VERSION ""

NS_ :

BS_:

BU_: Receiver ChassisBus VehicleBus PartyBus ETH GTW
VAL_TABLE_ OilPumpState 7 "OIL_PUMP_SNA" 6 "OIL_PUMP_FAULTED" 2 "OIL_PUMP_COLD_STARTUP" 1 "OIL_PUMP_ENABLE" 0 "OIL_PUMP_STANDBY" ;

BO_ 3221225472 VECTOR__INDEPENDENT_SIG_MSG: 0 Vector__XXX
 SG_ FrontAxleRPM___ : 0|16@1- (0.1,0) [-3276.8|3276.7] "RPM" Vector__XXX
 SG_ Rear12vInverter266 : 0|8@1+ (0.1,0) [0|25.5] "Volts" Vector__XXX
 SG_ Front12vInverter2E5 : 0|8@1+ (0.1,0) [0|25.5] "Volts" Vector__XXX

BO_ 955 ID3BBUI_power: 2 VehicleBus
 SG_ UI_powerExpected : 0|8@1+ (1,0) [0|100] "kW"  Receiver
 SG_ UI_powerIdeal : 8|8@1+ (1,0) [0|100] "kW"  Receiver

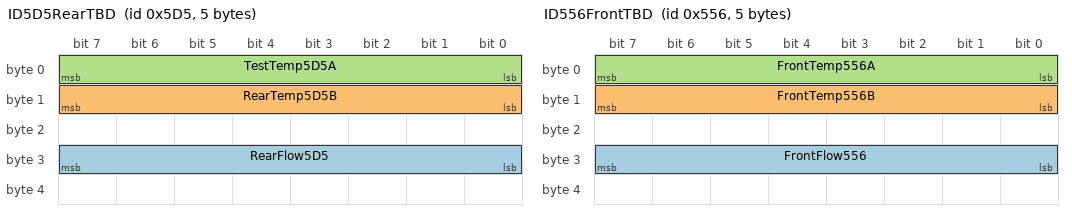
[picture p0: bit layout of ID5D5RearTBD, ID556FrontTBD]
BO_ 1493 ID5D5RearTBD: 5 VehicleBus
 SG_ RearFlow5D5 : 24|8@1+ (0.2,0) [0|0] "LPM"  Receiver
 SG_ RearTemp5D5B : 8|8@1+ (1,-40) [-40|215] "C"  Receiver
 SG_ TestTemp5D5A : 0|8@1+ (1,-40) [-40|215] "C"  Receiver

BO_ 1366 ID556FrontTBD: 5 VehicleBus
 SG_ FrontFlow556 : 24|8@1+ (0.2,0) [0|0] "LPM"  Receiver
 SG_ FrontTemp556B : 8|8@1+ (1,-40) [-40|215] "C"  Receiver
 SG_ FrontTemp556A : 0|8@1+ (1,-40) [-40|215] "C"  Receiver

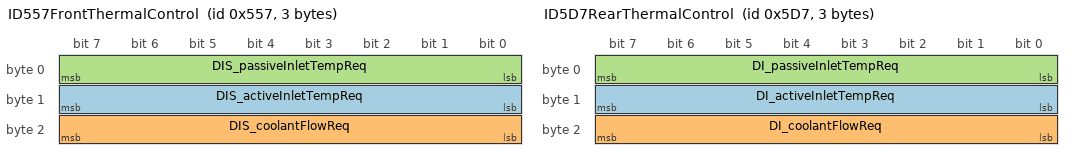
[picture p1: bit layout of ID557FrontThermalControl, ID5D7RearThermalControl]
BO_ 1367 ID557FrontThermalControl: 3 VehicleBus
 SG_ DIS_activeInletTempReq : 8|8@1+ (1,-40) [-40|120] "C"  Receiver
 SG_ DIS_coolantFlowReq : 16|8@1+ (0.2,0) [0|50] "LPM"  Receiver
 SG_ DIS_passiveInletTempReq : 0|8@1+ (1,-40) [-40|120] "C"  Receiver

BO_ 1495 ID5D7RearThermalControl: 3 VehicleBus
 SG_ DI_activeInletTempReq : 8|8@1+ (1,-40) [-40|120] "C"  Receiver
 SG_ DI_coolantFlowReq : 16|8@1+ (0.2,0) [0|50] "LPM"  Receiver
 SG_ DI_passiveInletTempReq : 0|8@1+ (1,-40) [-40|120] "C"  Receiver

BO_ 2005 ID7D5DI_debug: 8 VehicleBus
 SG_ DI_debugSelector M : 0|8@1+ (1,0) [0|255] ""  Receiver
 SG_ DI_aebCancelReason m45 : 32|8@1+ (1,0) [0|255] ""  Receiver
 SG_ DI_aebFaultReason m45 : 16|4@1+ (1,0) [0|15] ""  Receiver
 SG_ DI_aebUnavailableReason m45 : 24|4@1+ (1,0) [0|9] ""  Receiver
 SG_ DI_brakeCpScale m2 : 16|9@1- (0.01,0.5) [-1|2] "N/N"  Receiver
 SG_ DI_brakeSwitchNC m42 : 63|1@1+ (1,0) [0|1] ""  Receiver
 SG_ DI_brakeSwitchNO m42 : 62|1@1+ (1,0) [0|1] ""  Receiver
 SG_ DI_brkStState m50 : 24|3@1+ (1,0) [0|6] ""  Receiver
 SG_ DI_busbarTemp m64 : 16|8@1+ (1,-40) [-40|215] "C"  Receiver
 SG_ DI_controlStack m67 : 56|8@1+ (0.4,0) [0|100] "%"  Receiver
 SG_ DI_cpu100HzAvg m66 : 48|8@1+ (0.4,0) [0|102] "%"  Receiver
 SG_ DI_cpu100HzMax m66 : 40|8@1+ (0.4,0) [0|102] "%"  Receiver
 SG_ DI_cpu100HzMin m66 : 32|8@1+ (0.4,0) [0|102] "%"  Receiver
 SG_ DI_cpu10HzAvg m66 : 24|8@1+ (0.4,0) [0|102] "%"  Receiver
 SG_ DI_cpu10HzMax m66 : 16|8@1+ (0.4,0) [0|102] "%"  Receiver
 SG_ DI_cpu10HzMin m66 : 8|8@1+ (0.4,0) [0|102] "%"  Receiver
 SG_ DI_cpu1HzAvg m128 : 32|8@1+ (0.4,0) [0|102] "%"  Receiver
 SG_ DI_cpu1HzMax m128 : 24|8@1+ (0.4,0) [0|102] "%"  Receiver
 SG_ DI_cpu1HzMin m128 : 16|8@1+ (0.4,0) [0|102] "%"  Receiver
 SG_ DI_cpu1kHzAvg m67 : 24|8@1+ (0.4,0) [0|102] "%"  Receiver
 SG_ DI_cpu1kHzMax m67 : 16|8@1+ (0.4,0) [0|102] "%"  Receiver
 SG_ DI_cpu1kHzMin m67 : 8|8@1+ (0.4,0) [0|102] "%"  Receiver
 SG_ DI_cpu20kHzAvg m67 : 48|8@1+ (0.4,0) [0|102] "%"  Receiver
 SG_ DI_cpu20kHzMax m67 : 40|8@1+ (0.4,0) [0|102] "%"  Receiver
 SG_ DI_cpu20kHzMin m67 : 32|8@1+ (0.4,0) [0|102] "%"  Receiver
 SG_ DI_cpuIDWord0 m131 : 16|16@1+ (1,0) [0|65535] ""  Receiver
 SG_ DI_cpuIDWord1 m132 : 16|16@1+ (1,0) [0|65535] ""  Receiver
 SG_ DI_cpuIDWord2 m132 : 32|16@1+ (1,0) [0|65535] ""  Receiver
 SG_ DI_cpuIDWord3 m132 : 48|16@1+ (1,0) [0|65535] ""  Receiver
 SG_ DI_crc m131 : 32|32@1+ (1,0) [0|4294967295] ""  Receiver
 SG_ DI_currentLimit m41 : 32|16@1+ (0.1,0) [0|6553.5] "A"  Receiver
 SG_ DI_dcCableCurrentEst m37 : 16|16@1- (0.1,0) [-3276.8|3276.7] "A"  Receiver
 SG_ DI_dcCableHeat m47 : 24|16@1+ (0.001,0) [0|65.535] "kA2s"  Receiver
 SG_ DI_dcCapTemp m64 : 8|8@1+ (1,-40) [-40|215] "C"  Receiver
 SG_ DI_dcLinkCapTemp m70 : 32|8@1+ (1,-40) [-40|215] "C"  Receiver
 SG_ DI_decodeHardwareStack m68 : 24|8@1+ (0.4,0) [0|100] "%"  Receiver
 SG_ DI_driveUnitOdometer m69 : 32|32@1+ (10,0) [0|42949672950] "rev"  Receiver
 SG_ DI_eepromStack m68 : 32|8@1+ (0.4,0) [0|100] "%"  Receiver
 SG_ DI_fluxState m42 : 16|4@1+ (1,0) [0|10] ""  Receiver
 SG_ DI_gainScale m37 : 8|8@1+ (0.01,0) [0|2.55] "scale"  Receiver
 SG_ DI_gateDriveState m50 : 10|3@1+ (1,0) [0|4] ""  Receiver
 SG_ DI_gateDriveSupplyState m50 : 8|2@1+ (1,0) [0|3] ""  Receiver
 SG_ DI_hvDcCableTemp m70 : 40|8@1+ (1,-40) [-40|215] "C"  Receiver
 SG_ DI_hwFaultCounter m69 : 8|4@1+ (1,0) [0|15] ""  Receiver
 SG_ DI_idleStack m68 : 16|8@1+ (0.4,0) [0|100] "%"  Receiver
 SG_ DI_immobilizerCondition m64 : 63|1@1+ (1,0) [0|1] ""  Receiver
 SG_ DI_immobilizerStack m68 : 56|8@1+ (0.4,0) [0|100] "%"  Receiver
 SG_ DI_internalAngleFilt m37 : 48|16@1+ (0.0003,0) [0|8] "rad"  Receiver
 SG_ DI_llrScale m42 : 32|8@1+ (0.015,0) [0|3.825] "scale"  Receiver
 SG_ DI_llsScale m42 : 24|8@1+ (0.004,0) [0|1.02] "scale"  Receiver
 SG_ DI_lmScale m36 : 8|8@1+ (0.004,0) [0|1.02] "scale"  Receiver
 SG_ DI_loadAngle m42 : 40|16@1- (0.0003,0) [-4|4] "rad"  Receiver
 SG_ DI_loadAngleMargin m37 : 32|16@1- (0.0003,0) [-4|4] "rad"  Receiver
 SG_ DI_magnetTempEst m47 : 40|8@1+ (1,-40) [-40|180] "C"  Receiver
 SG_ DI_module10HzStack m66 : 56|8@1+ (0.4,0) [0|100] "%"  Receiver
 SG_ DI_motorIA m32 : 16|16@1+ (0.1,0) [0|6553.5] "A"  Receiver
 SG_ DI_motorIAavg m38 : 32|16@1- (0.1,0) [-3276.8|3276.7] "A"  Receiver
 SG_ DI_motorIB m32 : 32|16@1+ (0.1,0) [0|6553.5] "A"  Receiver
 SG_ DI_motorIBavg m38 : 48|16@1- (0.1,0) [-3276.8|3276.7] "A"  Receiver
 SG_ DI_motorIC m32 : 48|16@1+ (0.1,0) [0|6553.5] "A"  Receiver
 SG_ DI_motorType m128 : 8|5@1+ (1,0) [0|26] ""  Receiver
 SG_ DI_motorV m34 : 48|16@1+ (2E-005,0) [0|1.3107] "mindex"  Receiver
 SG_ DI_muSurfHigh m2 : 8|8@1+ (0.005,0) [0|1.2] "N/N"  Receiver
 SG_ DI_negDcBusbarTemp m70 : 48|8@1+ (1,-40) [-40|215] "C"  Receiver
 SG_ DI_offsetA m32 : 8|8@1- (0.1,0) [-12.8|12.7] "A"  Receiver
 SG_ DI_offsetB m33 : 8|8@1- (0.1,0) [-12.8|12.7] "A"  Receiver
 SG_ DI_oilPumpMotorSpeed m46 : 8|8@1+ (40,0) [0|10200] "RPM"  Receiver
 SG_ DI_oilPumpPhaseAdvance m46 : 24|8@1+ (0.4,0) [0|100] "%"  Receiver
 SG_ DI_oilPumpPhaseVoltage m46 : 16|8@1+ (0.1,0) [0|25.4] "V"  Receiver
 SG_ DI_oilPumpPressureEstimateMax m46 : 32|8@1+ (2,0) [0|500] "kPa"  Receiver
 SG_ DI_oilPumpPressureExpectedMin m46 : 40|8@1+ (2,0) [0|500] "kPa"  Receiver
 SG_ DI_opdUnavailableReason m45 : 40|4@1+ (1,0) [0|11] ""  Receiver
 SG_ DI_pcsTemp m64 : 24|8@1+ (1,-40) [-40|215] "C"  Receiver
 SG_ DI_peakFlux m36 : 48|16@1+ (0.0001,0) [0|6.5535] "Wb"  Receiver
 SG_ DI_peakIQref m38 : 16|16@1+ (0.1,0) [0|6553.5] "A"  Receiver
 SG_ DI_pedalPosFilt m2 : 32|8@1+ (0.4,0) [0|100] "%"  Receiver
 SG_ DI_phaseOutBusbarTemp m70 : 8|8@1+ (1,-40) [-40|215] "C"  Receiver
 SG_ DI_phaseOutBusbarWeldTemp m70 : 16|8@1+ (1,-40) [-40|215] "C"  Receiver
 SG_ DI_phaseOutLugTemp m70 : 24|8@1+ (1,-40) [-40|215] "C"  Receiver
 SG_ DI_posDcBusbarTemp m70 : 56|8@1+ (1,-40) [-40|215] "C"  Receiver
 SG_ DI_powerStageSafeState m50 : 13|2@1+ (1,0) [0|3] ""  Receiver
 SG_ DI_pwrSatChargeCurrent m42 : 8|8@1+ (0.4,0) [0|102] "%"  Receiver
 SG_ DI_pwrSatDischargeCurrent m40 : 8|8@1+ (0.4,0) [0|102] "%"  Receiver
 SG_ DI_pwrSatMaxBusVoltage m39 : 48|8@1+ (0.4,0) [0|102] "%"  Receiver
 SG_ DI_pwrSatMaxDischargePower m39 : 16|8@1+ (0.4,0) [0|102] "%"  Receiver
 SG_ DI_pwrSatMaxRegenPower m39 : 24|8@1+ (0.4,0) [0|102] "%"  Receiver
 SG_ DI_pwrSatMinBusVoltage m39 : 56|8@1+ (0.4,0) [0|102] "%"  Receiver
 SG_ DI_resolverClaMIA m48 : 43|1@1+ (1,0) [0|1] ""  Receiver
 SG_ DI_resolverCommonGain m48 : 32|8@1+ (0.025,0) [0|5] "1"  Receiver
 SG_ DI_resolverCosFiltered m52 : 32|8@1- (0.01,0) [-1|1] "1"  Receiver
 SG_ DI_resolverCosRmsSquared m52 : 16|8@1+ (0.005,0) [0|1] "1"  Receiver
 SG_ DI_resolverErrorRmsSquared m52 : 48|8@1+ (0.005,0) [0|1] "1"  Receiver
 SG_ DI_resolverNoCarrier m48 : 41|1@1+ (1,0) [0|1] ""  Receiver
 SG_ DI_resolverNoPhaseLock m48 : 42|1@1+ (1,0) [0|1] ""  Receiver
 SG_ DI_resolverOffsetCos m48 : 8|8@1+ (0.015,0) [0|3.3] "V"  Receiver
 SG_ DI_resolverOffsetSin m48 : 16|8@1+ (0.015,0) [0|3.3] "V"  Receiver
 SG_ DI_resolverPhaseOffset m48 : 24|8@1+ (0.1,7.5) [7.5|32.5] "us"  Receiver
 SG_ DI_resolverReady m48 : 40|1@1+ (1,0) [0|1] ""  Receiver
 SG_ DI_resolverSinFiltered m52 : 40|8@1- (0.01,0) [-1|1] "1"  Receiver
 SG_ DI_resolverSinRmsSquared m52 : 24|8@1+ (0.005,0) [0|1] "1"  Receiver
 SG_ DI_rotorFlux m47 : 8|16@1+ (0.0001,0) [0|6.5535] "Wb"  Receiver
 SG_ DI_rotorMaxMagnetTemp m72 : 16|8@1+ (1,-40) [-40|215] "C"  Receiver
 SG_ DI_rotorOffsetEst m43 : 8|12@1- (0.01,0) [-20|20] "deg"  Receiver
 SG_ DI_rotorOffsetLearningState m63 : 8|4@1+ (1,0) [0|9] ""  Receiver
 SG_ DI_rotorOffsetMean m43 : 20|12@1- (0.01,0) [-20|20] "deg"  Receiver
 SG_ DI_rsScale m34 : 8|8@1+ (0.01,0) [0|2.55] "scale"  Receiver
 SG_ DI_soptMaxCurrentMagSqrd m49 : 40|16@1+ (100,0) [0|6553500] "A2"  Receiver
 SG_ DI_soptTimeToOff m49 : 24|11@1+ (0.05,0) [0|100] "ms"  Receiver
 SG_ DI_soptTimeToTrip m49 : 8|8@1+ (0.05,0) [0|10] "ms"  Receiver
 SG_ DI_soptTripDelay m49 : 16|8@1+ (0.05,0) [0|10] "ms"  Receiver
 SG_ DI_ssmState m38 : 8|4@1+ (1,0) [0|8] ""  Receiver
 SG_ DI_statorEndWindingTemp m72 : 8|8@1+ (1,-40) [-40|215] "C"  Receiver
 SG_ DI_statorFluxFdb m35 : 32|16@1+ (0.0001,0) [0|6.5535] "Wb"  Receiver
 SG_ DI_statorFluxRef m35 : 16|16@1+ (0.0001,0) [0|6.5535] "Wb"  Receiver
 SG_ DI_statorIDfdb m33 : 32|16@1- (0.1,0) [-3276.8|3276.7] "A"  Receiver
 SG_ DI_statorIDref m33 : 16|16@1- (0.1,0) [-3276.8|3276.7] "A"  Receiver
 SG_ DI_statorIQfdb m34 : 32|16@1- (0.1,0) [-3276.8|3276.7] "A"  Receiver
 SG_ DI_statorIQref m34 : 16|16@1- (0.1,0) [-3276.8|3276.7] "A"  Receiver
 SG_ DI_statorResistanceEst m47 : 48|11@1+ (5E-005,0) [0|0.10235] "Ohm"  Receiver
 SG_ DI_statorTemp1 m64 : 32|8@1+ (1,-40) [-40|215] "C"  Receiver
 SG_ DI_statorTemp2 m64 : 40|8@1+ (1,-40) [-40|215] "C"  Receiver
 SG_ DI_statorVD m36 : 32|16@1- (4E-005,0) [-1.31072|1.31068] "mindex"  Receiver
 SG_ DI_statorVDFiltered m63 : 16|16@1- (4E-005,0) [-1.31072|1.31068] "mindex"  Receiver
 SG_ DI_statorVQ m36 : 16|16@1- (4E-005,0) [-1.31072|1.31068] "mindex"  Receiver
 SG_ DI_statorVQFiltered m63 : 32|16@1- (4E-005,0) [-1.31072|1.31068] "mindex"  Receiver
 SG_ DI_sysHeatPowerOptimal m50 : 16|8@1+ (0.08,0) [0|20] "kW"  Receiver
 SG_ DI_sysPedalMaxTorque m44 : 22|14@1+ (0.1,0) [0|1638.3] "Nm"  Receiver
 SG_ DI_sysPedalMinTorque m44 : 8|14@1+ (0.1,-1638.3) [-1638.3|0] "Nm"  Receiver
 SG_ DI_sysPostPedalMaxTorque m44 : 50|14@1+ (0.1,0) [0|1638.3] "Nm"  Receiver
 SG_ DI_sysPostPedalMinTorque m44 : 36|14@1+ (0.1,-1638.3) [-1638.3|0] "Nm"  Receiver
 SG_ DI_systemStack m68 : 8|8@1+ (0.4,0) [0|100] "%"  Receiver
 SG_ DI_systemTorqueCommand m35 : 48|16@1- (0.035,0) [-1146.88|1146.845] "Nm"  Receiver
 SG_ DI_tcMaxRequest m40 : 16|8@1+ (5,0) [0|1275] "Nm"  Receiver
 SG_ DI_tcMinRequest m40 : 24|8@1+ (5,0) [0|1275] "Nm"  Receiver
 SG_ DI_torquePedalMax m51 : 28|12@1+ (2,0) [0|7500] "Nm"  Receiver
 SG_ DI_torquePedalMin m51 : 16|12@1+ (2,-7500) [-7500|0] "Nm"  Receiver
 SG_ DI_torquePerAmp m33 : 48|16@1+ (0.0001,0) [0|6.5535] "Nm/A"  Receiver
 SG_ DI_torquePostPedalMax m51 : 52|12@1+ (2,0) [0|7500] "Nm"  Receiver
 SG_ DI_torquePostPedalMin m51 : 40|12@1+ (2,-7500) [-7500|0] "Nm"  Receiver
 SG_ DI_tqSatMotorCurrent m39 : 40|8@1+ (0.4,0) [0|102] "%"  Receiver
 SG_ DI_tqSatMotorVoltage m39 : 32|8@1+ (0.4,0) [0|102] "%"  Receiver
 SG_ DI_tqSatThermal m39 : 8|8@1+ (0.4,0) [0|102] "%"  Receiver
 SG_ DI_tqSatUiDriveTorque m40 : 32|8@1+ (0.4,0) [0|102] "%"  Receiver
 SG_ DI_tqSatUiRegenTorque m40 : 40|8@1+ (0.4,0) [0|102] "%"  Receiver
 SG_ DI_tqScaleDifferential m35 : 8|8@1+ (0.4,0) [0|102] "%"  Receiver
 SG_ DI_tqScaleMaxMotorSpeed m40 : 48|8@1+ (0.4,0) [0|102] "%"  Receiver
 SG_ DI_tqScaleShift m40 : 56|8@1+ (0.4,0) [0|102] "%"  Receiver
 SG_ DI_udsStack m68 : 40|8@1+ (0.4,0) [0|100] "%"  Receiver
 SG_ DI_usmState m38 : 12|3@1+ (1,0) [0|7] ""  Receiver
 SG_ DI_veMassInvRaw m41 : 8|12@1+ (1E-007,0.0001) [0.0001|0.0005] "1/kg"  Receiver
 SG_ DI_veResForce m41 : 20|12@1- (0.0005,0) [-1.024|1.0235] "G"  Receiver
 SG_ DI_velocityEstimatorState m65 : 8|3@1+ (1,0) [0|4] ""  Receiver
 SG_ DI_wasteCurrentLimit m41 : 48|16@1+ (0.1,0) [0|6553.5] "A"  Receiver
 SG_ DI_xcpStack m68 : 48|8@1+ (0.4,0) [0|100] "%"  Receiver

BO_ 1879 ID757DIS_debug: 8 VehicleBus
 SG_ DIS_debugSelector M : 0|8@1+ (1,0) [0|255] ""  Receiver
 SG_ DIS_brakeSwitchNC m42 : 63|1@1+ (1,0) [0|1] ""  Receiver
 SG_ DIS_brakeSwitchNO m42 : 62|1@1+ (1,0) [0|1] ""  Receiver
 SG_ DIS_busbarTemp m64 : 16|8@1+ (1,-40) [-40|215] "C"  Receiver
 SG_ DIS_controlStack m67 : 56|8@1+ (0.4,0) [0|100] "%"  Receiver
 SG_ DIS_cpu100HzAvg m66 : 48|8@1+ (0.4,0) [0|102] "%"  Receiver
 SG_ DIS_cpu100HzMax m66 : 40|8@1+ (0.4,0) [0|102] "%"  Receiver
 SG_ DIS_cpu100HzMin m66 : 32|8@1+ (0.4,0) [0|102] "%"  Receiver
 SG_ DIS_cpu10HzAvg m66 : 24|8@1+ (0.4,0) [0|102] "%"  Receiver
 SG_ DIS_cpu10HzMax m66 : 16|8@1+ (0.4,0) [0|102] "%"  Receiver
 SG_ DIS_cpu10HzMin m66 : 8|8@1+ (0.4,0) [0|102] "%"  Receiver
 SG_ DIS_cpu1HzAvg m128 : 32|8@1+ (0.4,0) [0|102] "%"  Receiver
 SG_ DIS_cpu1HzMax m128 : 24|8@1+ (0.4,0) [0|102] "%"  Receiver
 SG_ DIS_cpu1HzMin m128 : 16|8@1+ (0.4,0) [0|102] "%"  Receiver
 SG_ DIS_cpu1kHzAvg m67 : 24|8@1+ (0.4,0) [0|102] "%"  Receiver
 SG_ DIS_cpu1kHzMax m67 : 16|8@1+ (0.4,0) [0|102] "%"  Receiver
 SG_ DIS_cpu1kHzMin m67 : 8|8@1+ (0.4,0) [0|102] "%"  Receiver
 SG_ DIS_cpu20kHzAvg m67 : 48|8@1+ (0.4,0) [0|102] "%"  Receiver
 SG_ DIS_cpu20kHzMax m67 : 40|8@1+ (0.4,0) [0|102] "%"  Receiver
 SG_ DIS_cpu20kHzMin m67 : 32|8@1+ (0.4,0) [0|102] "%"  Receiver
 SG_ DIS_cpuIDWord0 m131 : 16|16@1+ (1,0) [0|65535] ""  Receiver
 SG_ DIS_cpuIDWord1 m132 : 16|16@1+ (1,0) [0|65535] ""  Receiver
 SG_ DIS_cpuIDWord2 m132 : 32|16@1+ (1,0) [0|65535] ""  Receiver
 SG_ DIS_cpuIDWord3 m132 : 48|16@1+ (1,0) [0|65535] ""  Receiver
 SG_ DIS_crc m131 : 32|32@1+ (1,0) [0|4294967295] ""  Receiver
 SG_ DIS_currentLimit m41 : 32|16@1+ (0.1,0) [0|6553.5] "A"  Receiver
 SG_ DIS_dcCableCurrentEst m37 : 16|16@1- (0.1,0) [-3276.8|3276.7] "A"  Receiver
 SG_ DIS_dcCableHeat m47 : 24|16@1+ (0.001,0) [0|65.535] "kA2s"  Receiver
 SG_ DIS_dcCapTemp m64 : 8|8@1+ (1,-40) [-40|215] "C"  Receiver
 SG_ DIS_dcLinkCapTemp m70 : 32|8@1+ (1,-40) [-40|215] "C"  Receiver
 SG_ DIS_decodeHardwareStack m68 : 24|8@1+ (0.4,0) [0|100] "%"  Receiver
 SG_ DIS_driveUnitOdometer m69 : 32|32@1+ (10,0) [0|42949672950] "rev"  Receiver
 SG_ DIS_eepromStack m68 : 32|8@1+ (0.4,0) [0|100] "%"  Receiver
 SG_ DIS_fluxState m42 : 16|4@1+ (1,0) [0|10] ""  Receiver
 SG_ DIS_gainScale m37 : 8|8@1+ (0.01,0) [0|2.55] "scale"  Receiver
 SG_ DIS_gateDriveState m50 : 10|3@1+ (1,0) [0|4] ""  Receiver
 SG_ DIS_gateDriveSupplyState m50 : 8|2@1+ (1,0) [0|3] ""  Receiver
 SG_ DIS_hvDcCableTemp m70 : 40|8@1+ (1,-40) [-40|215] "C"  Receiver
 SG_ DIS_hwFaultCounter m69 : 8|4@1+ (1,0) [0|15] ""  Receiver
 SG_ DIS_idleStack m68 : 16|8@1+ (0.4,0) [0|100] "%"  Receiver
 SG_ DIS_internalAngleFilt m37 : 48|16@1+ (0.0003,0) [0|8] "rad"  Receiver
 SG_ DIS_llrScale m42 : 32|8@1+ (0.015,0) [0|3.825] "scale"  Receiver
 SG_ DIS_llsScale m42 : 24|8@1+ (0.004,0) [0|1.02] "scale"  Receiver
 SG_ DIS_lmScale m36 : 8|8@1+ (0.004,0) [0|1.02] "scale"  Receiver
 SG_ DIS_loadAngle m42 : 40|16@1- (0.0003,0) [-4|4] "rad"  Receiver
 SG_ DIS_loadAngleMargin m37 : 32|16@1- (0.0003,0) [-4|4] "rad"  Receiver
 SG_ DIS_magnetTempEst m47 : 40|8@1+ (1,-40) [-40|180] "C"  Receiver
 SG_ DIS_module10HzStack m66 : 56|8@1+ (0.4,0) [0|100] "%"  Receiver
 SG_ DIS_motorIA m32 : 16|16@1+ (0.1,0) [0|6553.5] "A"  Receiver
 SG_ DIS_motorIAavg m38 : 32|16@1- (0.1,0) [-3276.8|3276.7] "A"  Receiver
 SG_ DIS_motorIB m32 : 32|16@1+ (0.1,0) [0|6553.5] "A"  Receiver
 SG_ DIS_motorIBavg m38 : 48|16@1- (0.1,0) [-3276.8|3276.7] "A"  Receiver
 SG_ DIS_motorIC m32 : 48|16@1+ (0.1,0) [0|6553.5] "A"  Receiver
 SG_ DIS_motorType m128 : 8|5@1+ (1,0) [0|26] ""  Receiver
 SG_ DIS_motorV m34 : 48|16@1+ (2E-005,0) [0|1.3107] "mindex"  Receiver
 SG_ DIS_negDcBusbarTemp m70 : 48|8@1+ (1,-40) [-40|215] "C"  Receiver
 SG_ DIS_offsetA m32 : 8|8@1- (0.1,0) [-12.8|12.7] "A"  Receiver
 SG_ DIS_offsetB m33 : 8|8@1- (0.1,0) [-12.8|12.7] "A"  Receiver
 SG_ DIS_oilPumpMotorSpeed m46 : 8|8@1+ (40,0) [0|10200] "RPM"  Receiver
 SG_ DIS_oilPumpPhaseAdvance m46 : 24|8@1+ (0.4,0) [0|100] "%"  Receiver
 SG_ DIS_oilPumpPhaseVoltage m46 : 16|8@1+ (0.1,0) [0|25.4] "V"  Receiver
 SG_ DIS_oilPumpPressureEstimateMax m46 : 32|8@1+ (2,0) [0|500] "kPa"  Receiver
 SG_ DIS_oilPumpPressureExpectedMin m46 : 40|8@1+ (2,0) [0|500] "kPa"  Receiver
 SG_ DIS_pcsTemp m64 : 24|8@1+ (1,-40) [-40|215] "C"  Receiver
 SG_ DIS_peakFlux m36 : 48|16@1+ (0.0001,0) [0|6.5535] "Wb"  Receiver
 SG_ DIS_peakIQref m38 : 16|16@1+ (0.1,0) [0|6553.5] "A"  Receiver
 SG_ DIS_phaseOutBusbarTemp m70 : 8|8@1+ (1,-40) [-40|215] "C"  Receiver
 SG_ DIS_phaseOutBusbarWeldTemp m70 : 16|8@1+ (1,-40) [-40|215] "C"  Receiver
 SG_ DIS_phaseOutLugTemp m70 : 24|8@1+ (1,-40) [-40|215] "C"  Receiver
 SG_ DIS_posDcBusbarTemp m70 : 56|8@1+ (1,-40) [-40|215] "C"  Receiver
 SG_ DIS_powerStageSafeState m50 : 13|2@1+ (1,0) [0|3] ""  Receiver
 SG_ DIS_pwrSatChargeCurrent m42 : 8|8@1+ (0.4,0) [0|102] "%"  Receiver
 SG_ DIS_pwrSatDischargeCurrent m40 : 8|8@1+ (0.4,0) [0|102] "%"  Receiver
 SG_ DIS_pwrSatMaxBusVoltage m39 : 48|8@1+ (0.4,0) [0|102] "%"  Receiver
 SG_ DIS_pwrSatMaxDischargePower m39 : 16|8@1+ (0.4,0) [0|102] "%"  Receiver
 SG_ DIS_pwrSatMaxRegenPower m39 : 24|8@1+ (0.4,0) [0|102] "%"  Receiver
 SG_ DIS_pwrSatMinBusVoltage m39 : 56|8@1+ (0.4,0) [0|102] "%"  Receiver
 SG_ DIS_resolverClaMIA m48 : 43|1@1+ (1,0) [0|1] ""  Receiver
 SG_ DIS_resolverCommonGain m48 : 32|8@1+ (0.025,0) [0|5] "1"  Receiver
 SG_ DIS_resolverCosFiltered m52 : 32|8@1- (0.01,0) [-1|1] "1"  Receiver
 SG_ DIS_resolverCosRmsSquared m52 : 16|8@1+ (0.005,0) [0|1] "1"  Receiver
 SG_ DIS_resolverErrorRmsSquared m52 : 48|8@1+ (0.005,0) [0|1] "1"  Receiver
 SG_ DIS_resolverNoCarrier m48 : 41|1@1+ (1,0) [0|1] ""  Receiver
 SG_ DIS_resolverNoPhaseLock m48 : 42|1@1+ (1,0) [0|1] ""  Receiver
 SG_ DIS_resolverOffsetCos m48 : 8|8@1+ (0.015,0) [0|3.3] "V"  Receiver
 SG_ DIS_resolverOffsetSin m48 : 16|8@1+ (0.015,0) [0|3.3] "V"  Receiver
 SG_ DIS_resolverPhaseOffset m48 : 24|8@1+ (0.1,7.5) [7.5|32.5] "us"  Receiver
 SG_ DIS_resolverReady m48 : 40|1@1+ (1,0) [0|1] ""  Receiver
 SG_ DIS_resolverSinFiltered m52 : 40|8@1- (0.01,0) [-1|1] "1"  Receiver
 SG_ DIS_resolverSinRmsSquared m52 : 24|8@1+ (0.005,0) [0|1] "1"  Receiver
 SG_ DIS_rotorFlux m47 : 8|16@1+ (0.0001,0) [0|6.5535] "Wb"  Receiver
 SG_ DIS_rotorMaxMagnetTemp m72 : 16|8@1+ (1,-40) [-40|215] "C"  Receiver
 SG_ DIS_rsScale m34 : 8|8@1+ (0.01,0) [0|2.55] "scale"  Receiver
 SG_ DIS_soptMaxCurrentMagSqrd m49 : 48|16@1+ (100,0) [0|6553500] "A2"  Receiver
 SG_ DIS_soptTimeToOff m49 : 32|11@1+ (0.05,0) [0|100] "ms"  Receiver
 SG_ DIS_soptTimeToTrip m49 : 8|8@1+ (0.05,0) [0|10] "ms"  Receiver
 SG_ DIS_soptTripDelay m49 : 16|8@1+ (0.05,0) [0|10] "ms"  Receiver
 SG_ DIS_statorEndWindingTemp m72 : 8|8@1+ (1,-40) [-40|215] "C"  Receiver
 SG_ DIS_statorFluxFdb m35 : 32|16@1+ (0.0001,0) [0|6.5535] "Wb"  Receiver
 SG_ DIS_statorFluxRef m35 : 16|16@1+ (0.0001,0) [0|6.5535] "Wb"  Receiver
 SG_ DIS_statorIDfdb m33 : 32|16@1- (0.1,0) [-3276.8|3276.7] "A"  Receiver
 SG_ DIS_statorIDref m33 : 16|16@1- (0.1,0) [-3276.8|3276.7] "A"  Receiver
 SG_ DIS_statorIQfdb m34 : 32|16@1- (0.1,0) [-3276.8|3276.7] "A"  Receiver
 SG_ DIS_statorIQref m34 : 16|16@1- (0.1,0) [-3276.8|3276.7] "A"  Receiver
 SG_ DIS_statorResistanceEst m47 : 48|11@1+ (5E-005,0) [0|0.10235] "Ohm"  Receiver
 SG_ DIS_statorTemp1 m64 : 32|8@1+ (1,-40) [-40|215] "C"  Receiver
 SG_ DIS_statorTemp2 m64 : 40|8@1+ (1,-40) [-40|215] "C"  Receiver
 SG_ DIS_statorVD m36 : 32|16@1- (4E-005,0) [-1.31072|1.31068] "mindex"  Receiver
 SG_ DIS_statorVQ m36 : 16|16@1- (4E-005,0) [-1.31072|1.31068] "mindex"  Receiver
 SG_ DIS_systemStack m68 : 8|8@1+ (0.4,0) [0|100] "%"  Receiver
 SG_ DIS_systemTorqueCommand m35 : 48|16@1- (0.035,0) [-1146.88|1146.845] "Nm"  Receiver
 SG_ DIS_tcMaxRequest m40 : 16|8@1+ (5,0) [0|1275] "Nm"  Receiver
 SG_ DIS_tcMinRequest m40 : 24|8@1+ (5,0) [0|1275] "Nm"  Receiver
 SG_ DIS_torquePerAmp m33 : 48|16@1+ (0.0001,0) [0|6.5535] "Nm/A"  Receiver
 SG_ DIS_tqSatMotorCurrent m39 : 40|8@1+ (0.4,0) [0|102] "%"  Receiver
 SG_ DIS_tqSatMotorVoltage m39 : 32|8@1+ (0.4,0) [0|102] "%"  Receiver
 SG_ DIS_tqSatThermal m39 : 8|8@1+ (0.4,0) [0|102] "%"  Receiver
 SG_ DIS_tqSatUiDriveTorque m40 : 32|8@1+ (0.4,0) [0|102] "%"  Receiver
 SG_ DIS_tqSatUiRegenTorque m40 : 40|8@1+ (0.4,0) [0|102] "%"  Receiver
 SG_ DIS_tqScaleDifferential m35 : 8|8@1+ (0.4,0) [0|102] "%"  Receiver
 SG_ DIS_tqScaleMaxMotorSpeed m40 : 48|8@1+ (0.4,0) [0|102] "%"  Receiver
 SG_ DIS_tqScaleShift m40 : 56|8@1+ (0.4,0) [0|102] "%"  Receiver
 SG_ DIS_udsStack m68 : 40|8@1+ (0.4,0) [0|100] "%"  Receiver
 SG_ DIS_usmState m38 : 12|3@1+ (1,0) [0|7] ""  Receiver
 SG_ DIS_velocityEstimatorState m65 : 8|3@1+ (1,0) [0|4] ""  Receiver
 SG_ DIS_wasteCurrentLimit m41 : 48|16@1+ (0.1,0) [0|6553.5] "A"  Receiver
 SG_ DIS_xcpStack m68 : 48|8@1+ (0.4,0) [0|100] "%"  Receiver

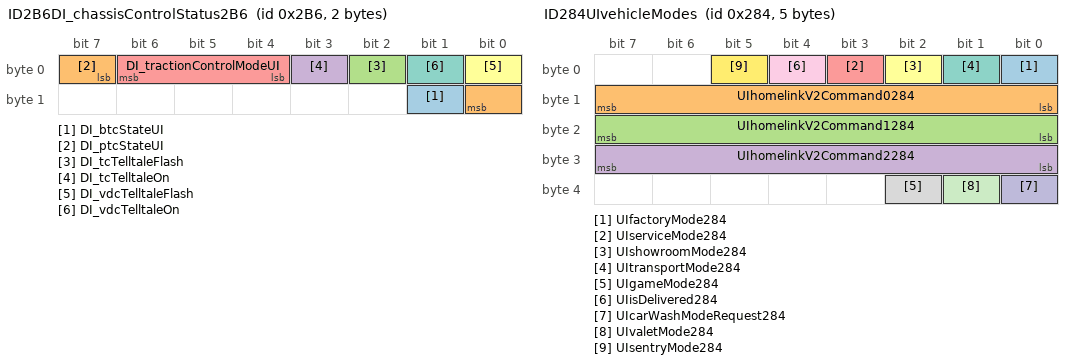
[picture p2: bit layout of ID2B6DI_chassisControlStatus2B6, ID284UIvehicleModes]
BO_ 694 ID2B6DI_chassisControlStatus2B6: 2 GTW
 SG_ DI_btcStateUI : 9|1@1+ (1,0) [0|0] ""  ETH
 SG_ DI_ptcStateUI : 7|2@1+ (1,0) [0|0] ""  ETH
 SG_ DI_tcTelltaleFlash : 2|1@1+ (1,0) [0|0] ""  ETH
 SG_ DI_tcTelltaleOn : 3|1@1+ (1,0) [0|0] ""  ETH
 SG_ DI_tractionControlModeUI : 4|3@1+ (1,0) [0|7] ""  ETH
 SG_ DI_vdcTelltaleFlash : 0|1@1+ (1,0) [0|0] ""  ETH
 SG_ DI_vdcTelltaleOn : 1|1@1+ (1,0) [0|0] ""  ETH

BO_ 644 ID284UIvehicleModes: 5 VehicleBus
 SG_ UIfactoryMode284 : 0|1@1+ (1,0) [0|0] ""  Receiver
 SG_ UIhomelinkV2Command0284 : 8|8@1+ (1,0) [0|0] ""  Receiver
 SG_ UIhomelinkV2Command1284 : 16|8@1+ (1,0) [0|0] ""  Receiver
 SG_ UIhomelinkV2Command2284 : 24|8@1+ (1,0) [0|0] ""  Receiver
 SG_ UIserviceMode284 : 3|1@1+ (1,0) [0|0] ""  Receiver
 SG_ UIshowroomMode284 : 2|1@1+ (1,0) [0|0] ""  Receiver
 SG_ UItransportMode284 : 1|1@1+ (1,0) [0|0] ""  Receiver
 SG_ UIgameMode284 : 34|1@1+ (1,0) [0|0] ""  Receiver
 SG_ UIisDelivered284 : 4|1@1+ (1,0) [0|0] ""  Receiver
 SG_ UIcarWashModeRequest284 : 32|1@1+ (1,0) [0|0] ""  Receiver
 SG_ UIvaletMode284 : 33|1@1+ (1,0) [0|0] ""  Receiver
 SG_ UIsentryMode284 : 5|1@1+ (1,0) [0|0] ""  Receiver

BO_ 545 ID221VCFrontLVPowerState: 8 VehicleBus
 SG_ VCFrontLVPowerStateChecksum : 56|8@1+ (1,0) [0|0] ""  Receiver
 SG_ VCFrontLVPowerStateCounter : 52|4@1+ (1,0) [0|0] ""  Receiver
 SG_ VCFrontLVPowerStateIndex M : 0|5@1+ (1,0) [0|0] ""  Receiver
 SG_ VCFrontvehiclePowerState221 : 5|2@1+ (1,0) [0|0] ""  Receiver
 SG_ VCFrontparkLVState221 m0 : 8|2@1+ (1,0) [0|0] ""  Receiver
 SG_ VCFrontespLVState221 m0 : 10|2@1+ (1,0) [0|0] ""  Receiver
 SG_ VCFrontradcLVState221 m0 : 12|2@1+ (1,0) [0|0] ""  Receiver
 SG_ VCFronthvacCompLVState221 m0 : 14|2@1+ (1,0) [0|0] ""  Receiver
 SG_ VCFrontptcLVReq221 m0 : 16|2@1+ (1,0) [0|0] ""  Receiver
 SG_ VCFrontsccmLVReq221 m0 : 18|2@1+ (1,0) [0|0] ""  Receiver
 SG_ VCFronttpmsLVReq221 m0 : 20|2@1+ (1,0) [0|0] ""  Receiver
 SG_ VCFrontrcmLVReq221 m0 : 22|2@1+ (1,0) [0|0] ""  Receiver
 SG_ VCFrontiBoosterLVState221 m0 : 24|2@1+ (1,0) [0|0] ""  Receiver
 SG_ VCFronttunerLVReq221 m0 : 26|2@1+ (1,0) [0|0] ""  Receiver
 SG_ VCFrontamplifierLVReq221 m0 : 28|2@1+ (1,0) [0|0] ""  Receiver
 SG_ VCFrontdas1HighCurrentLVState221 m0 : 30|2@1+ (1,0) [0|0] ""  Receiver
 SG_ VCFrontdas2HighCurrentLVState221 m0 : 32|2@1+ (1,0) [0|0] ""  Receiver
 SG_ VCFrontdiLVReq221 m0 : 34|2@1+ (1,0) [0|0] ""  Receiver
 SG_ VCFrontdisLVState221 m0 : 36|2@1+ (1,0) [0|0] ""  Receiver
 SG_ VCFrontoilPumpFrontLVState221 m0 : 38|2@1+ (1,0) [0|0] ""  Receiver
 SG_ VCFrontoilPumpRearLVReq221 m0 : 40|2@1+ (1,0) [0|0] ""  Receiver
 SG_ VCFrontocsLVReq221 m0 : 42|2@1+ (1,0) [0|0] ""  Receiver
 SG_ VCFrontvcleftHiCurrentLVState221 m0 : 44|2@1+ (1,0) [0|0] ""  Receiver
 SG_ VCFrontvcrightHiCurrentLVState22 m0 : 46|2@1+ (1,0) [0|0] ""  Receiver
 SG_ VCFrontuiHiCurrentLVState221 m0 : 48|2@1+ (1,0) [0|0] ""  Receiver
 SG_ VCFrontuiAudioLVState221 m0 : 50|2@1+ (1,0) [0|0] ""  Receiver
 SG_ VCFrontcpLVReq221 m1 : 8|2@1+ (1,0) [0|0] ""  Receiver
 SG_ VCFrontepasLVState221 m1 : 10|2@1+ (1,0) [0|0] ""  Receiver
 SG_ VCFrontHVcontactorLVReq221 m1 : 12|2@1+ (1,0) [0|0] ""  Receiver
 SG_ VCFronttasLVState221 m1 : 14|2@1+ (1,0) [0|0] ""  Receiver
 SG_ VCFrontpcsLVState221 m1 : 16|2@1+ (1,0) [0|0] ""  Receiver

BO_ 753 ID2F1VCFrontEFuseDebugStatus: 8 VehicleBus
 SG_ VCFrontEFuseDebugStatusIndex M : 0|5@1+ (1,0) [0|0] ""  Receiver
 SG_ VCFrontrightControllerState m0 : 8|2@1+ (1,0) [0|0] ""  Receiver
 SG_ VCFrontrightControllerFault m0 : 10|1@1+ (1,0) [0|0] ""  Receiver
 SG_ VCFrontvcrightSelfTestResult m0 : 11|4@1+ (1,0) [0|0] ""  Receiver
 SG_ VCFrontrightControllerTemp m0 : 15|11@1+ (0.125,-40) [0|0] "C"  Receiver
 SG_ VCFrontrightControllerVoltage m0 : 31|16@1+ (0.1,0) [0|0] "V"  Receiver
 SG_ VCFrontrightControllerCurrent m0 : 47|16@1+ (0.1,0) [0|0] "A"  Receiver
 SG_ VCFrontleftControllerState m1 : 8|2@1+ (1,0) [0|0] ""  Receiver
 SG_ VCFrontleftControllerFault m1 : 10|1@1+ (1,0) [0|0] ""  Receiver
 SG_ VCFrontvcleftSelfTestResult m1 : 11|4@1+ (1,0) [0|0] ""  Receiver
 SG_ VCFrontleftControllerTemp m1 : 15|11@1+ (0.125,-40) [0|0] "C"  Receiver
 SG_ VCFrontleftControllerVoltage m1 : 31|16@1+ (0.1,0) [0|0] "V"  Receiver
 SG_ VCFrontleftControllerCurrent m1 : 47|16@1+ (0.1,0) [0|0] "A"  Receiver
 SG_ VCFrontPCSState m2 : 8|2@1+ (1,0) [0|0] ""  Receiver
 SG_ VCFrontPCSFault m2 : 10|1@1+ (1,0) [0|0] ""  Receiver
 SG_ VCFrontpcsSelfTestResult m2 : 11|4@1+ (1,0) [0|0] ""  Receiver
 SG_ VCFrontPCSTemp m2 : 15|11@1+ (0.125,-40) [0|0] "C"  Receiver
 SG_ VCFrontPCSVoltage m2 : 31|16@1+ (0.1,0) [0|0] "V"  Receiver
 SG_ VCFrontPCSCurrent m2 : 47|16@1- (0.1,0) [0|0] "A"  Receiver
 SG_ VCFrontiBoosterState m3 : 8|2@1+ (1,0) [0|0] ""  Receiver
 SG_ VCFrontiBoosterFault m3 : 10|1@1+ (1,0) [0|0] ""  Receiver
 SG_ VCFrontiBoosterSelfTestResult m3 : 11|4@1+ (1,0) [0|0] ""  Receiver
 SG_ VCFrontiBoosterTemp m3 : 15|11@1+ (0.125,-40) [0|0] "C"  Receiver
 SG_ VCFrontiBoosterVoltage m3 : 31|16@1+ (0.1,0) [0|0] "V"  Receiver
 SG_ VCFrontiBoosterCurrent m3 : 47|16@1+ (0.1,0) [0|0] "A"  Receiver
 SG_ VCFrontEPAS3PState m4 : 8|2@1+ (1,0) [0|0] ""  Receiver
 SG_ VCFrontEPAS3PFault m4 : 10|1@1+ (1,0) [0|0] ""  Receiver
 SG_ VCFrontEPAS3PSelfTestResult m4 : 11|4@1+ (1,0) [0|0] ""  Receiver
 SG_ VCFrontEPAS3PTemp m4 : 15|11@1+ (0.125,-40) [0|0] "C"  Receiver
 SG_ VCFrontEPAS3PVoltage m4 : 31|16@1+ (0.1,0) [0|0] "V"  Receiver
 SG_ VCFrontEPAS3PCurrent m4 : 47|16@1+ (0.1,0) [0|0] "A"  Receiver
 SG_ VCFrontEPAS3SState m5 : 8|2@1+ (1,0) [0|0] ""  Receiver
 SG_ VCFrontEPAS3SFault m5 : 10|1@1+ (1,0) [0|0] ""  Receiver
 SG_ VCFrontEPAS3SSelfTestResult m5 : 11|4@1+ (1,0) [0|0] ""  Receiver
 SG_ VCFrontEPAS3STemp m5 : 15|11@1+ (0.125,-40) [0|0] "C"  Receiver
 SG_ VCFrontEPAS3SVoltage m5 : 31|16@1+ (0.1,0) [0|0] "V"  Receiver
 SG_ VCFrontEPAS3SCurrent m5 : 47|16@1+ (0.1,0) [0|0] "A"  Receiver
 SG_ VCFrontESPMotorState m6 : 8|2@1+ (1,0) [0|0] ""  Receiver
 SG_ VCFrontESPMotorFault m6 : 10|1@1+ (1,0) [0|0] ""  Receiver
 SG_ VCFrontESPMotorSelfTestResult m6 : 11|4@1+ (1,0) [0|0] ""  Receiver
 SG_ VCFrontESPMotorTemp m6 : 15|11@1+ (0.125,-40) [0|0] "C"  Receiver
 SG_ VCFrontESPMotorVoltage m6 : 31|16@1+ (0.1,0) [0|0] "V"  Receiver
 SG_ VCFrontESPMotorCurrent m6 : 47|16@1+ (0.1,0) [0|0] "A"  Receiver
 SG_ VCFrontESPValveState m7 : 8|2@1+ (1,0) [0|0] ""  Receiver
 SG_ VCFrontESPValveFault m7 : 10|1@1+ (1,0) [0|0] ""  Receiver
 SG_ VCFrontESPValveTemp m7 : 12|11@1+ (0.125,-40) [0|0] "C"  Receiver
 SG_ VCFrontESPValveVoltage m7 : 28|16@1+ (0.1,0) [0|0] "V"  Receiver
 SG_ VCFrontESPValveCurrent m7 : 44|16@1+ (0.1,0) [0|0] "A"  Receiver
 SG_ VCFrontautopilot1State m8 : 8|2@1+ (1,0) [0|0] ""  Receiver
 SG_ VCFrontautopilot1Fault m8 : 10|1@1+ (1,0) [0|0] ""  Receiver
 SG_ VCFrontautopilot1Temp m8 : 11|11@1+ (0.125,-40) [0|0] "C"  Receiver
 SG_ VCFrontautopilot1Voltage m8 : 27|16@1+ (0.1,0) [0|0] "V"  Receiver
 SG_ VCFrontautopilot1Current m8 : 43|16@1+ (0.1,0) [0|0] "A"  Receiver
 SG_ VCFrontautopilot2State m9 : 8|2@1+ (1,0) [0|0] ""  Receiver
 SG_ VCFrontautopilot2Fault m9 : 10|1@1+ (1,0) [0|0] ""  Receiver
 SG_ VCFrontautopilot2Temp m9 : 11|11@1+ (0.125,-40) [0|0] "C"  Receiver
 SG_ VCFrontautopilot2Voltage m9 : 27|16@1+ (0.1,0) [0|0] "V"  Receiver
 SG_ VCFrontautopilot2Current m9 : 43|16@1+ (0.1,0) [0|0] "A"  Receiver
 SG_ VCFrontsleepBypassState m10 : 8|1@1+ (1,0) [0|0] ""  Receiver
 SG_ VCFrontsleepBypassFault m10 : 9|1@1+ (1,0) [0|0] ""  Receiver
 SG_ VCFrontsleepBypassVoltage m10 : 10|16@1+ (0.1,0) [0|0] "V"  Receiver
 SG_ VCFrontsleepBypassCurrent m10 : 26|16@1+ (0.1,0) [0|0] "A"  Receiver
 SG_ VCFrontuiAudioState m11 : 5|1@1+ (1,0) [0|0] ""  Receiver
 SG_ VCFrontuiAudioFault m11 : 6|1@1+ (1,0) [0|0] ""  Receiver
 SG_ VCFrontuiAudioCurrent m11 : 8|16@1+ (0.1,0) [0|0] "A"  Receiver
 SG_ VCFrontuiState m11 : 24|1@1+ (1,0) [0|0] ""  Receiver
 SG_ VCFrontuiFault m11 : 25|1@1+ (1,0) [0|0] ""  Receiver
 SG_ VCFrontuiCurrent m11 : 32|16@1+ (0.1,0) [0|0] "A"  Receiver
 SG_ VCFrontheadlampLeftState m12 : 8|1@1+ (1,0) [0|0] ""  Receiver
 SG_ VCFrontheadlampLeftFault m12 : 9|1@1+ (1,0) [0|0] ""  Receiver
 SG_ VCFrontheadlampLeftCurrent m12 : 10|10@1+ (0.1,0) [0|0] "A"  Receiver
 SG_ VCFrontheadlampLeftVoltage m12 : 20|8@1+ (0.1,0) [0|0] "V"  Receiver
 SG_ VCFrontheadlampRightState m12 : 28|1@1+ (1,0) [0|0] ""  Receiver
 SG_ VCFrontheadlampRightFault m12 : 29|1@1+ (1,0) [0|0] ""  Receiver
 SG_ VCFrontheadlampRightCurrent m12 : 30|10@1+ (0.1,0) [0|0] "A"  Receiver
 SG_ VCFrontheadlampRightVoltage m12 : 40|8@1+ (0.1,0) [0|0] "V"  Receiver
 SG_ VCFrontheadlampLeftTemperature m12 : 48|8@1- (1,-40) [0|0] "C"  Receiver
 SG_ VCFrontheadlampRightTemperature m12 : 56|8@1- (1,-40) [0|0] "C"  Receiver
 SG_ VCFrontvbatFusedHighState m13 : 8|1@1+ (1,0) [0|0] ""  Receiver
 SG_ VCFrontvbatFusedHighFault m13 : 9|1@1+ (1,0) [0|0] ""  Receiver
 SG_ VCFrontvbatFusedSelfTestResult m13 : 10|4@1+ (1,0) [0|0] ""  Receiver
 SG_ VCFrontvbatFusedHighTemp m13 : 14|11@1+ (0.125,-40) [0|0] "C"  Receiver
 SG_ VCFrontvbatFusedHighVoltage m13 : 30|16@1+ (0.1,0) [0|0] "V"  Receiver
 SG_ VCFrontvbatFusedHighCurrent m13 : 46|16@1+ (0.1,0) [0|0] "A"  Receiver
 SG_ VCFrontpump1AndFanState m14 : 5|1@1+ (1,0) [0|0] ""  Receiver
 SG_ VCFrontpump1AndFanCurrent m14 : 6|16@1+ (0.1,0) [0|6553.5] "A"  Receiver
 SG_ VCFrontpump1AndFanVoltage m14 : 22|12@1+ (0.1,0) [0|0] "V"  Receiver
 SG_ VCFrontpump2AndAirCompState m14 : 34|1@1+ (1,0) [0|0] ""  Receiver
 SG_ VCFrontpump2AndAirCompCurrent m14 : 35|16@1+ (0.1,0) [0|0] "A"  Receiver
 SG_ VCFrontpump2AndAirCompVoltage m14 : 51|12@1+ (0.1,0) [0|0] "V"  Receiver
 SG_ VCFrontrailA_12v m15 : 8|12@1+ (0.00544368,0) [0|22.2918696] "V"  Receiver
 SG_ VCFrontrailB_12v m15 : 20|12@1+ (0.00544368,0) [0|0] "V"  Receiver
 SG_ VCFrontrailA_5v m15 : 32|12@1+ (0.00544368,0) [0|0] "V"  Receiver
 SG_ VCFrontrailB_5v m15 : 44|12@1+ (0.00544368,0) [0|0] "V"  Receiver
 SG_ VCFronteFuseLockoutVoltage m16 : 8|12@1+ (0.00544368,0) [0|22.2918696] "V"  Receiver
 SG_ VCFrontChargePumpVoltage m16 : 24|16@1+ (0.00544368,0) [0|0] "V"  Receiver
 SG_ VCFrontvbatProt m16 : 40|12@1+ (0.00544368,0) [0|0] "V"  Receiver

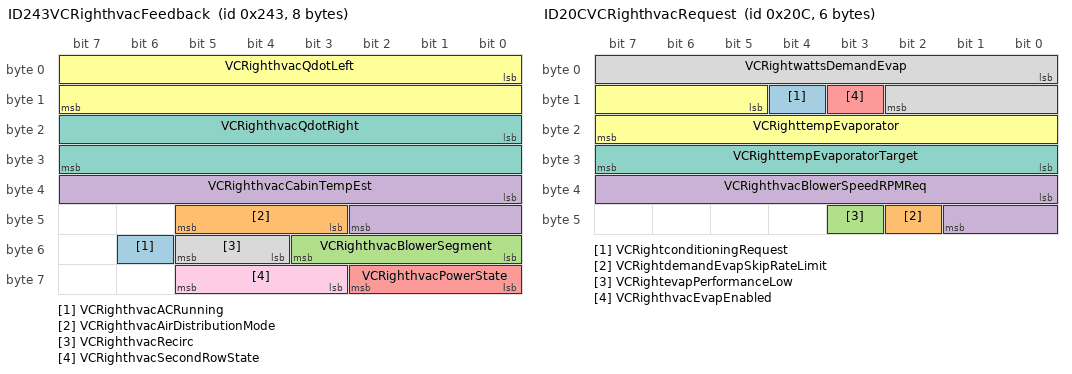
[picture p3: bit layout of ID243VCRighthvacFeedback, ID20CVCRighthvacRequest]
BO_ 579 ID243VCRighthvacFeedback: 8 VehicleBus
 SG_ VCRighthvacACRunning : 54|1@1+ (1,0) [0|1] ""  Receiver
 SG_ VCRighthvacAirDistributionMode : 43|3@1+ (1,0) [0|7] ""  Receiver
 SG_ VCRighthvacBlowerSegment : 48|4@1+ (1,0) [0|15] ""  Receiver
 SG_ VCRighthvacCabinTempEst : 32|11@1+ (0.1,-40) [-40|164.7] "C"  Receiver
 SG_ VCRighthvacPowerState : 56|3@1+ (1,0) [0|7] ""  Receiver
 SG_ VCRighthvacQdotLeft : 0|16@1+ (1,-32767) [-32767|32768] "W"  Receiver
 SG_ VCRighthvacQdotRight : 16|16@1+ (1,-32767) [-32767|32768] "W"  Receiver
 SG_ VCRighthvacRecirc : 52|2@1+ (1,0) [0|3] ""  Receiver
 SG_ VCRighthvacSecondRowState : 59|3@1+ (1,0) [0|7] ""  Receiver

BO_ 524 ID20CVCRighthvacRequest: 6 VehicleBus
 SG_ VCRightconditioningRequest : 12|1@1+ (1,0) [0|1] ""  Receiver
 SG_ VCRightdemandEvapSkipRateLimit : 42|1@1+ (1,0) [0|1] ""  Receiver
 SG_ VCRightevapPerformanceLow : 43|1@1+ (1,0) [0|1] ""  Receiver
 SG_ VCRighthvacBlowerSpeedRPMReq : 32|10@1+ (5,0) [0|5115] "RPM"  Receiver
 SG_ VCRighthvacEvapEnabled : 11|1@1+ (1,0) [0|1] ""  Receiver
 SG_ VCRighttempEvaporator : 13|11@1+ (0.1,-40) [-40|164.7] "C"  Receiver
 SG_ VCRighttempEvaporatorTarget : 24|8@1+ (0.2,0) [0|51] "C"  Receiver
 SG_ VCRightwattsDemandEvap : 0|11@1+ (5,0) [0|10235] "W"  Receiver

BO_ 691 ID2B3VCRightlogging1Hz: 8 VehicleBus
 SG_ VCRightlogging1HzIndex M : 0|4@1+ (1,0) [0|0] ""  Receiver
 SG_ VCRighttempDuctLeft m0 : 4|9@1+ (0.3,-40) [0|0] "C"  Receiver
 SG_ VCRighttempDuctRight m0 : 13|9@1+ (0.3,-40) [0|0] "C"  Receiver
 SG_ VCRighttempIncarCabinProbe m0 : 24|8@1+ (0.5,-40) [0|0] "C"  Receiver
 SG_ VCRighttempIncarCabinMid m0 : 32|8@1+ (0.5,-40) [0|0] "C"  Receiver
 SG_ VCRighttempIncarCabinDeep m0 : 40|8@1+ (0.5,-40) [0|0] "C"  Receiver
 SG_ VCRightcabinTempInteriorL2 m0 : 48|8@1+ (0.5,-40) [0|0] "C"  Receiver
 SG_ VCRightcabinTempInteriorSunnyL2 m0 : 56|8@1+ (0.6,-40) [0|0] "C"  Receiver
 SG_ VCRightcabinTempGlassRoof m1 : 8|8@1+ (0.5,-40) [0|0] "C"  Receiver
 SG_ VCRightcabinTempWindshield m1 : 16|8@1+ (0.5,-40) [0|0] "C"  Receiver
 SG_ VCRightcabinTempInterior m1 : 24|8@1+ (0.5,-40) [0|0] "C"  Receiver
 SG_ VCRightcabinTempInteriorSunny m1 : 32|8@1+ (0.6,-40) [0|0] "C"  Receiver
 SG_ VCRightcabinTempSideGlassLeft m1 : 40|8@1+ (0.5,-40) [0|0] "C"  Receiver
 SG_ VCRightcabinTempSideGlassRight m1 : 48|8@1+ (0.5,-40) [0|0] "C"  Receiver
 SG_ VCRightcabinTempBreathLevel m1 : 56|8@1+ (0.5,-40) [0|0] "C"  Receiver
 SG_ VCRighthvacEstimateWindshieldRH m2 : 4|8@1+ (1,0) [0|0] "%"  Receiver
 SG_ VCRighthvacFoggingRiskLevel m2 : 12|8@1+ (1,0) [0|0] "%"  Receiver
 SG_ VCRighthvacCabinHumidityLevel m2 : 20|8@1+ (1,0) [0|0] "%"  Receiver
 SG_ VCRightwattsHeaterLeftTotal m2 : 28|10@1+ (5,0) [0|5115] "W"  Receiver
 SG_ VCRightwattsHeaterRightTotal m2 : 38|10@1+ (5,0) [0|5115] "W"  Receiver
 SG_ VCRightptcHeaterPwrDemandLeft m2 : 48|8@1+ (20,0) [0|0] "W"  Receiver
 SG_ VCRightptcHeaterPwrDemandRight m2 : 56|8@1+ (20,0) [0|0] "W"  Receiver
 SG_ VCRighthvacSetTempActualLeft m3 : 8|8@1+ (0.1,15) [0|0] "C"  Receiver
 SG_ VCRighthvacSetTempActualRight m3 : 16|8@1+ (0.1,15) [0|0] "C"  Receiver
 SG_ VCRighthvacAutoTransitionReason m3 : 24|5@1+ (1,0) [0|0] ""  Receiver
 SG_ VCRighthvacAirFlowModeRow1 m3 : 29|3@1+ (1,0) [0|0] ""  Receiver
 SG_ VCRighthvacAirFlowModeRow2 m3 : 32|3@1+ (1,0) [0|0] ""  Receiver
 SG_ VCRighthvacMassflowTarget m3 : 40|8@1+ (1,0) [0|0] "g/s"  Receiver
 SG_ VCRighthvacAirflowReason m3 : 48|4@1+ (1,0) [0|0] ""  Receiver
 SG_ VCRighthvacQdotLimitedLeft m3 : 52|1@1+ (1,0) [0|0] ""  Receiver
 SG_ VCRighthvacQdotLimitedRight m3 : 53|1@1+ (1,0) [0|0] ""  Receiver
 SG_ VCRightLHPanelAirflowBlocked m3 : 54|1@1+ (1,0) [0|0] ""  Receiver
 SG_ VCRightRHPanelAirflowBlocked m3 : 55|1@1+ (1,0) [0|0] ""  Receiver
 SG_ VCRightfloorAirflowBlocked m3 : 56|1@1+ (1,0) [0|0] ""  Receiver
 SG_ VCRightdefrostAirflowBlocked m3 : 57|1@1+ (1,0) [0|0] ""  Receiver
 SG_ VCRightconvectionTargetLeft m4 : 8|8@1+ (2,-254) [0|0] "W/m2"  Receiver
 SG_ VCRightconvectionTargetRight m4 : 16|8@1+ (2,-254) [0|0] "W/m2"  Receiver
 SG_ VCRightconvectionDeliveredLeft m4 : 24|8@1+ (2,-254) [0|0] "W/m2"  Receiver
 SG_ VCRightconvectionDeliveredRight m4 : 32|8@1+ (2,-254) [0|0] "W/m2"  Receiver
 SG_ VCRightsolarLoadRightOccupant m4 : 40|7@1+ (2,0) [0|0] "W/m2"  Receiver
 SG_ VCRightsolarLoadLeftOccupant m4 : 48|7@1+ (2,0) [0|0] "W/m2"  Receiver
 SG_ VCRightsolarLoadOnVehicle m4 : 56|8@1+ (4,0) [0|0] "W/m2"  Receiver
 SG_ VCRightptcHeaterTempDuctHigh m5 : 4|1@1+ (1,0) [0|0] ""  Receiver
 SG_ VCRightptcHeaterTempDuctFault m5 : 5|1@1+ (1,0) [0|0] ""  Receiver
 SG_ VCRightptcHeaterNoAirflow m5 : 6|1@1+ (1,0) [0|0] ""  Receiver
 SG_ VCRightptcHeaterHvacActNotReady m5 : 7|1@1+ (1,0) [0|0] ""  Receiver
 SG_ VCRightptcHeaterNoUiRequest m5 : 8|1@1+ (1,0) [0|0] ""  Receiver
 SG_ VCRightptcHeaterNoHighVoltage m5 : 9|1@1+ (1,0) [0|0] ""  Receiver
 SG_ VCRightptcHeaterLAirPathBlocked m5 : 10|1@1+ (1,0) [0|0] ""  Receiver
 SG_ VCRightptcHeaterRAirPathBlocked m5 : 11|1@1+ (1,0) [0|0] ""  Receiver
 SG_ VCRightptcHeaterReqAirpathBlocke m5 : 12|1@1+ (1,0) [0|0] ""  Receiver
 SG_ VCRighthvacDuctTargetLeft m5 : 13|8@1+ (0.5,-40) [0|0] "C"  Receiver
 SG_ VCRighthvacDuctTargetRight m5 : 21|8@1+ (0.5,-40) [0|0] "C"  Receiver
 SG_ VCRighthvacQdotFeedforward m5 : 29|16@1+ (1,-32767) [-32767|32768] "W"  Receiver
 SG_ VCRightevapLoadInFresh m5 : 45|8@1+ (35,0) [0|0] "W"  Receiver
 SG_ VCRightevapLoadInRecirc m5 : 53|8@1+ (35,0) [0|0] "W"  Receiver
 SG_ VCRighthvacLHBleedVoltage m6 : 8|8@1+ (0.02,0) [0|0] "V"  Receiver
 SG_ VCRighthvacRHBleedVoltage m6 : 16|8@1+ (0.02,0) [0|0] "V"  Receiver
 SG_ VCRighthvacLHVaneVoltage m6 : 24|8@1+ (0.02,0) [0|0] "V"  Receiver
 SG_ VCRighthvacRHVaneVoltage m6 : 32|8@1+ (0.02,0) [0|0] "V"  Receiver
 SG_ VCRighthvacUpperModeVoltage m6 : 40|8@1+ (0.02,0) [0|0] "V"  Receiver
 SG_ VCRighthvacLowerModeVoltage m6 : 48|8@1+ (0.02,0) [0|0] "V"  Receiver
 SG_ VCRighthvacIntakeVoltage m6 : 56|8@1+ (0.02,0) [0|0] "V"  Receiver
 SG_ VCRighthvacLHBleedEndStop m7 : 8|8@1+ (0.02,0) [0|0] "V"  Receiver
 SG_ VCRighthvacRHBleedEndStop m7 : 16|8@1+ (0.02,0) [0|0] "V"  Receiver
 SG_ VCRighthvacLHVaneEndStop m7 : 24|8@1+ (0.02,0) [0|0] "V"  Receiver
 SG_ VCRighthvacRHVaneEndStop m7 : 32|8@1+ (0.02,0) [0|0] "V"  Receiver
 SG_ VCRighthvacUpperModeEndStop m7 : 40|8@1+ (0.02,0) [0|0] "V"  Receiver
 SG_ VCRighthvacLowerModeEndStop m7 : 48|8@1+ (0.02,0) [0|0] "V"  Receiver
 SG_ VCRighthvacIntakeEndStop m7 : 56|8@1+ (0.02,0) [0|0] "V"  Receiver
 SG_ VCRighthvacLHBleedZeroStop m8 : 8|8@1+ (0.02,0) [0|0] "V"  Receiver
 SG_ VCRighthvacRHBleedZeroStop m8 : 16|8@1+ (0.02,0) [0|0] "V"  Receiver
 SG_ VCRighthvacLHVaneZeroStop m8 : 24|8@1+ (0.02,0) [0|0] "V"  Receiver
 SG_ VCRighthvacRHVaneZeroStop m8 : 32|8@1+ (0.02,0) [0|0] "V"  Receiver
 SG_ VCRighthvacUpperModeZeroStop m8 : 40|8@1+ (0.02,0) [0|0] "V"  Receiver
 SG_ VCRighthvacLowerModeZeroStop m8 : 48|8@1+ (0.02,0) [0|0] "V"  Receiver
 SG_ VCRighthvacIntakeZeroStop m8 : 56|8@1+ (0.02,0) [0|0] "V"  Receiver
 SG_ VCRighttimeLeftToCabinModelInit m9 : 8|8@1+ (1,0) [0|0] ""  Receiver
 SG_ VCRighthvacFlashFoggingDetected m9 : 16|1@1+ (1,0) [0|0] ""  Receiver
 SG_ VCRightsolarLoadOnVehFiltered m9 : 17|8@1+ (4,0) [0|0] "W/m2"  Receiver
 SG_ VCRighthvacCabinPurgeActive m9 : 25|1@1+ (1,0) [0|0] ""  Receiver
 SG_ VCRighthvacCabOvrheatProtActive m9 : 26|1@1+ (1,0) [0|0] ""  Receiver
 SG_ VCRighthvacCabinPurgeAllowed m9 : 27|1@1+ (1,0) [0|0] ""  Receiver
 SG_ VCRighthvacCabOvrheatProtAllowed m9 : 28|1@1+ (1,0) [0|0] ""  Receiver
 SG_ VCRightcloudinessProbability m9 : 29|7@1+ (1,0) [0|127] "%"  Receiver
 SG_ VCRightcabinTempInteriorL3 m9 : 36|8@1+ (0.5,-40) [0|0] "C"  Receiver
 SG_ VCRightcabinTempInteriorSunnyL3 m9 : 44|8@1+ (0.6,-40) [0|0] "C"  Receiver
 SG_ VCRightcabinTempTopPadAir m9 : 52|8@1+ (0.6,-40) [0|0] "C"  Receiver
 SG_ VCRighttempDuctModeledLeft m10 : 4|9@1+ (0.3,-40) [0|0] "C"  Receiver
 SG_ VCRighttempDuctModeledRight m10 : 13|9@1+ (0.3,-40) [0|0] "C"  Receiver
 SG_ VCRighttempHtrSurfaceModeledL m10 : 22|9@1+ (0.3,-40) [0|0] "C"  Receiver
 SG_ VCRighttempHtrSurfaceModeledR m10 : 31|9@1+ (0.3,-40) [0|0] "C"  Receiver

BO_ 705 ID2C1VCFront10hz: 8 VehicleBus
 SG_ VCFront10HzIndex M : 0|3@1+ (1,0) [0|7] ""  Receiver
 SG_ VCfrontpumpBatteryRPMActual m0 : 3|10@1+ (10,0) [0|10230] "rpm"  Receiver
 SG_ VCfrontpumpBatteryRPMTarget m0 : 13|10@1+ (10,0) [0|0] "rpm"  Receiver
 SG_ VCfrontpumpPowertrainRPMActual m0 : 23|10@1+ (10,0) [0|0] "rpm"  Receiver
 SG_ VCfrontpumpPowertrainRPMTarget m0 : 33|10@1+ (10,0) [0|0] "rpm"  Receiver
 SG_ VCfrontpumpBatteryOutVoltage m0 : 43|7@1+ (0.2,0) [0|0] "V"  Receiver
 SG_ VCfrontpumpPowertrainOutVoltage m0 : 50|7@1+ (0.2,0) [0|0] "V"  Receiver
 SG_ VCfrontpumpBatteryInitd m0 : 57|1@1+ (1,0) [0|0] ""  Receiver
 SG_ VCfrontpumpPowertrainInitd m0 : 58|1@1+ (1,0) [0|0] ""  Receiver
 SG_ VCfrontpumpBatteryEnabled m0 : 59|1@1+ (1,0) [0|0] ""  Receiver
 SG_ VCfrontpumpPowertrainEnabled m0 : 60|1@1+ (1,0) [0|0] ""  Receiver
 SG_ VCfrontpumpBatteryPowerOn m0 : 61|1@1+ (1,0) [0|0] ""  Receiver
 SG_ VCfrontpumpPowertrainPowerOn m0 : 62|1@1+ (1,0) [0|0] ""  Receiver
 SG_ VCfrontpumpsWake m0 : 63|1@1+ (1,0) [0|0] ""  Receiver
 SG_ VCfrontradiatorFanOutVoltage m1 : 8|7@1+ (0.2,0) [0|0] "V"  Receiver
 SG_ VCfrontradiatorFanRPMTarget m1 : 16|10@1+ (10,0) [0|0] "rpm"  Receiver
 SG_ VCfrontradiatorFanRPMActual m1 : 26|10@1+ (10,0) [0|0] "rpm"  Receiver
 SG_ VCfrontradiatorFanInitd m1 : 36|1@1+ (1,0) [0|0] ""  Receiver
 SG_ VCfrontradiatorFanEnabled m1 : 37|1@1+ (1,0) [0|0] ""  Receiver
 SG_ VCfrontradiatorFanPowerOn m1 : 38|1@1+ (1,0) [0|0] ""  Receiver
 SG_ VCfrontradiatorFanPhaseCurrent m1 : 40|8@1+ (0.5,-25) [0|0] "A"  Receiver
 SG_ VCfrontfiveWayValveMode m2 : 3|1@1+ (1,0) [0|0] ""  Receiver
 SG_ VCfrontcoolantTempBasedMode m2 : 4|1@1+ (1,0) [0|0] ""  Receiver
 SG_ VCfrontfiveWayValveModeWrong m2 : 5|1@1+ (1,0) [0|0] ""  Receiver
 SG_ VCfrontfiveWayValveAngleActual m2 : 6|10@1+ (0.25,-70) [0|0] "deg"  Receiver
 SG_ VCfrontfiveWayValveAngleTarget m2 : 16|10@1+ (0.25,-10) [0|0] "deg"  Receiver
 SG_ VCfrontfiveWayValveRadBypass m2 : 26|7@1+ (1,0) [0|0] "%"  Receiver
 SG_ VCfrontfiveWayValveState m2 : 33|2@1+ (1,0) [0|0] ""  Receiver
 SG_ VCfrontfiveWayValveDuty m2 : 35|8@1- (1,0) [0|0] "%"  Receiver
 SG_ VCfrontfiveWayValveAngleTravel m2 : 43|10@1+ (5,0) [0|0] "deg"  Receiver
 SG_ VCfrontfiveWayValveISense m2 : 53|6@1+ (0.01,0) [0|0] "A"  Receiver
 SG_ VCfronttempRefrigSuction m3 : 8|8@1+ (0.5,-40) [0|0] "C"  Receiver
 SG_ VCfronttempRefrigDischarge m3 : 16|11@1+ (0.125,-40) [0|0] "C"  Receiver
 SG_ VCfronttempSuperheatActual m3 : 27|10@1+ (0.1,-20) [0|0] "C"  Receiver
 SG_ VCfronttempSuperheatTarget m3 : 37|10@1+ (0.1,0) [0|0] "C"  Receiver
 SG_ VCfrontpumpBatSpiError m3 : 47|1@1+ (1,0) [0|0] ""  Receiver
 SG_ VCfrontpumpPtSpiError m3 : 48|1@1+ (1,0) [0|0] ""  Receiver
 SG_ VCfrontthmlFanSpiError m3 : 49|1@1+ (1,0) [0|0] ""  Receiver
 SG_ VCfronttempDischargeSimulated m3 : 50|11@1+ (0.125,-40) [0|0] "C"  Receiver
 SG_ VCfrontisOnlySuctTempNotReady m3 : 61|1@1+ (1,0) [0|0] ""  Receiver
 SG_ VCfrontusingSimulatedDischTemp m3 : 62|1@1+ (1,0) [0|0] ""  Receiver
 SG_ VCfrontusingSimulatedAmbTemp m3 : 63|1@1+ (1,0) [0|0] ""  Receiver
 SG_ VCfrontrefrigerantHasBeenFilled m4 : 3|1@1+ (1,0) [0|0] ""  Receiver
 SG_ VCfrontcompDemandChiller m4 : 8|7@1+ (1,0) [0|0] "%"  Receiver
 SG_ VCfrontcompDemandEvap m4 : 16|7@1+ (1,0) [0|0] "%"  Receiver
 SG_ VCfrontcompressorState m4 : 24|2@1+ (1,0) [0|0] ""  Receiver
 SG_ VCfrontcompLimitPresDischargeHi m4 : 26|1@1+ (1,0) [0|0] ""  Receiver
 SG_ VCfrontcompLimitTempDischargeHi m4 : 27|1@1+ (1,0) [0|0] ""  Receiver
 SG_ VCfrontcompLimitScrollSepRegion m4 : 28|1@1+ (1,0) [0|0] ""  Receiver
 SG_ VCfrontcompLimitNvh m4 : 29|1@1+ (1,0) [0|0] ""  Receiver
 SG_ VCfrontcompLimitScrollSepRamp m4 : 30|1@1+ (1,0) [0|0] ""  Receiver
 SG_ VCfrontcompLimitDeadband m4 : 31|1@1+ (1,0) [0|0] ""  Receiver
 SG_ VCfrontcompStandbySelfNotReady m4 : 32|1@1+ (1,0) [0|0] ""  Receiver
 SG_ VCfrontcompStandbyCommunication m4 : 33|1@1+ (1,0) [0|0] ""  Receiver
 SG_ VCfrontcompStandbyHVNotReady m4 : 34|1@1+ (1,0) [0|0] ""  Receiver
 SG_ VCfrontcompStandbyLowAmbient m4 : 35|1@1+ (1,0) [0|0] ""  Receiver
 SG_ VCfrontcompStandbyLowDischPress m4 : 36|1@1+ (1,0) [0|0] ""  Receiver
 SG_ VCfrontcompStandbyRefrigNotOk m4 : 37|1@1+ (1,0) [0|0] ""  Receiver
 SG_ VCfrontcompLimitTempDischargeSim m4 : 38|1@1+ (1,0) [0|0] ""  Receiver
 SG_ VCfrontcompRampRateUpMax m4 : 40|6@1+ (0.1,0) [0|0] "%/s"  Receiver
 SG_ VCfrontrefrigerantValvesClosed m4 : 46|1@1+ (1,0) [0|0] ""  Receiver

BO_ 737 ID2E1VCFrontStatus: 8 VehicleBus
 SG_ VCFrontStatusIndex M : 0|3@1+ (1,0) [0|7] ""  Receiver
 SG_ VCfrontfrunkLatchStatus m0 : 3|4@1+ (1,0) [0|0] ""  Receiver
 SG_ VCfrontwiperSpeed m0 : 8|4@1+ (1,0) [0|0] ""  Receiver
 SG_ VCfrontwiperPosition m0 : 12|3@1+ (1,0) [0|0] ""  Receiver
 SG_ VCfrontwiperState m0 : 16|4@1+ (1,0) [0|0] ""  Receiver
 SG_ VCfrontcrashDetectedType m0 : 20|2@1+ (1,0) [0|0] ""  Receiver
 SG_ VCfrontcrashState m0 : 22|2@1+ (1,0) [0|0] ""  Receiver
 SG_ VCfrontcrashUnlockOverrideSet m0 : 24|1@1+ (1,0) [0|0] ""  Receiver
 SG_ VCfrontairCompressorStatus m0 : 25|3@1+ (1,0) [0|0] ""  Receiver
 SG_ VCfrontheadlightLeftVPosition m0 : 28|10@1+ (1,0) [0|0] "ticks"  Receiver
 SG_ VCfrontheadlightRightVPosition m0 : 38|10@1+ (1,0) [0|0] "ticks"  Receiver
 SG_ VCfrontfrunkInteriorRelSwitch m0 : 48|1@1+ (1,0) [0|0] ""  Receiver
 SG_ VCfrontanyClosureOpen m0 : 49|1@1+ (1,0) [0|0] ""  Receiver
 SG_ VCfrontanyDoorOpen m0 : 50|1@1+ (1,0) [0|0] ""  Receiver
 SG_ VCfronthornOn m0 : 51|1@1+ (1,0) [0|0] ""  Receiver
 SG_ VCfrontwiperPositionDeg m0 : 52|8@1+ (1,0) [0|0] "deg"  Receiver
 SG_ VCfrontheadlampLeftFanStatus m0 : 60|1@1+ (1,0) [0|0] ""  Receiver
 SG_ VCfrontheadlampRightFanStatus m0 : 61|1@1+ (1,0) [0|0] ""  Receiver
 SG_ VCfront5VARailStable m1 : 3|1@1+ (1,0) [0|0] ""  Receiver
 SG_ VCfront5VBRailStable m1 : 4|1@1+ (1,0) [0|0] ""  Receiver
 SG_ VCfront12VARailStable m1 : 5|1@1+ (1,0) [0|0] ""  Receiver
 SG_ VCfront12VBRailStable m1 : 6|1@1+ (1,0) [0|0] ""  Receiver
 SG_ VCfrontrailAState m1 : 7|1@1+ (1,0) [0|0] ""  Receiver
 SG_ VCfrontrailBState m1 : 8|1@1+ (1,0) [0|0] ""  Receiver
 SG_ VCfrontChargePumpVoltageStable m1 : 9|1@1+ (1,0) [0|0] ""  Receiver
 SG_ VCfrontiBoosterWakeLine m1 : 10|1@1+ (1,0) [0|0] ""  Receiver
 SG_ VCfrontepasWakeLine m1 : 11|1@1+ (1,0) [0|0] ""  Receiver
 SG_ VCfrontiBoosterStateDBG m1 : 12|3@1+ (1,0) [0|0] ""  Receiver
 SG_ VCfrontvehicleStatusDBG m1 : 16|5@1+ (1,0) [0|0] ""  Receiver
 SG_ VCfrontreverseBatteryFault m1 : 21|1@1+ (1,0) [0|0] ""  Receiver
 SG_ VCfrontbatterySMState m1 : 22|3@1+ (1,0) [0|0] ""  Receiver
 SG_ VCfronttimeSpentCharging m1 : 25|10@1+ (1,0) [0|0] "min"  Receiver
 SG_ VCfronttimeSpentDischarging m1 : 35|10@1+ (1,0) [0|0] "min"  Receiver
 SG_ VCfronttimeSpentSleeping m1 : 45|8@1+ (1,0) [0|0] "s"  Receiver
 SG_ VCfrontsleepCurrent m1 : 53|10@1- (1,0) [0|0] "mA"  Receiver
 SG_ VCfronthomelinkV2Response0 m2 : 8|8@1+ (1,0) [0|0] ""  Receiver
 SG_ VCfronthomelinkV2Response1 m2 : 16|8@1+ (1,0) [0|0] ""  Receiver
 SG_ VCfronthomelinkV2Response2 m2 : 24|8@1+ (1,0) [0|0] ""  Receiver
 SG_ VCfronthomelinkV2Response3 m2 : 32|8@1+ (1,0) [0|0] ""  Receiver
 SG_ VCfronthomelinkV2Response4 m2 : 40|8@1+ (1,0) [0|0] ""  Receiver
 SG_ VCfronthomelinkCommStatus m2 : 48|2@1+ (1,0) [0|0] ""  Receiver
 SG_ VCfrontmaxEvapHeatRejection m3 : 8|8@1+ (32,0) [0|0] "W"  Receiver
 SG_ VCfrontminEvapHeatRejection m3 : 16|8@1+ (10,0) [0|0] "W"  Receiver
 SG_ VCfrontfreezeEvapITerm m3 : 24|1@1+ (1,0) [0|0] ""  Receiver
 SG_ VCfrontisEvapOperationAllowed m3 : 25|1@1+ (1,0) [0|0] ""  Receiver
 SG_ VCfrontchillerDemandActive m3 : 26|1@1+ (1,0) [0|0] ""  Receiver
 SG_ VCfrontcompPerfRecoveryLimited m3 : 27|1@1+ (1,0) [0|0] ""  Receiver
 SG_ VCfronthasLowRefrigerant m3 : 29|1@1+ (1,0) [0|0] ""  Receiver
 SG_ VCfrontpressureRefrigSuction m3 : 32|7@1+ (0.125,0) [0|0] "bar"  Receiver
 SG_ VCfrontpressureRefrigDischarge m3 : 40|8@1+ (0.125,0) [0|0] "bar"  Receiver
 SG_ VCfrontwiperCycles m3 : 48|16@1+ (100,0) [0|0] "Cycles"  Receiver
 SG_ VCfronttempCompTargetVoltage m4 : 3|10@1+ (0.01,9) [0|0] "V"  Receiver
 SG_ VCfrontAS8510Voltage m4 : 13|12@1+ (0.00544368,0) [0|0] "V"  Receiver
 SG_ VCfrontcalibratedAS8510Volts m4 : 25|12@1+ (0.00544368,0) [0|0] "V"  Receiver
 SG_ VCfrontchargeNeeded m4 : 37|1@1+ (1,0) [0|0] ""  Receiver
 SG_ VCfrontPCSMia m4 : 38|1@1+ (1,0) [0|0] ""  Receiver
 SG_ VCfrontDCDCNoop m4 : 39|1@1+ (1,0) [0|0] ""  Receiver
 SG_ VCfrontIBSFault m4 : 40|1@1+ (1,0) [0|0] ""  Receiver
 SG_ VCfrontPEResetLineState m4 : 41|1@1+ (1,0) [0|0] ""  Receiver
 SG_ VCfrontHSDInitCompleteU13 m4 : 42|1@1+ (1,0) [0|0] ""  Receiver
 SG_ VCfrontHSDInitCompleteU16 m4 : 43|1@1+ (1,0) [0|0] ""  Receiver
 SG_ VCfrontIBSUnfilteredTemperature m4 : 44|16@1- (0.01,0) [0|0] "C"  Receiver
 SG_ VCfront12VOverchargeCounter m4 : 60|4@1+ (1,0) [0|0] ""  Receiver

BO_ 897 ID381VCFront1Hz: 8 VehicleBus
 SG_ VCFront1HzIndex M : 0|3@1+ (1,0) [0|7] ""  Receiver
 SG_ VCFrontmodeTransitionID m0 : 3|5@1+ (1,0) [0|0] ""  Receiver
 SG_ VCFrontmodeDesired m0 : 8|1@1+ (1,0) [0|0] ""  Receiver
 SG_ VCFronttargetPTActiveCool m0 : 16|8@1+ (1,-40) [0|0] "C"  Receiver
 SG_ VCFronttargetPTPassive m0 : 24|8@1+ (1,-40) [0|0] "C"  Receiver
 SG_ VCFronttargetBatActiveCool m0 : 32|7@1+ (1,0) [0|0] "C"  Receiver
 SG_ VCFronttargetBatPassive m0 : 40|7@1+ (1,-20) [0|0] "C"  Receiver
 SG_ VCFronttargetBatActiveHeat m0 : 48|7@1+ (1,-40) [0|0] "C"  Receiver
 SG_ VCFrontcondenserPressureLimit m1 : 8|7@1+ (0.1,10) [0|0] "bar"  Receiver
 SG_ VCFrontactiveLouverAbnormalKT m1 : 15|1@1+ (1,0) [0|0] ""  Receiver
 SG_ VCFrontactiveLouverOverCurrent m1 : 16|1@1+ (1,0) [0|0] ""  Receiver
 SG_ VCFrontactiveLouverOverTemp m1 : 17|1@1+ (1,0) [0|0] ""  Receiver
 SG_ VCFrontactiveLouverMotorState m1 : 18|4@1+ (1,0) [0|0] ""  Receiver
 SG_ VCFrontactiveLouverState m2 : 3|3@1+ (1,0) [0|0] ""  Receiver
 SG_ VCFrontactiveLouverIsCalibrated m2 : 6|1@1+ (1,0) [0|0] ""  Receiver
 SG_ VCFrontactiveLouverMotorCounts m2 : 8|11@1+ (1,-100) [0|0] "ticks"  Receiver
 SG_ VCFrontactiveLouverOpenPosTarg m2 : 24|7@1+ (1,0) [0|0] "%"  Receiver
 SG_ VCFrontactiveLouverOpenPos m2 : 32|7@1+ (1,0) [0|0] "%"  Receiver
 SG_ VCFrontpumpBatteryFETTemp m2 : 40|8@1+ (1,-40) [0|0] "C"  Receiver
 SG_ VCFrontpumpPowertrainFETTemp m2 : 48|8@1+ (1,-40) [0|0] "C"  Receiver
 SG_ VCFrontradiatorFanFETTemp m2 : 56|8@1+ (1,-40) [0|0] "C"  Receiver
 SG_ VCFrontfiveWayValveRecalReason m3 : 3|3@1+ (1,0) [0|0] ""  Receiver
 SG_ VCFrontfiveWayValveCountRange m3 : 8|8@1+ (1,375) [0|0] "ticks"  Receiver
 SG_ VCFrontfiveWayValveAngleDrift m3 : 16|10@1+ (0.25,-127) [0|0] "degrees"  Receiver
 SG_ VCFrontfiveWayValveRecalCount m3 : 32|16@1+ (1,0) [0|0] ""  Receiver
 SG_ VCFrontfiveWayValveWindupEstL m3 : 48|4@1+ (1,0) [0|0] ""  Receiver
 SG_ VCFrontfiveWayValveWindupEstR m3 : 52|4@1+ (1,0) [0|0] ""  Receiver

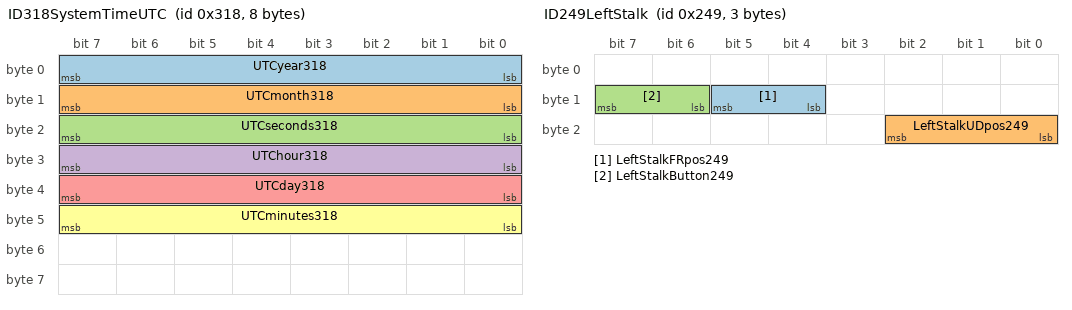
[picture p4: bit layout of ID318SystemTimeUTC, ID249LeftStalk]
BO_ 792 ID318SystemTimeUTC: 8 VehicleBus
 SG_ UTCyear318 : 0|8@1+ (1,0) [0|0] "yr"  Receiver
 SG_ UTCmonth318 : 8|8@1+ (1,0) [0|0] "mo"  Receiver
 SG_ UTCseconds318 : 16|8@1+ (1,0) [0|0] "sec"  Receiver
 SG_ UTChour318 : 24|8@1+ (1,0) [0|0] "hr"  Receiver
 SG_ UTCday318 : 32|8@1+ (1,0) [0|0] "dy"  Receiver
 SG_ UTCminutes318 : 40|8@1+ (1,0) [0|0] "min"  Receiver

BO_ 1320 ID528UnixTime: 4 VehicleBus
 SG_ UnixTimeSeconds528 : 7|32@0+ (1,0) [0|4294967295] "sec"  Receiver

BO_ 553 ID229GearLever: 3 VehicleBus
 SG_ GearLeverPosition229 : 12|3@1+ (1,0) [0|7] ""  Receiver
 SG_ GearLeverButton229 : 16|2@1+ (1,0) [0|3] ""  Receiver

BO_ 585 ID249LeftStalk: 3 VehicleBus
 SG_ LeftStalkFRpos249 : 12|2@1+ (1,0) [0|0] ""  Receiver
 SG_ LeftStalkUDpos249 : 16|3@1+ (1,0) [0|0] ""  Receiver
 SG_ LeftStalkButton249 : 14|2@1+ (1,0) [0|0] ""  Receiver

BO_ 1577 ID628UDSPCStoMCU: 8 VehicleBus

BO_ 1576 ID628UDSMCUtoPCS: 8 VehicleBus

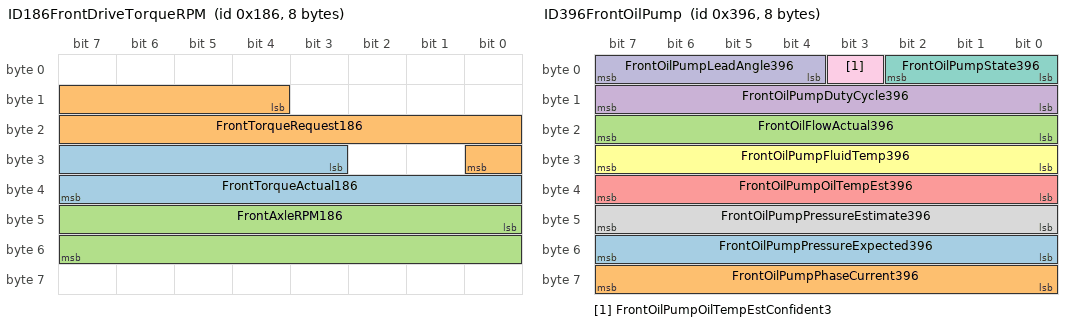
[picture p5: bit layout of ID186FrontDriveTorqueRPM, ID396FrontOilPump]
BO_ 390 ID186FrontDriveTorqueRPM: 8 VehicleBus
 SG_ FrontTorqueActual186 : 27|13@1- (2,0) [-8192|8190] "NM"  Receiver
 SG_ FrontTorqueRequest186 : 12|13@1- (2,0) [-8192|8190] "NM"  Receiver
 SG_ FrontAxleRPM186 : 40|16@1- (0.1,0) [-3276.8|3276.7] "RPM"  Receiver

BO_ 918 ID396FrontOilPump: 8 VehicleBus
 SG_ FrontOilPumpPressureExpected396 : 48|8@1+ (2,0) [0|500] "kPa"  Receiver
 SG_ FrontOilPumpPhaseCurrent396 : 56|8@1+ (0.1,0) [0|25.4] "A"  Receiver
 SG_ FrontOilFlowActual396 : 16|8@1+ (0.06,0) [0|15] "LPM"  Receiver
 SG_ FrontOilPumpDutyCycle396 : 8|8@1+ (0.4,0) [0|100] "%"  Receiver
 SG_ FrontOilPumpOilTempEst396 : 32|8@1+ (1,-40) [0|214] "C"  Receiver
 SG_ FrontOilPumpFluidTemp396 : 24|8@1+ (1,-40) [0|214] "C"  Receiver
 SG_ FrontOilPumpState396 : 0|3@1+ (1,0) [0|7] ""  Receiver
 SG_ FrontOilPumpPressureEstimate396 : 40|8@1+ (2,0) [0|500] "kPa"  Receiver
 SG_ FrontOilPumpOilTempEstConfident3 : 3|1@1+ (1,0) [0|0] ""  Receiver
 SG_ FrontOilPumpLeadAngle396 : 4|4@1+ (1.875,0) [0|28.125] "deg"  Receiver

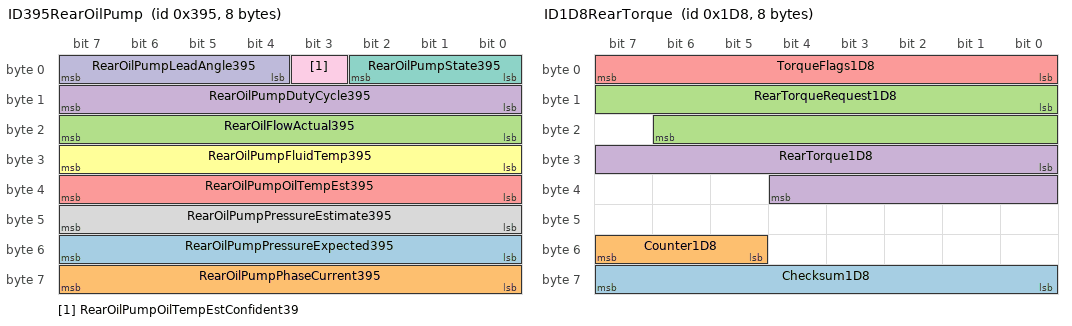
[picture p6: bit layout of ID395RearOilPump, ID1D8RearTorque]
BO_ 917 ID395RearOilPump: 8 VehicleBus
 SG_ RearOilPumpPressureExpected395 : 48|8@1+ (2,0) [0|500] "kPa"  Receiver
 SG_ RearOilPumpPhaseCurrent395 : 56|8@1+ (0.1,0) [0|25.4] "A"  Receiver
 SG_ RearOilFlowActual395 : 16|8@1+ (0.06,0) [0|15] "LPM"  Receiver
 SG_ RearOilPumpDutyCycle395 : 8|8@1+ (0.4,0) [0|100] "%"  Receiver
 SG_ RearOilPumpOilTempEst395 : 32|8@1+ (1,-40) [0|214] "C"  Receiver
 SG_ RearOilPumpFluidTemp395 : 24|8@1+ (1,-40) [0|214] "C"  Receiver
 SG_ RearOilPumpState395 : 0|3@1+ (1,0) [0|7] ""  Receiver
 SG_ RearOilPumpPressureEstimate395 : 40|8@1+ (2,0) [0|500] "kPa"  Receiver
 SG_ RearOilPumpOilTempEstConfident39 : 3|1@1+ (1,0) [0|0] ""  Receiver
 SG_ RearOilPumpLeadAngle395 : 4|4@1+ (1.875,0) [0|28.125] "deg"  Receiver

BO_ 472 ID1D8RearTorque: 8 VehicleBus
 SG_ Checksum1D8 : 56|8@1+ (1,0) [0|0] ""  Receiver
 SG_ Counter1D8 : 53|3@1+ (1,0) [0|0] ""  Receiver
 SG_ RearTorqueRequest1D8 : 8|15@1- (0.1,0) [-1638.4|1638.3] "NM"  Receiver
 SG_ RearTorque1D8 : 24|13@1- (0.25,0) [-1024|1023.75] "NM"  Receiver
 SG_ TorqueFlags1D8 : 0|8@1+ (1,0) [0|0] ""  Receiver

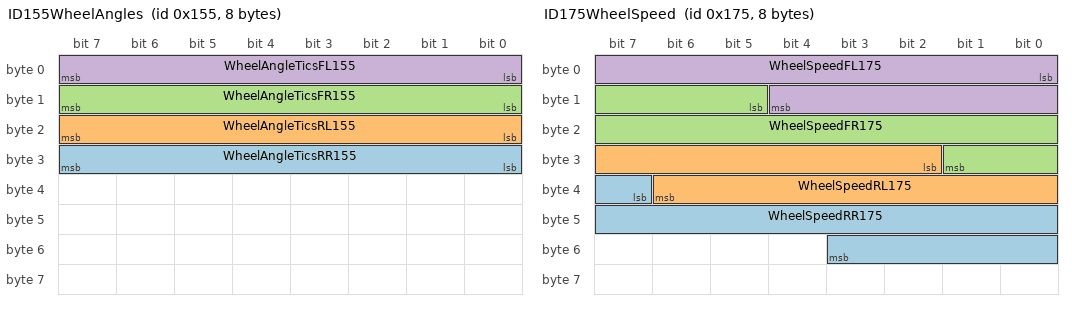
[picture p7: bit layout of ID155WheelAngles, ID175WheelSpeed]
BO_ 341 ID155WheelAngles: 8 ChassisBus
 SG_ WheelAngleTicsRR155 : 24|8@1+ (1.40625,0) [0|358.59375] "deg"  Receiver
 SG_ WheelAngleTicsRL155 : 16|8@1+ (1.40625,0) [0|358.59375] "deg"  Receiver
 SG_ WheelAngleTicsFR155 : 8|8@1+ (1.40625,0) [0|358.59375] "deg"  Receiver
 SG_ WheelAngleTicsFL155 : 0|8@1+ (1.40625,0) [0|358.59375] "deg"  Receiver

BO_ 373 ID175WheelSpeed: 8 ChassisBus
 SG_ WheelSpeedRR175 : 39|13@1+ (0.04,0) [0|327.64] "rpm"  Receiver
 SG_ WheelSpeedRL175 : 26|13@1+ (0.04,0) [0|327.64] "rpm"  Receiver
 SG_ WheelSpeedFR175 : 13|13@1+ (0.04,0) [0|327.64] "rpm"  Receiver
 SG_ WheelSpeedFL175 : 0|13@1+ (0.04,0) [0|327.64] "rpm"  Receiver

BO_ 468 ID1D4FrontTorqueOld: 8 VehicleBus
 SG_ RAWTorqueFront1D4 : 40|12@1- (0.25,0) [-512|511.75] "NM"  Receiver

BO_ 469 ID1D5FrontTorque: 8 VehicleBus
 SG_ FrontTorqueRequest1D5 : 8|15@1- (0.1,0) [-1638.4|1638.3] "NM"  Receiver
 SG_ FrontTorque1D5 : 24|13@1- (0.25,0) [-1024|1023.75] "NM"  Receiver

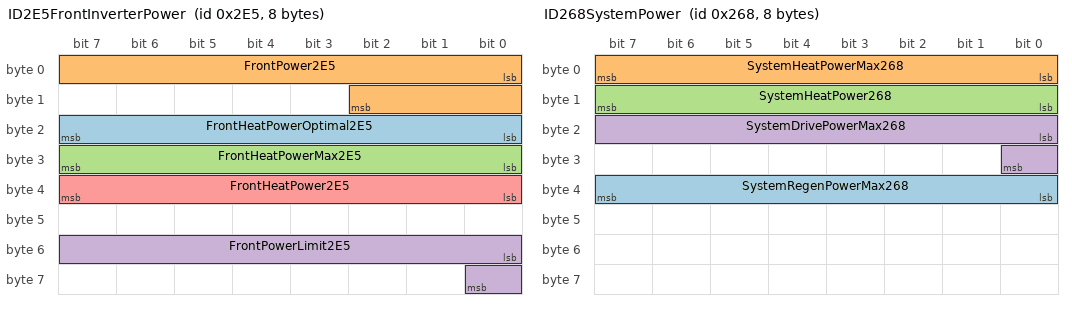
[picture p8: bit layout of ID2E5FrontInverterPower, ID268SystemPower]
BO_ 741 ID2E5FrontInverterPower: 8 VehicleBus
 SG_ FrontHeatPowerOptimal2E5 : 16|8@1+ (0.08,0) [0|20.4] "kW"  Receiver
 SG_ FrontPower2E5 : 0|11@1- (0.5,0) [-512|511.5] "kW"  Receiver
 SG_ FrontHeatPowerMax2E5 : 24|8@1+ (0.08,0) [0|20.4] "kW"  Receiver
 SG_ FrontPowerLimit2E5 : 48|9@1+ (0.25,165) [165|292.75] "kW"  Receiver
 SG_ FrontHeatPower2E5 : 32|8@1+ (0.08,0) [0|20.4] "kW"  Receiver

BO_ 962 ID3C2VCLeftswitches: 8 VehicleBus
 SG_ VCLswitchStatusIndex3C2 M : 0|2@1+ (1,0) [0|0] ""  Receiver
 SG_ VCLhornSwitchPressed3C2 m0 : 2|1@1+ (1,0) [0|0] ""  Receiver
 SG_ VCLhazardButtonPressed3C2 m0 : 3|1@1+ (1,0) [0|0] ""  Receiver
 SG_ VCLdriverPresent3C2 m0 : 4|1@1+ (1,0) [0|0] ""  Receiver
 SG_ VCLrightMirrorTilt3C2 m0 : 5|3@1+ (1,0) [0|0] ""  Receiver
 SG_ VCLfrontSeatTrackBack3C2 m0 : 8|2@1+ (1,0) [0|0] ""  Receiver
 SG_ VCLfrontSeatTrackForward3C2 m0 : 10|2@1+ (1,0) [0|0] ""  Receiver
 SG_ VCLfrontSeatTiltDown3C2 m0 : 12|2@1+ (1,0) [0|0] ""  Receiver
 SG_ VCLfrontSeatTiltUp3C2 m0 : 14|2@1+ (1,0) [0|0] ""  Receiver
 SG_ VCLfrontSeatLiftDown3C2 m0 : 16|2@1+ (1,0) [0|0] ""  Receiver
 SG_ VCLfrontSeatLiftUp3C2 m0 : 18|2@1+ (1,0) [0|0] ""  Receiver
 SG_ VCLfrontSeatBackrestBack3C2 m0 : 20|2@1+ (1,0) [0|0] ""  Receiver
 SG_ VCLfrontSeatBackrestForward3C2 m0 : 22|2@1+ (1,0) [0|0] ""  Receiver
 SG_ VCLfrontSeatLumbarDown3C2 m0 : 24|2@1+ (1,0) [0|0] ""  Receiver
 SG_ VCLfrontSeatLumbarUp3C2 m0 : 26|2@1+ (1,0) [0|0] ""  Receiver
 SG_ VCLfrontSeatLumbarIn3C2 m0 : 28|2@1+ (1,0) [0|0] ""  Receiver
 SG_ VCLfrontSeatLumbarOut3C2 m0 : 30|2@1+ (1,0) [0|0] ""  Receiver
 SG_ VCLbtnWindowSwPackUpLF3C2 m0 : 32|1@1+ (1,0) [0|0] ""  Receiver
 SG_ VCLbtnWindowSwPackAutoUpLF3C2 m0 : 33|1@1+ (1,0) [0|0] ""  Receiver
 SG_ VCLbtnWindowSwPackDownLF3C2 m0 : 34|1@1+ (1,0) [0|0] ""  Receiver
 SG_ VCLbtnWindowSwPackAutoDownLF3C2 m0 : 35|1@1+ (1,0) [0|0] ""  Receiver
 SG_ VCLbtnWindowSwPackUpLR3C2 m0 : 36|1@1+ (1,0) [0|0] ""  Receiver
 SG_ VCLbtnWindowSwPackAutoUpLR3C2 m0 : 37|1@1+ (1,0) [0|0] ""  Receiver
 SG_ VCLbtnWindowSwPackDownLR3C2 m0 : 38|1@1+ (1,0) [0|0] ""  Receiver
 SG_ VCLbtnWindowSwPackAutoDownLR3C2 m0 : 39|1@1+ (1,0) [0|0] ""  Receiver
 SG_ VCLbtnWindowSwPackUpRF3C2 m0 : 40|1@1+ (1,0) [0|0] ""  Receiver
 SG_ VCLbtnWindowSwPackAutoUpRF3C2 m0 : 41|1@1+ (1,0) [0|0] ""  Receiver
 SG_ VCLbtnWindowSwPackDownRF3C2 m0 : 42|1@1+ (1,0) [0|0] ""  Receiver
 SG_ VCLbtnWindowSwPackAutoDownRF3C2 m0 : 43|1@1+ (1,0) [0|0] ""  Receiver
 SG_ VCLbtnWindowSwPackUpRR3C2 m0 : 44|1@1+ (1,0) [0|0] ""  Receiver
 SG_ VCLbtnWindowSwPackAutoUpRR3C2 m0 : 45|1@1+ (1,0) [0|0] ""  Receiver
 SG_ VCLbtnWindowSwPackDownRR3C2 m0 : 46|1@1+ (1,0) [0|0] ""  Receiver
 SG_ VCLbtnWindowSwPackAutoDownRR3C2 m0 : 47|1@1+ (1,0) [0|0] ""  Receiver
 SG_ VCLfrontBuckleSwitch3C2 m0 : 48|2@1+ (1,0) [0|0] ""  Receiver
 SG_ VCLfrontOccupancySwitch3C2 m0 : 50|2@1+ (1,0) [0|0] ""  Receiver
 SG_ VCLrearLeftBuckleSwitch3C2 m0 : 52|2@1+ (1,0) [0|0] ""  Receiver
 SG_ VCLrearCenterOccupancySwitch3C2 m0 : 54|2@1+ (1,0) [0|0] ""  Receiver
 SG_ VCLrearLeftOccupancySwitch3C2 m0 : 56|2@1+ (1,0) [0|0] ""  Receiver
 SG_ VCLrearRightOccupancySwitch3C2 m0 : 58|2@1+ (1,0) [0|0] ""  Receiver
 SG_ VCLbrakePressed3C2 m0 : 60|1@1+ (1,0) [0|0] ""  Receiver
 SG_ VCLrearHVACButtonPressed3C2 m0 : 61|1@1+ (1,0) [0|0] ""  Receiver
 SG_ VCLswcLeftTiltRight3C2 m1 : 3|2@1+ (1,0) [0|0] ""  Receiver
 SG_ VCLswcLeftPressed3C2 m1 : 5|2@1+ (1,0) [0|0] ""  Receiver
 SG_ VCLswcRightTiltLeft3C2 m1 : 8|2@1+ (1,0) [0|0] ""  Receiver
 SG_ VCLswcRightTiltRight3C2 m1 : 10|2@1+ (1,0) [0|0] ""  Receiver
 SG_ VCLswcRightPressed3C2 m1 : 12|2@1+ (1,0) [0|0] ""  Receiver
 SG_ VCLswcLeftTiltLeft3C2 m1 : 14|2@1+ (1,0) [0|0] ""  Receiver
 SG_ VCLswcLeftScrollTicks3C2 m1 : 16|6@1- (1,0) [0|0] ""  Receiver
 SG_ VCLswcRightScrollTicks3C2 m1 : 24|6@1- (1,0) [0|0] ""  Receiver
 SG_ VCLbtnWindowUpLR3C2 m1 : 32|1@1+ (1,0) [0|0] ""  Receiver
 SG_ VCLbtnWindowAutoUpLR3C2 m1 : 33|1@1+ (1,0) [0|0] ""  Receiver
 SG_ VCLbtnWindowDownLR3C2 m1 : 34|1@1+ (1,0) [0|0] ""  Receiver
 SG_ VCLbtnWindowAutoDownLR3C2 m1 : 35|1@1+ (1,0) [0|0] ""  Receiver

BO_ 822 ID336MaxPowerRating: 3 VehicleBus
 SG_ DriveRegenRating336 : 16|8@1+ (1,-100) [-100|155] "kW"  Receiver
 SG_ DrivePowerRating336 : 0|9@1+ (1,0) [0|511] "kW"  Receiver

BO_ 819 ID333UIcharging: 4 VehicleBus
 SG_ UIchargeToSOC333 : 16|10@1+ (0.1,0) [0|102.3] "%"  Receiver
 SG_ UIchargeCurrentLimit333 : 8|7@1+ (1,0) [0|127] "A"  Receiver

BO_ 577 ID241Coolant: 7 VehicleBus
 SG_ VCFPTCoolantFlow241 : 22|9@1+ (0.1,0) [0|51.1] "LPM"  Receiver
 SG_ VCFbattCoolantFlow241 : 0|9@1+ (0.1,0) [0|51.1] "LPM"  Receiver

BO_ 659 ID293chassisControls: 8 VehicleBus
 SG_ UICCtrailerMode293 : 12|1@1+ (1,0) [0|1] ""  Receiver
 SG_ UICCWinchMode293 : 8|2@1+ (1,0) [0|3] ""  Receiver
 SG_ UICCtrafficLightStopSigns293 : 46|2@1+ (1,0) [0|3] ""  Receiver
 SG_ UICCtractionControlMode293 : 2|3@1+ (1,0) [0|7] ""  Receiver
 SG_ UICCsteeringMode293 : 0|2@1+ (1,0) [0|3] ""  Receiver
 SG_ UICCovertakeEnable293 : 18|2@1+ (1,0) [0|3] ""  Receiver
 SG_ UICCnarrowGarages293 : 7|1@1+ (1,0) [0|1] ""  Receiver
 SG_ UICCdebugEnable293 : 17|1@1+ (1,0) [0|1] ""  Receiver
 SG_ UICCUnits293 : 16|1@1+ (1,0) [0|1] ""  Receiver
 SG_ UICCSuspensionLevel293 : 13|3@1+ (1,0) [0|7] ""  Receiver
 SG_ UICCautoParkRequest293 : 28|4@1+ (1,0) [0|0] ""  Receiver
 SG_ UICCaebEnable293 : 20|2@1+ (1,0) [0|0] ""  Receiver
 SG_ UICCaesEnable293 : 22|2@1+ (1,0) [0|0] ""  Receiver
 SG_ UICCahlbEnable293 : 24|2@1+ (1,0) [0|0] ""  Receiver
 SG_ UICCautoLaneChangeEnable293 : 32|2@1+ (1,0) [0|0] ""  Receiver
 SG_ UICCbsdEnable293 : 34|2@1+ (1,0) [0|0] ""  Receiver
 SG_ UICCfcwEnable293 : 36|2@1+ (1,0) [0|0] ""  Receiver
 SG_ UICCfcwSensitivity293 : 38|2@1+ (1,0) [0|0] ""  Receiver
 SG_ UICClatControlEnable293 : 40|2@1+ (1,0) [0|0] ""  Receiver
 SG_ UICCldwEnable293 : 42|2@1+ (1,0) [0|0] ""  Receiver
 SG_ UICCparkBrakeRequest293 : 5|2@1+ (1,0) [0|0] ""  Receiver
 SG_ UICCpedalSafetyEnable293 : 44|2@1+ (1,0) [0|0] ""  Receiver
 SG_ UICCrebootAutopilot293 : 27|1@1+ (1,0) [0|0] ""  Receiver
 SG_ UICCselfParkTune293 : 48|4@1+ (1,0) [0|0] ""  Receiver
 SG_ UICCzeroSpeedConfirmed293 : 10|2@1+ (1,0) [0|0] ""  Receiver
 SG_ UICCchassisControlChecksum293 : 56|8@1+ (1,0) [0|0] ""  Receiver
 SG_ UICCchassisControlCounter293 : 52|4@1+ (1,0) [0|0] ""  Receiver

BO_ 616 ID268SystemPower: 8 VehicleBus
 SG_ SystemRegenPowerMax268 : 32|8@1+ (1,-100) [-100|155] "kW"  Receiver
 SG_ SystemHeatPowerMax268 : 0|8@1+ (0.08,0) [0|31875] "kW"  Receiver
 SG_ SystemHeatPower268 : 8|8@1+ (0.08,0) [0|31875] "kW"  Receiver
 SG_ SystemDrivePowerMax268 : 16|9@1+ (1,0) [0|511] "kW"  Receiver

BO_ 79 ID04FGPSLatLong: 8 ChassisBus
 SG_ GPSLongitude04F : 28|28@1- (1E-006,0) [-1342.17728|1342.17727] "Deg"  Receiver
 SG_ GPSLattitude04F : 0|28@1- (1E-006,0) [-134.217728|134.217727] "Deg"  Receiver

BO_ 978 ID3D2TotalChargeDischarge: 8 VehicleBus
 SG_ TotalDischargeKWh3D2 : 0|32@1+ (0.001,0) [0|4294967.295] "kWh"  Receiver
 SG_ TotalChargeKWh3D2 : 32|32@1+ (0.001,0) [0|4294967.295] "kWh"  Receiver

BO_ 1010 ID3F2BMSCounters: 8 VehicleBus
 SG_ BMSCountersIndex3F2 M : 0|3@1+ (1,0) [0|0] ""  Receiver
 SG_ BMStotalACcharge3F2 m0 : 8|32@1+ (0.001,0) [0|4294967.295] "KWh"  Receiver
 SG_ BMStotalDCcharge3F2 m1 : 8|32@1+ (0.001,0) [0|4294967.295] "KWh"  Receiver
 SG_ BMStotalRegenCharge3F2 m2 : 8|32@1+ (0.001,0) [0|4294967.295] "KWh"  Receiver
 SG_ BMStotalDriveDischarge3F2 m3 : 8|32@1+ (0.001,0) [0|4294967.295] "KWh"  Receiver

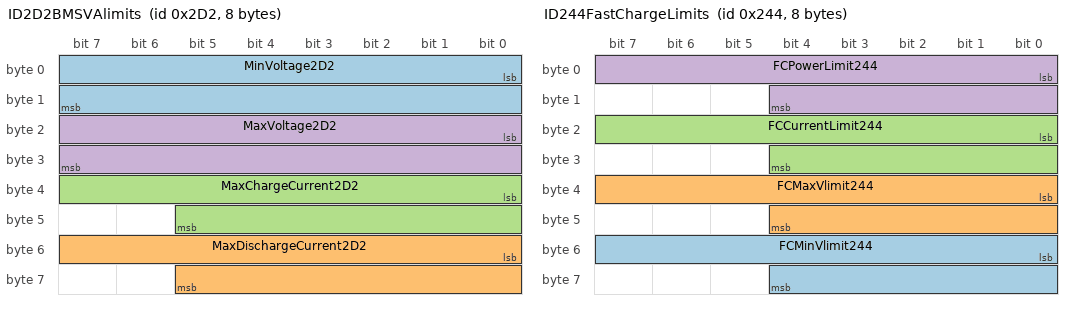
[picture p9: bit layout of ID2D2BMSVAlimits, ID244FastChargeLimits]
BO_ 722 ID2D2BMSVAlimits: 8 VehicleBus
 SG_ MinVoltage2D2 : 0|16@1+ (0.01,0) [0|655.35] "V"  Receiver
 SG_ MaxDischargeCurrent2D2 : 48|14@1+ (0.128,0) [0|2097.024] "A"  Receiver
 SG_ MaxChargeCurrent2D2 : 32|14@1+ (0.1,0) [0|1638.3] "A"  Receiver
 SG_ MaxVoltage2D2 : 16|16@1+ (0.01,0) [0|655.35] "V"  Receiver

BO_ 1345 ID541FastChargeMaxLimits: 8 VehicleBus
 SG_ FCMaxPowerLimit541 : 0|13@1+ (0.062256,0) [0|509.938896] "kW"  Receiver
 SG_ FCMaxCurrentLimit541 : 16|13@1+ (0.073242,0) [0|599.925222] "A"  Receiver

BO_ 580 ID244FastChargeLimits: 8 VehicleBus
 SG_ FCMinVlimit244 : 48|13@1+ (0.073242,0) [0|599.925222] "V"  Receiver
 SG_ FCMaxVlimit244 : 32|13@1+ (0.073242,0) [0|599.925222] "V"  Receiver
 SG_ FCCurrentLimit244 : 16|13@1+ (0.073242,0) [0|599.925222] "A"  Receiver
 SG_ FCPowerLimit244 : 0|13@1+ (0.062256,0) [0|509.938896] "kW"  Receiver

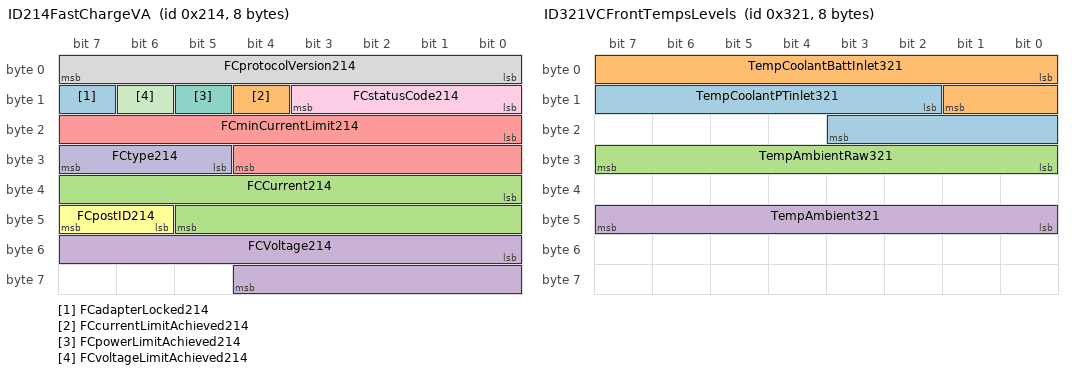
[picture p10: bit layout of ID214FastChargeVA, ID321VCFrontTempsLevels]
BO_ 532 ID214FastChargeVA: 8 VehicleBus
 SG_ FCadapterLocked214 : 15|1@1+ (1,0) [0|0] ""  Receiver
 SG_ FCcurrentLimitAchieved214 : 12|1@1+ (1,0) [0|0] ""  Receiver
 SG_ FCCurrent214 : 32|14@1- (0.0732422,0) [-600.0001024|599.9268602] "A"  Receiver
 SG_ FCVoltage214 : 48|13@1+ (0.0732422,0) [0|599.9268602] "V"  Receiver
 SG_ FCminCurrentLimit214 : 16|13@1+ (0.1,0) [0|819.1] "A"  Receiver
 SG_ FCpostID214 : 46|2@1+ (2,0) [0|6] ""  Receiver
 SG_ FCpowerLimitAchieved214 : 13|1@1+ (1,0) [0|0] ""  Receiver
 SG_ FCprotocolVersion214 : 0|8@1+ (1,0) [0|255] ""  Receiver
 SG_ FCstatusCode214 : 8|4@1+ (1,0) [0|0] ""  Receiver
 SG_ FCtype214 : 29|3@1+ (1,0) [0|7] ""  Receiver
 SG_ FCvoltageLimitAchieved214 : 14|1@1+ (1,0) [0|0] ""  Receiver

BO_ 533 ID215FCisolation: 1 VehicleBus
 SG_ FCIsolation215 : 0|8@1+ (40,0) [0|10200] "kOhm"  Receiver

BO_ 535 ID217FCinfo: 8 VehicleBus
 SG_ FCinfoMux217 M : 0|7@1+ (1,0) [0|127] ""  Receiver
 SG_ FCclass217 m0 : 8|8@1+ (1,0) [0|255] ""  Receiver
 SG_ FCbrand217 m0 : 16|4@1+ (1,0) [0|15] ""  Receiver
 SG_ FCcoolingType217 m0 : 20|4@1+ (1,0) [0|15] ""  Receiver
 SG_ FCuiStopType217 m0 : 24|4@1+ (1,0) [0|15] ""  Receiver

BO_ 801 ID321VCFrontTempsLevels: 8 VehicleBus
 SG_ TempCoolantPTinlet321 : 10|10@1+ (0.125,-40) [-40|87.875] "C"  Receiver
 SG_ TempCoolantBattInlet321 : 0|10@1+ (0.125,-40) [-40|87.875] "C"  Receiver
 SG_ TempAmbientRaw321 : 24|8@1+ (0.5,-40) [-40|87.5] "C"  Receiver
 SG_ TempAmbient321 : 40|8@1+ (0.5,-40) [-40|87.5] "C"  Receiver

BO_ 984 ID3D8Elevation: 8 VehicleBus
 SG_ Elevation3D8 : 0|16@1- (1,0) [-32768|32767] "M"  Receiver

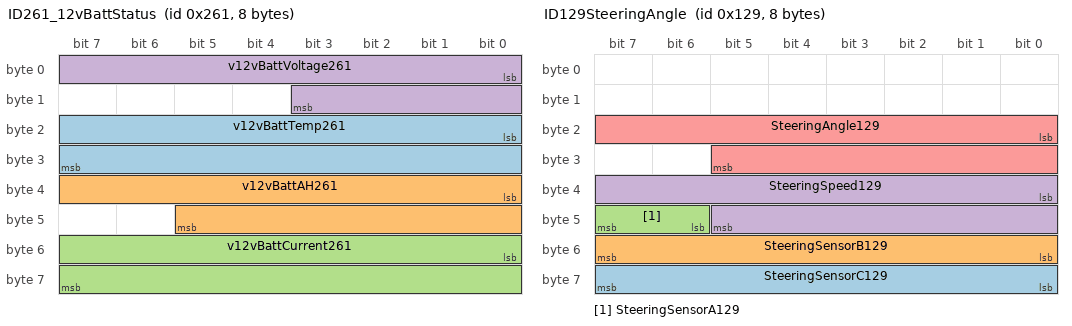
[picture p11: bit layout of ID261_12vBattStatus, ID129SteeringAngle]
BO_ 609 ID261_12vBattStatus: 8 VehicleBus
 SG_ v12vBattTemp261 : 16|16@1- (0.01,0) [-327.68|327.67] "C"  Receiver
 SG_ v12vBattAH261 : 32|14@1+ (0.01,0) [0|163.83] "AH"  Receiver
 SG_ v12vBattCurrent261 : 48|16@1- (0.005,0) [-163.84|163.835] "A"  Receiver
 SG_ v12vBattVoltage261 : 0|12@1+ (0.00544368,0) [0|22.2918696] "V"  Receiver

BO_ 297 ID129SteeringAngle: 8 VehicleBus
 SG_ SteeringSensorC129 : 56|8@1+ (1,0) [0|255] ""  Receiver
 SG_ SteeringSensorB129 : 48|8@1+ (1,0) [0|255] ""  Receiver
 SG_ SteeringSensorA129 : 46|2@1+ (1,0) [0|3] ""  Receiver
 SG_ SteeringSpeed129 : 32|14@1+ (0.5,-4096) [-4096|4095.5] "D/S"  Receiver
 SG_ SteeringAngle129 : 16|14@1+ (0.1,-819.2) [-819.2|819.1] "Deg"  Receiver

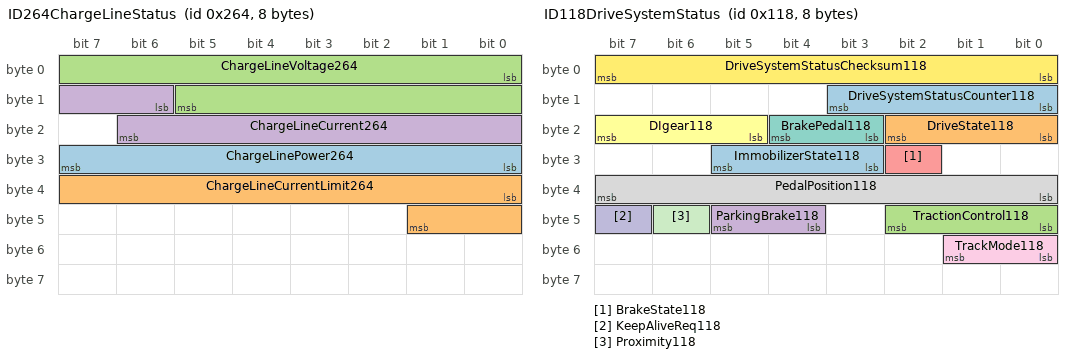
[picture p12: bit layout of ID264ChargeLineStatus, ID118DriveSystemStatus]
BO_ 612 ID264ChargeLineStatus: 8 VehicleBus
 SG_ ChargeLinePower264 : 24|8@1+ (0.1,0) [0|25.5] "kW"  Receiver
 SG_ ChargeLineCurrentLimit264 : 32|10@1+ (0.1,0) [0|102.3] "A"  Receiver
 SG_ ChargeLineVoltage264 : 0|14@1+ (0.0333,0) [0|545.5539] "V"  Receiver
 SG_ ChargeLineCurrent264 : 14|9@1+ (0.1,0) [0|51.1] "A"  Receiver

BO_ 548 ID224PCSDCDCstatus: 8 VehicleBus
 SG_ DCDC12VSupportRtyCnt224 : 44|4@1+ (1,0) [0|0] ""  Receiver
 SG_ DCDC12VSupportStatus224 : 2|2@1+ (1,0) [0|0] ""  Receiver
 SG_ DCDCDischargeRtyCnt224 : 48|4@1+ (1,0) [0|0] ""  Receiver
 SG_ DCDCFaulted224 : 15|1@1+ (1,0) [0|0] ""  Receiver
 SG_ DCDCHvBusDischargeStatus224 : 4|2@1+ (1,0) [0|0] ""  Receiver
 SG_ DCDCInitialPrechargeSubState224 : 59|5@1+ (1,0) [0|0] ""  Receiver
 SG_ DCDCoutputCurrent224 : 16|12@1+ (0.1,0) [0|0] "A"  Receiver
 SG_ DCDCstate224 : 6|4@1+ (1,0) [0|0] ""  Receiver
 SG_ DCDCoutputCurrentMax224 : 29|12@1+ (0.1,0) [0|0] "A"  Receiver
 SG_ DCDCOutputIsLimited224 : 28|1@1+ (1,0) [0|0] ""  Receiver
 SG_ DCDCPrechargeRestartCnt224 : 56|3@1+ (1,0) [0|0] ""  Receiver
 SG_ DCDCPrechargeRtyCnt224 : 41|3@1+ (1,0) [0|0] ""  Receiver
 SG_ DCDCPrechargeStatus224 : 0|2@1+ (1,0) [0|0] ""  Receiver
 SG_ DCDCPwmEnableLine224 : 52|1@1+ (1,0) [0|0] ""  Receiver
 SG_ DCDCSubState224 : 10|5@1+ (1,0) [0|0] ""  Receiver
 SG_ DCDCSupportingFixedLvTarget224 : 53|1@1+ (1,0) [0|0] ""  Receiver
 SG_ PCS_ecuLogUploadRequest224 : 54|2@1+ (1,0) [0|0] ""  Receiver

BO_ 280 ID118DriveSystemStatus: 8 VehicleBus
 SG_ ImmobilizerState118 : 27|3@1+ (1,0) [0|0] ""  Receiver
 SG_ DriveState118 : 16|3@1+ (1,0) [0|7] ""  Receiver
 SG_ TractionControl118 : 40|3@1+ (1,0) [0|7] ""  Receiver
 SG_ ParkingBrake118 : 44|2@1+ (1,0) [0|15] ""  Receiver
 SG_ BrakeState118 : 26|1@1+ (1,0) [0|1] ""  Receiver
 SG_ DIgear118 : 21|3@1+ (1,0) [0|7] ""  Receiver
 SG_ BrakePedal118 : 19|2@1+ (1,0) [0|3] ""  Receiver
 SG_ PedalPosition118 : 32|8@1+ (0.4,0) [0|100] "%"  Receiver
 SG_ TrackMode118 : 48|2@1+ (1,0) [0|255] ""  Receiver
 SG_ KeepAliveReq118 : 47|1@1+ (1,0) [0|0] ""  Receiver
 SG_ Proximity118 : 46|1@1+ (1,0) [0|0] ""  Receiver
 SG_ DriveSystemStatusChecksum118 : 0|8@1+ (1,0) [0|0] ""  Receiver
 SG_ DriveSystemStatusCounter118 : 8|4@1+ (1,0) [0|0] ""  Receiver

BO_ 530 ID212BMSstatus: 8 VehicleBus
 SG_ BMSstate212 : 11|4@1+ (1,0) [0|15] ""  Receiver
 SG_ BMSchargeStatus212 : 32|3@1+ (1,0) [0|7] ""  Receiver
 SG_ BMScontactors212 : 8|3@1+ (1,0) [0|7] ""  Receiver
 SG_ BMSchargePowerAvailable212 : 38|11@1+ (0.125,0) [0|255.875] "kW"  Receiver
 SG_ MinBattTemp212 : 56|8@1+ (0.5,-40) [-40|87.5] "C"  Receiver
 SG_ IsolationR212 : 19|10@1+ (1,0) [0|1023] "kOhm"  Receiver
 SG_ BMSactiveHeatingWorthwhile212 : 5|1@1+ (1,0) [0|0] ""  Receiver
 SG_ BMSchargeRequest212 : 29|1@1+ (1,0) [0|0] ""  Receiver
 SG_ BMSchargeRetryCount212 : 49|4@1+ (1,0) [0|0] ""  Receiver
 SG_ BMScpMiaOnHvs212 : 6|1@1+ (1,0) [0|0] ""  Receiver
 SG_ BMSdiLimpRequest212 : 35|1@1+ (1,0) [0|0] ""  Receiver
 SG_ BMSecuLogUploadRequest212 : 54|2@1+ (1,0) [0|0] ""  Receiver
 SG_ BMSHVstate212 : 16|3@1+ (1,0) [0|0] ""  Receiver
 SG_ BMShvacPowerRequest212 : 0|1@1+ (1,0) [0|0] ""  Receiver
 SG_ BMSkeepWarmRequest212 : 30|1@1+ (1,0) [0|0] ""  Receiver
 SG_ BMSnotEnoughPowerForDrive212 : 1|1@1+ (1,0) [0|0] ""  Receiver
 SG_ BMSnotEnoughPowerForSupport212 : 2|1@1+ (1,0) [0|0] ""  Receiver
 SG_ BMSokToShipByAir212 : 36|1@1+ (1,0) [0|0] ""  Receiver
 SG_ BMSokToShipByLand212 : 37|1@1+ (1,0) [0|0] ""  Receiver
 SG_ BMSpcsPwmEnabled212 : 53|1@1+ (1,0) [0|0] ""  Receiver
 SG_ BMSpreconditionAllowed212 : 3|1@1+ (1,0) [0|0] ""  Receiver
 SG_ BMSupdateAllowed212 : 4|1@1+ (1,0) [0|0] ""  Receiver

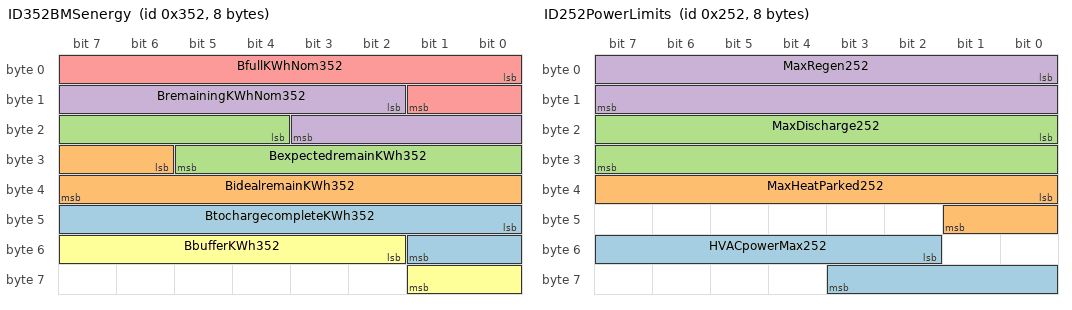
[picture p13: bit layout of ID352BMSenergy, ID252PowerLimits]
BO_ 850 ID352BMSenergy: 8 VehicleBus
 SG_ BtochargecompleteKWh352 : 40|10@1+ (0.1,0) [0|102.3] "kWh"  Receiver
 SG_ BidealremainKWh352 : 30|10@1+ (0.1,0) [0|102.3] "kWh"  Receiver
 SG_ BexpectedremainKWh352 : 20|10@1+ (0.1,0) [0|102.3] "kWh"  Receiver
 SG_ BremainingKWhNom352 : 10|10@1+ (0.1,0) [0|102.3] "kWh"  Receiver
 SG_ BfullKWhNom352 : 0|10@1+ (0.1,0) [0|102.3] "kWh"  Receiver
 SG_ BbufferKWh352 : 50|8@1+ (0.1,0) [0|25.5] "kWh"  Receiver

BO_ 594 ID252PowerLimits: 8 VehicleBus
 SG_ HVACpowerMax252 : 50|10@1+ (0.02,0) [0|20.46] "kW"  Receiver
 SG_ MaxHeatParked252 : 32|10@1+ (0.1,0) [0|102.3] "kW"  Receiver
 SG_ MaxDischarge252 : 16|16@1+ (0.01,0) [0|655.35] "kW"  Receiver
 SG_ MaxRegen252 : 0|16@1+ (0.01,0) [0|655.35] "kW"  Receiver

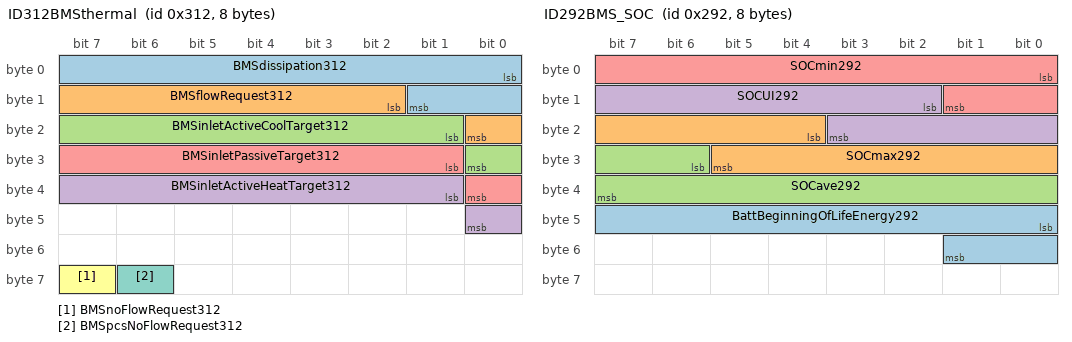
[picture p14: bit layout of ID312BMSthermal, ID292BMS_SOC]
BO_ 786 ID312BMSthermal: 8 VehicleBus
 SG_ BMSdissipation312 : 0|10@1+ (0.02,0) [0|20.46] "kW"  Receiver
 SG_ BMSflowRequest312 : 10|7@1+ (0.3,0) [0|38.1] "LPM"  Receiver
 SG_ BMSinletActiveCoolTarget312 : 17|8@1+ (0.25,10) [10|73.75] "C"  Receiver
 SG_ BMSinletActiveHeatTarget312 : 33|8@1+ (0.25,-25) [-25|38.75] "C"  Receiver
 SG_ BMSinletPassiveTarget312 : 25|8@1+ (0.25,0) [0|63.75] "C"  Receiver
 SG_ BMSnoFlowRequest312 : 63|1@1+ (1,0) [0|1] ""  Receiver
 SG_ BMSpcsNoFlowRequest312 : 62|1@1+ (1,0) [0|1] ""  Receiver

BO_ 658 ID292BMS_SOC: 8 VehicleBus
 SG_ BattBeginningOfLifeEnergy292 : 40|10@1+ (0.1,0) [0|102.3] "kWh" Vector__XXX
 SG_ SOCmax292 : 20|10@1+ (0.1,0) [0|102.3] "%"  Receiver
 SG_ SOCave292 : 30|10@1+ (0.1,0) [0|102.3] "%"  Receiver
 SG_ SOCUI292 : 10|10@1+ (0.1,0) [0|102.3] "%"  Receiver
 SG_ SOCmin292 : 0|10@1+ (0.1,0) [0|102.3] "%"  Receiver

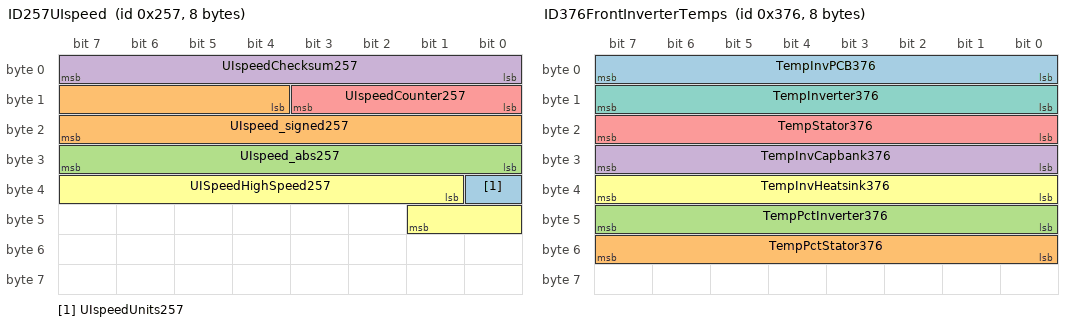
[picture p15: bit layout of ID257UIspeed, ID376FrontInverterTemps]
BO_ 599 ID257UIspeed: 8 VehicleBus
 SG_ UIspeedUnits257 : 32|1@1+ (1,0) [0|0] ""  Receiver
 SG_ UIspeed_signed257 : 12|12@1+ (0.05,-25) [-25|179.75] "MPHKPH"  Receiver
 SG_ UIspeed_abs257 : 24|8@1+ (1,0) [0|255] "MPHKPH"  Receiver
 SG_ UIspeedChecksum257 : 0|8@1+ (1,0) [0|0] ""  Receiver
 SG_ UIspeedCounter257 : 8|4@1+ (1,0) [0|0] ""  Receiver
 SG_ UISpeedHighSpeed257 : 33|9@1+ (1,0) [0|510] "MPHKPH"  Receiver

BO_ 1029 ID405VIN: 8 VehicleBus
 SG_ VINB405 m17 : 8|56@1+ (1,0) [0|7.2057594038E+016] ""  Receiver
 SG_ VINC405 m18 : 8|56@1+ (1,0) [0|7.2057594038E+016] ""  Receiver
 SG_ VINA405 m16 : 8|56@1+ (1,0) [0|7.2057594038E+016] ""  Receiver
 SG_ mux405 M : 0|8@1+ (1,0) [0|255] ""  Receiver

BO_ 1310 ID51EChgConnectorInfo: 8 VehicleBus
 SG_ CHGmodelA51E m25 : 8|56@1+ (1,0) [0|7.2057594038E+016] ""  Receiver
 SG_ CHGmodelB51E m26 : 8|56@1+ (1,0) [0|7.20575940379279E+016] ""  Receiver
 SG_ mux51E M : 0|8@1+ (1,0) [0|255] ""  Receiver

BO_ 886 ID376FrontInverterTemps: 8 VehicleBus
 SG_ TempInvPCB376 : 0|8@1+ (1,-40) [-40|215] "C"  Receiver
 SG_ TempPctStator376 : 48|8@1+ (0.4,0) [0|102] "%"  Receiver
 SG_ TempPctInverter376 : 40|8@1+ (0.4,0) [0|102] "%"  Receiver
 SG_ TempInvCapbank376 : 24|8@1+ (1,-40) [-40|215] "C"  Receiver
 SG_ TempStator376 : 16|8@1+ (1,-40) [-40|215] "C"  Receiver
 SG_ TempInvHeatsink376 : 32|8@1+ (1,-40) [-40|215] "C"  Receiver
 SG_ TempInverter376 : 8|8@1+ (1,-40) [-40|215] "C"  Receiver

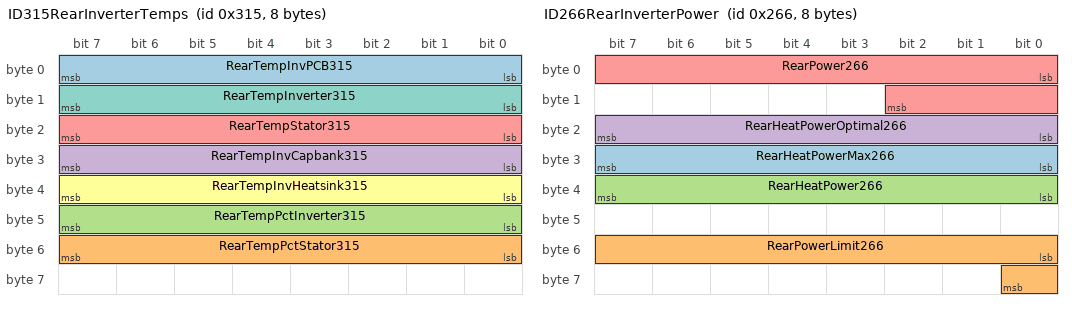
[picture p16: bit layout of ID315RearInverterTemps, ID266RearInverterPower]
BO_ 789 ID315RearInverterTemps: 8 VehicleBus
 SG_ RearTempInvPCB315 : 0|8@1+ (1,-40) [-40|215] "C"  Receiver
 SG_ RearTempPctStator315 : 48|8@1+ (0.4,0) [0|102] "%"  Receiver
 SG_ RearTempPctInverter315 : 40|8@1+ (0.4,0) [0|102] "%"  Receiver
 SG_ RearTempInvCapbank315 : 24|8@1+ (1,-40) [-40|215] "C"  Receiver
 SG_ RearTempStator315 : 16|8@1+ (1,-40) [-40|215] "C"  Receiver
 SG_ RearTempInvHeatsink315 : 32|8@1+ (1,-40) [-40|215] "C"  Receiver
 SG_ RearTempInverter315 : 8|8@1+ (1,-40) [-40|215] "C"  Receiver

BO_ 340 ID154RearTorqueOld: 8 VehicleBus
 SG_ RAWTorqueRear154 : 40|12@1- (0.25,0) [-512|511.75] "NM"  Receiver

BO_ 950 ID3B6odometer: 4 VehicleBus
 SG_ Odometer3B6 : 0|32@1+ (0.001,0) [0|4294967.295] "KM"  Receiver

BO_ 614 ID266RearInverterPower: 8 VehicleBus
 SG_ RearHeatPowerMax266 : 24|8@1+ (0.08,0) [0|20.4] "kW"  Receiver
 SG_ RearPowerLimit266 : 48|9@1+ (0.25,165) [165|292.75] "kW"  Receiver
 SG_ RearHeatPower266 : 32|8@1+ (0.08,0) [0|20.4] "kW"  Receiver
 SG_ RearHeatPowerOptimal266 : 16|8@1+ (0.08,0) [0|20.4] "kW"  Receiver
 SG_ RearPower266 : 0|11@1- (0.5,0) [-512|511.5] "kW"  Receiver

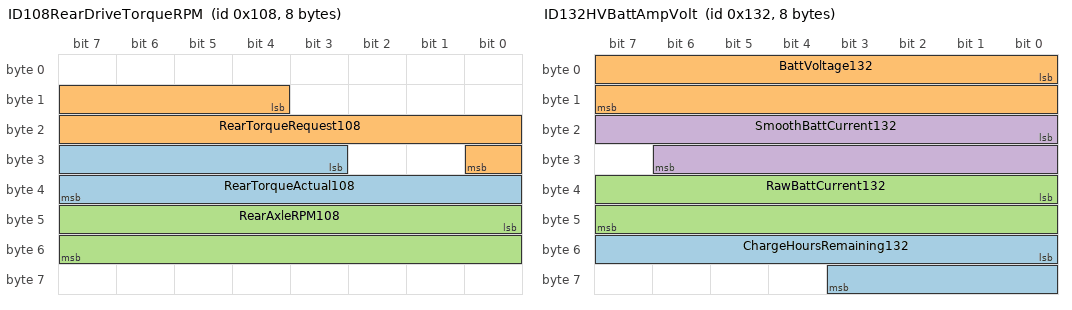
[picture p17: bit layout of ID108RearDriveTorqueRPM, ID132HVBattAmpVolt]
BO_ 264 ID108RearDriveTorqueRPM: 8 VehicleBus
 SG_ RearTorqueActual108 : 27|13@1- (2,0) [-8192|8190] "NM"  Receiver
 SG_ RearTorqueRequest108 : 12|13@1- (2,0) [-8192|8190] "NM"  Receiver
 SG_ RearAxleRPM108 : 40|16@1- (0.1,0) [-3276.8|3276.7] "RPM"  Receiver

BO_ 306 ID132HVBattAmpVolt: 8 VehicleBus
 SG_ ChargeHoursRemaining132 : 48|12@1+ (1,0) [0|4095] "Min"  Receiver
 SG_ BattVoltage132 : 0|16@1+ (0.01,0) [0|655.35] "V"  Receiver
 SG_ RawBattCurrent132 : 32|16@1- (-0.05,500) [-1138.35|2138.4] "A"  Receiver
 SG_ SmoothBattCurrent132 : 16|15@1- (-0.1,0) [-1638.3|1638.4] "A"  Receiver

BO_ 294 ID126RearHVStatus: 3 VehicleBus
 SG_ RearHighVoltage126 : 0|10@1+ (0.5,0) [0|500] "V"  Receiver
 SG_ RearMotorCurrent126 : 10|11@1+ (1,0) [0|2047] "A"  Receiver

BO_ 421 ID1A5FrontHVStatus: 3 VehicleBus
 SG_ FrontHighVoltage1A5 : 0|10@1+ (0.5,0) [0|500] "V"  Receiver
 SG_ FrontMotorCurrent1A5 : 10|11@1+ (1,0) [0|2047] "A"  Receiver

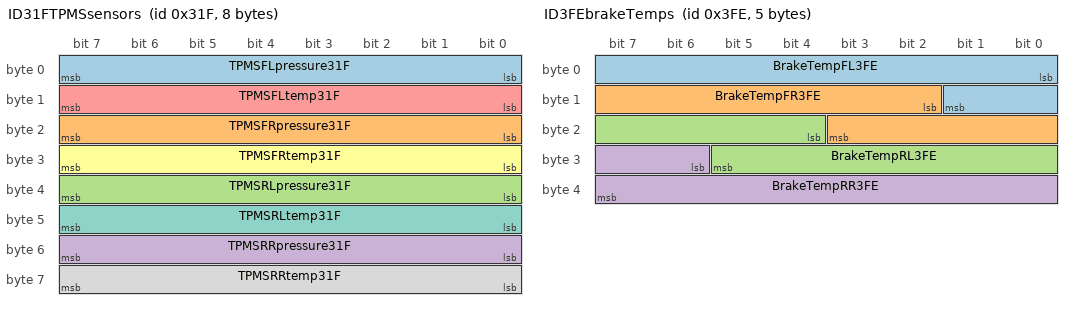
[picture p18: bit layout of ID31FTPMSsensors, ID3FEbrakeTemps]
BO_ 799 ID31FTPMSsensors: 8 ChassisBus
 SG_ TPMSFLpressure31F : 0|8@1+ (0.025,0) [0|0] "bar"  Receiver
 SG_ TPMSFRpressure31F : 16|8@1+ (0.025,0) [0|0] "bar"  Receiver
 SG_ TPMSRLpressure31F : 32|8@1+ (0.025,0) [0|0] "bar"  Receiver
 SG_ TPMSRRpressure31F : 48|8@1+ (0.025,0) [0|0] "bar"  Receiver
 SG_ TPMSFLtemp31F : 8|8@1+ (1,-40) [0|0] "C"  Receiver
 SG_ TPMSFRtemp31F : 24|8@1+ (1,-40) [0|0] "C"  Receiver
 SG_ TPMSRLtemp31F : 40|8@1+ (1,-40) [0|0] "C"  Receiver
 SG_ TPMSRRtemp31F : 56|8@1+ (1,-40) [0|0] "C"  Receiver

BO_ 1022 ID3FEbrakeTemps: 5 VehicleBus
 SG_ BrakeTempFL3FE : 0|10@1+ (1,-40) [0|0] "C"  Receiver
 SG_ BrakeTempFR3FE : 10|10@1+ (1,-40) [0|0] "C"  Receiver
 SG_ BrakeTempRL3FE : 20|10@1+ (1,-40) [0|0] "C"  Receiver
 SG_ BrakeTempRR3FE : 30|10@1+ (1,-40) [0|0] "C"  Receiver

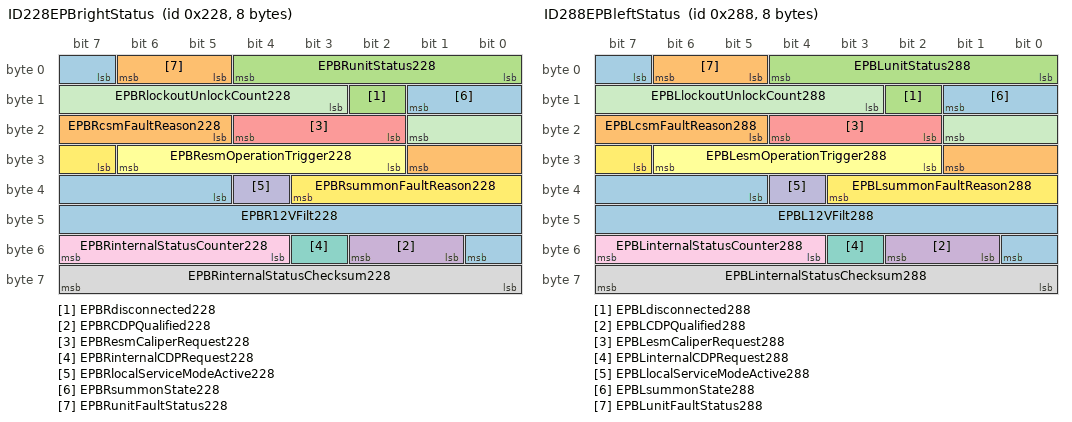
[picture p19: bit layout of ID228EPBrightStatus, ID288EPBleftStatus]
BO_ 552 ID228EPBrightStatus: 8 VehicleBus
 SG_ EPBR12VFilt228 : 37|12@1+ (0.00544368,0) [0|0] "V"  Receiver
 SG_ EPBRcsmFaultReason228 : 21|5@1+ (1,0) [0|0] ""  Receiver
 SG_ EPBRdisconnected228 : 10|1@1+ (1,0) [0|0] ""  Receiver
 SG_ EPBRCDPQualified228 : 49|2@1+ (1,0) [0|0] ""  Receiver
 SG_ EPBResmCaliperRequest228 : 18|3@1+ (1,0) [0|0] ""  Receiver
 SG_ EPBResmOperationTrigger228 : 26|5@1+ (1,0) [0|0] ""  Receiver
 SG_ EPBRinternalCDPRequest228 : 51|1@1+ (1,0) [0|0] ""  Receiver
 SG_ EPBRinternalStatusChecksum228 : 56|8@1+ (1,0) [0|0] ""  Receiver
 SG_ EPBRinternalStatusCounter228 : 52|4@1+ (1,0) [0|0] ""  Receiver
 SG_ EPBRlocalServiceModeActive228 : 36|1@1+ (1,0) [0|0] ""  Receiver
 SG_ EPBRlockoutUnlockCount228 : 11|7@1+ (1,0) [0|0] ""  Receiver
 SG_ EPBRsummonFaultReason228 : 31|5@1+ (1,0) [0|0] ""  Receiver
 SG_ EPBRsummonState228 : 7|3@1+ (1,0) [0|0] ""  Receiver
 SG_ EPBRunitFaultStatus228 : 5|2@1+ (1,0) [0|0] ""  Receiver
 SG_ EPBRunitStatus228 : 0|5@1+ (1,0) [0|0] ""  Receiver

BO_ 648 ID288EPBleftStatus: 8 VehicleBus
 SG_ EPBL12VFilt288 : 37|12@1+ (0.00544368,0) [0|0] "V"  Receiver
 SG_ EPBLcsmFaultReason288 : 21|5@1+ (1,0) [0|0] ""  Receiver
 SG_ EPBLdisconnected288 : 10|1@1+ (1,0) [0|0] ""  Receiver
 SG_ EPBLCDPQualified288 : 49|2@1+ (1,0) [0|0] ""  Receiver
 SG_ EPBLesmCaliperRequest288 : 18|3@1+ (1,0) [0|0] ""  Receiver
 SG_ EPBLesmOperationTrigger288 : 26|5@1+ (1,0) [0|0] ""  Receiver
 SG_ EPBLinternalCDPRequest288 : 51|1@1+ (1,0) [0|0] ""  Receiver
 SG_ EPBLinternalStatusChecksum288 : 56|8@1+ (1,0) [0|0] ""  Receiver
 SG_ EPBLinternalStatusCounter288 : 52|4@1+ (1,0) [0|0] ""  Receiver
 SG_ EPBLlocalServiceModeActive288 : 36|1@1+ (1,0) [0|0] ""  Receiver
 SG_ EPBLlockoutUnlockCount288 : 11|7@1+ (1,0) [0|0] ""  Receiver
 SG_ EPBLsummonFaultReason288 : 31|5@1+ (1,0) [0|0] ""  Receiver
 SG_ EPBLsummonState288 : 7|3@1+ (1,0) [0|0] ""  Receiver
 SG_ EPBLunitFaultStatus288 : 5|2@1+ (1,0) [0|0] ""  Receiver
 SG_ EPBLunitStatus288 : 0|5@1+ (1,0) [0|0] ""  Receiver

BO_ 2047 ID7FFcarConfig: 8 VehicleBus
 SG_ CFGrearDriveUnitType7FF m3 : 21|1@1+ (1,0) [0|0] ""  Receiver
 SG_ CFGmuxindex7FF M : 0|8@1+ (1,0) [0|0] ""  Receiver
 SG_ CFGairSuspension7FF m3 : 22|2@1+ (1,0) [0|0] ""  Receiver
 SG_ CFGepasType7FF m1 : 9|1@1+ (1,0) [0|0] ""  Receiver
 SG_ CFGdrivetrainType7FF m1 : 10|1@1+ (1,0) [0|0] ""  Receiver
 SG_ CFGrightHandDrive7FF m1 : 11|1@1+ (1,0) [0|0] ""  Receiver
 SG_ CFGcountry7FF m1 : 16|16@1+ (1,0) [0|0] ""  Receiver
 SG_ CFGheatedWipers7FF m2 : 8|1@1+ (1,0) [0|0] ""  Receiver
 SG_ CFGfrontSeatHeaters7FF m2 : 9|1@1+ (1,0) [0|0] ""  Receiver
 SG_ CFGrearSeatHeaters7FF m2 : 10|1@1+ (1,0) [0|0] ""  Receiver
 SG_ CFGpackEnergy7FF m3 : 32|5@1+ (1,0) [0|0] ""  Receiver
 SG_ CFGbrakeHWType7FF m2 : 55|1@1+ (1,0) [0|0] ""  Receiver
 SG_ CFGhomelinkType7FF m2 : 13|1@1+ (1,0) [0|0] ""  Receiver
 SG_ CFGvdcType7FF m2 : 14|1@1+ (1,0) [0|0] ""  Receiver
 SG_ CFGxcpIbst7FF m2 : 15|1@1+ (1,0) [0|0] ""  Receiver
 SG_ CFGxcpESP7FF m2 : 16|1@1+ (1,0) [0|0] ""  Receiver
 SG_ CFGmemoryMirrors7FF m2 : 17|1@1+ (1,0) [0|0] ""  Receiver
 SG_ CFGpowerSteeringColumn7FF m2 : 18|1@1+ (1,0) [0|0] ""  Receiver
 SG_ CFGinteriorLighting7FF m2 : 19|1@1+ (1,0) [0|0] ""  Receiver
 SG_ CFGfrontFogLamps7FF m2 : 20|1@1+ (1,0) [0|0] ""  Receiver
 SG_ CFGheadlamps7FF m2 : 21|1@1+ (1,0) [0|0] ""  Receiver
 SG_ CFGaudioType7FF m3 : 30|2@1+ (1,0) [0|0] ""  Receiver
 SG_ CFGlumbarECUType7FF m2 : 23|1@1+ (1,0) [0|0] ""  Receiver
 SG_ CFGibstWakeType7FF m2 : 24|1@1+ (1,0) [0|0] ""  Receiver
 SG_ CFGfrontSeatType7FF m2 : 25|1@1+ (1,0) [0|1] ""  Receiver
 SG_ CFGauxParkLamps7FF m2 : 26|2@1+ (1,0) [0|3] ""  Receiver
 SG_ CFGpedestrianWarningSound7FF m2 : 54|1@1+ (1,0) [0|0] ""  Receiver
 SG_ CFGhvacQuietSnorkelType7FF m2 : 28|1@1+ (1,0) [0|0] ""  Receiver
 SG_ CFGhvacPanelVaneType7FF m2 : 29|1@1+ (1,0) [0|0] ""  Receiver
 SG_ CFGCabinBlowerCtrlType7FF m2 : 30|1@1+ (1,0) [0|0] ""  Receiver
 SG_ CFGperformancePackage7FF m3 : 12|3@1+ (1,0) [0|0] ""  Receiver
 SG_ CFGeBuckConfig7FF m2 : 32|1@1+ (1,0) [0|0] ""  Receiver
 SG_ CFGwindshieldType7FF m2 : 33|1@1+ (1,0) [0|0] ""  Receiver
 SG_ CFGactiveHighBeam7FF m2 : 34|1@1+ (1,0) [0|0] ""  Receiver
 SG_ CFGairbagCutoffSwitch7FF m2 : 35|1@1+ (1,0) [0|0] ""  Receiver
 SG_ CFGintrusionSensorType7FF m2 : 36|1@1+ (1,0) [0|0] ""  Receiver
 SG_ CFGspoilerType7FF m2 : 37|1@1+ (1,0) [0|0] ""  Receiver
 SG_ CFGrearGlassType7FF m2 : 38|1@1+ (1,0) [0|0] ""  Receiver
 SG_ CFGrearFogLamps7FF m2 : 39|1@1+ (1,0) [0|0] ""  Receiver
 SG_ CFGroofType7FF m2 : 40|2@1+ (1,0) [0|3] ""  Receiver
 SG_ CFGautopilot7FF m2 : 42|3@1+ (1,0) [0|3] ""  Receiver
 SG_ CFGsuperchargingAccess7FF m2 : 45|2@1+ (1,0) [0|3] ""  Receiver
 SG_ CFGwheelType7FF m3 : 48|7@1+ (1,0) [0|127] ""  Receiver
 SG_ CFGexteriorColor7FF m2 : 48|3@1+ (1,0) [0|7] ""  Receiver
 SG_ CFGnumberHVILNodes7FF m2 : 51|3@1+ (1,1) [1|8] ""  Receiver
 SG_ CFGrestraintsHardwareType7FF m1 : 48|8@1+ (1,0) [0|31] ""  Receiver
 SG_ CFGeCallEnabled7FF m2 : 63|1@1+ (1,0) [0|31] ""  Receiver
 SG_ CFGchassisType7FF m3 : 18|3@1+ (1,0) [0|31] ""  Receiver
 SG_ CFGmapRegion7FF m3 : 8|4@1+ (1,0) [0|31] ""  Receiver
 SG_ CFGpassengerOccupancySensorType7 m3 : 17|1@1+ (1,0) [0|31] ""  Receiver
 SG_ CFGimmersiveAudio7FF m3 : 56|2@1+ (1,0) [0|31] ""  Receiver
 SG_ CFGrearLightType7FF m3 : 16|1@1+ (1,0) [0|31] ""  Receiver
 SG_ CFGtrackModePackage7FF m1 : 62|1@1+ (1,0) [0|31] ""  Receiver
 SG_ CFGroofGlassType7FF m1 : 61|1@1+ (1,0) [0|31] ""  Receiver
 SG_ CFGfrontSeatReclinerHardware7FF m3 : 37|2@1+ (1,0) [0|31] ""  Receiver
 SG_ CFGrefrigerantType7FF m3 : 45|2@1+ (1,0) [0|31] ""  Receiver
 SG_ CFGplcSupportType7FF m3 : 28|2@1+ (1,0) [0|31] ""  Receiver
 SG_ CFGespValveType7FF m3 : 40|2@1+ (1,0) [0|31] ""  Receiver
 SG_ CFGtowPackage7FF m3 : 15|1@1+ (1,0) [0|31] ""  Receiver
 SG_ CFGsoftRange7FF m3 : 42|3@1+ (1,0) [0|31] ""  Receiver
 SG_ CFGtireType7FF m1 : 32|3@1+ (1,0) [0|31] ""  Receiver
 SG_ CFGdasHw7FF m1 : 40|3@1+ (1,0) [0|31] ""  Receiver
 SG_ CFGconnectivityPackage7FF m3 : 27|1@1+ (1,0) [0|31] ""  Receiver
 SG_ CFGtpmsType7FF m2 : 11|1@1+ (1,0) [0|31] ""  Receiver

BO_ 818 ID332BattCellMinMax: 6 VehicleBus
 SG_ BattCellMultiplexer332 M : 0|2@1+ (1,0) [0|0] ""  Receiver
 SG_ BattCellTempMaxNum332 m0 : 2|4@1+ (1,0) [0|0] ""  Receiver
 SG_ BattCellTempMinNum332 m0 : 8|4@1+ (1,0) [0|0] ""  Receiver
 SG_ BattCellTempMax332 m0 : 16|8@1+ (0.5,-40) [0|0] "C"  Receiver
 SG_ BattCellTempMin332 m0 : 24|8@1+ (0.5,-40) [0|0] "C"  Receiver
 SG_ BattCellModelTMax332 m0 : 32|8@1+ (0.5,-40) [0|0] "C"  Receiver
 SG_ BattCellModelTMin332 m0 : 40|8@1+ (0.5,-40) [0|0] "C"  Receiver
 SG_ BattCellBrickVoltageMax332 m1 : 2|12@1+ (0.002,0) [0|0] "V"  Receiver
 SG_ BattCellBrickVoltageMin332 m1 : 16|12@1+ (0.002,0) [0|0] "V"  Receiver
 SG_ BattCellBrickVoltageMaxNum332 m1 : 32|7@1+ (1,1) [0|0] ""  Receiver
 SG_ BattCellBrickVoltageMinNum332 m1 : 40|7@1+ (1,1) [0|0] ""  Receiver

BO_ 1025 ID401CellVoltages: 8 VehicleBus
 SG_ MultiplexSelector M : 0|8@1+ (1,0) [0|0] ""  Receiver
 SG_ StatusFlags : 8|8@1+ (1,0) [0|0] ""  Receiver
 SG_ Cell0 m0 : 16|16@1+ (0.0001,0) [0|0] "V"  Receiver
 SG_ Cell1 m0 : 32|16@1+ (0.0001,0) [0|0] "V"  Receiver
 SG_ Cell2 m0 : 48|16@1+ (0.0001,0) [0|0] "V"  Receiver
 SG_ Cell3 m1 : 16|16@1+ (0.0001,0) [0|0] "V"  Receiver
 SG_ Cell4 m1 : 32|16@1+ (0.0001,0) [0|0] "V"  Receiver
 SG_ Cell5 m1 : 48|16@1+ (0.0001,0) [0|0] "V"  Receiver
 SG_ Cell6 m2 : 16|16@1+ (0.0001,0) [0|0] "V"  Receiver
 SG_ Cell7 m2 : 32|16@1+ (0.0001,0) [0|0] "V"  Receiver
 SG_ Cell8 m2 : 48|16@1+ (0.0001,0) [0|0] "V"  Receiver
 SG_ Cell9 m3 : 16|16@1+ (0.0001,0) [0|0] "V"  Receiver
 SG_ Cell10 m3 : 32|16@1+ (0.0001,0) [0|0] "V"  Receiver
 SG_ Cell11 m3 : 48|16@1+ (0.0001,0) [0|0] "V"  Receiver
 SG_ Cell12 m4 : 16|16@1+ (0.0001,0) [0|0] "V"  Receiver
 SG_ Cell13 m4 : 32|16@1+ (0.0001,0) [0|0] "V"  Receiver
 SG_ Cell14 m4 : 48|16@1+ (0.0001,0) [0|0] "V"  Receiver
 SG_ Cell15 m5 : 16|16@1+ (0.0001,0) [0|0] "V"  Receiver
 SG_ Cell16 m5 : 32|16@1+ (0.0001,0) [0|0] "V"  Receiver
 SG_ Cell17 m5 : 48|16@1+ (0.0001,0) [0|0] "V"  Receiver
 SG_ Cell18 m6 : 16|16@1+ (0.0001,0) [0|0] "V"  Receiver
 SG_ Cell19 m6 : 32|16@1+ (0.0001,0) [0|0] "V"  Receiver
 SG_ Cell20 m6 : 48|16@1+ (0.0001,0) [0|0] "V"  Receiver
 SG_ Cell21 m7 : 16|16@1+ (0.0001,0) [0|0] "V"  Receiver
 SG_ Cell22 m7 : 32|16@1+ (0.0001,0) [0|0] "V"  Receiver
 SG_ Cell23 m7 : 48|16@1+ (0.0001,0) [0|0] "V"  Receiver
 SG_ Cell24 m8 : 16|16@1+ (0.0001,0) [0|0] "V"  Receiver
 SG_ Cell25 m8 : 32|16@1+ (0.0001,0) [0|0] "V"  Receiver
 SG_ Cell26 m8 : 48|16@1+ (0.0001,0) [0|0] "V"  Receiver
 SG_ Cell27 m9 : 16|16@1+ (0.0001,0) [0|0] "V"  Receiver
 SG_ Cell28 m9 : 32|16@1+ (0.0001,0) [0|0] "V"  Receiver
 SG_ Cell29 m9 : 48|16@1+ (0.0001,0) [0|0] "V"  Receiver
 SG_ Cell30 m10 : 16|16@1+ (0.0001,0) [0|0] "V"  Receiver
 SG_ Cell31 m10 : 32|16@1+ (0.0001,0) [0|0] "V"  Receiver
 SG_ Cell32 m10 : 48|16@1+ (0.0001,0) [0|0] "V"  Receiver
 SG_ Cell34 m11 : 16|16@1+ (0.0001,0) [0|0] "V"  Receiver
 SG_ Cell33 m11 : 32|16@1+ (0.0001,0) [0|0] "V"  Receiver
 SG_ Cell35 m11 : 48|16@1+ (0.0001,0) [0|0] "V"  Receiver
 SG_ Cell36 m12 : 16|16@1+ (0.0001,0) [0|0] "V"  Receiver
 SG_ Cell37 m12 : 32|16@1+ (0.0001,0) [0|0] "V"  Receiver
 SG_ Cell38 m12 : 48|16@1+ (0.0001,0) [0|0] "V"  Receiver
 SG_ Cell39 m13 : 16|16@1+ (0.0001,0) [0|0] "V"  Receiver
 SG_ Cell40 m13 : 32|16@1+ (0.0001,0) [0|0] "V"  Receiver
 SG_ Cell41 m13 : 48|16@1+ (0.0001,0) [0|0] "V"  Receiver
 SG_ Cell42 m14 : 16|16@1+ (0.0001,0) [0|0] "V"  Receiver
 SG_ Cell43 m14 : 32|16@1+ (0.0001,0) [0|0] "V"  Receiver
 SG_ Cell44 m14 : 48|16@1+ (0.0001,0) [0|0] "V"  Receiver
 SG_ Cell45 m15 : 16|16@1+ (0.0001,0) [0|0] "V"  Receiver
 SG_ Cell46 m15 : 32|16@1+ (0.0001,0) [0|0] "V"  Receiver
 SG_ Cell47 m15 : 48|16@1+ (0.0001,0) [0|0] "V"  Receiver
 SG_ Cell48 m16 : 16|16@1+ (0.0001,0) [0|0] "V"  Receiver
 SG_ Cell49 m16 : 32|16@1+ (0.0001,0) [0|0] "V"  Receiver
 SG_ Cell50 m16 : 48|16@1+ (0.0001,0) [0|0] "V"  Receiver
 SG_ Cell51 m17 : 16|16@1+ (0.0001,0) [0|0] "V"  Receiver
 SG_ Cell52 m17 : 32|16@1+ (0.0001,0) [0|0] "V"  Receiver
 SG_ Cell53 m17 : 48|16@1+ (0.0001,0) [0|0] "V"  Receiver
 SG_ Cell54 m18 : 16|16@1+ (0.0001,0) [0|0] "V"  Receiver
 SG_ Cell55 m18 : 32|16@1+ (0.0001,0) [0|0] "V"  Receiver
 SG_ Cell56 m18 : 48|16@1+ (0.0001,0) [0|0] "V"  Receiver
 SG_ Cell57 m19 : 16|16@1+ (0.0001,0) [0|0] "V"  Receiver
 SG_ Cell58 m19 : 32|16@1+ (0.0001,0) [0|0] "V"  Receiver
 SG_ Cell59 m19 : 48|16@1+ (0.0001,0) [0|0] "V"  Receiver
 SG_ Cell60 m20 : 16|16@1+ (0.0001,0) [0|0] "V"  Receiver
 SG_ Cell61 m20 : 32|16@1+ (0.0001,0) [0|0] "V"  Receiver
 SG_ Cell62 m20 : 48|16@1+ (0.0001,0) [0|0] "V"  Receiver
 SG_ Cell63 m21 : 16|16@1+ (0.0001,0) [0|0] "V"  Receiver
 SG_ Cell64 m21 : 32|16@1+ (0.0001,0) [0|0] "V"  Receiver
 SG_ Cell65 m21 : 48|16@1+ (0.0001,0) [0|0] "V"  Receiver
 SG_ Cell66 m22 : 16|16@1+ (0.0001,0) [0|0] "V"  Receiver
 SG_ Cell67 m22 : 32|16@1+ (0.0001,0) [0|0] "V"  Receiver
 SG_ Cell68 m22 : 48|16@1+ (0.0001,0) [0|0] "V"  Receiver
 SG_ Cell69 m23 : 16|16@1+ (0.0001,0) [0|0] "V"  Receiver
 SG_ Cell70 m23 : 32|16@1+ (0.0001,0) [0|0] "V"  Receiver
 SG_ Cell71 m23 : 48|16@1+ (0.0001,0) [0|0] "V"  Receiver
 SG_ Cell72 m24 : 16|16@1+ (0.0001,0) [0|0] "V"  Receiver
 SG_ Cell73 m24 : 32|16@1+ (0.0001,0) [0|0] "V"  Receiver
 SG_ Cell74 m24 : 48|16@1+ (0.0001,0) [0|0] "V"  Receiver
 SG_ Cell75 m25 : 16|16@1+ (0.0001,0) [0|0] "V"  Receiver
 SG_ Cell76 m25 : 32|16@1+ (0.0001,0) [0|0] "V"  Receiver
 SG_ Cell77 m25 : 48|16@1+ (0.0001,0) [0|0] "V"  Receiver
 SG_ Cell78 m26 : 16|16@1+ (0.0001,0) [0|0] "V"  Receiver
 SG_ Cell79 m26 : 32|16@1+ (0.0001,0) [0|0] "V"  Receiver
 SG_ Cell80 m26 : 48|16@1+ (0.0001,0) [0|0] "V"  Receiver
 SG_ Cell81 m27 : 16|16@1+ (0.0001,0) [0|0] "V"  Receiver
 SG_ Cell82 m27 : 32|16@1+ (0.0001,0) [0|0] "V"  Receiver
 SG_ Cell83 m27 : 48|16@1+ (0.0001,0) [0|0] "V"  Receiver
 SG_ Cell84 m28 : 16|16@1+ (0.0001,0) [0|0] "V"  Receiver
 SG_ Cell85 m28 : 32|16@1+ (0.0001,0) [0|0] "V"  Receiver
 SG_ Cell86 m28 : 48|16@1+ (0.0001,0) [0|0] "V"  Receiver
 SG_ Cell87 m29 : 16|16@1+ (0.0001,0) [0|0] "V"  Receiver
 SG_ Cell88 m29 : 32|16@1+ (0.0001,0) [0|0] "V"  Receiver
 SG_ Cell89 m29 : 48|16@1+ (0.0001,0) [0|0] "V"  Receiver
 SG_ Cell90 m30 : 16|16@1+ (0.0001,0) [0|0] "V"  Receiver
 SG_ Cell91 m30 : 32|16@1+ (0.0001,0) [0|0] "V"  Receiver
 SG_ Cell92 m30 : 48|16@1+ (0.0001,0) [0|0] "V"  Receiver
 SG_ Cell93 m31 : 16|16@1+ (0.0001,0) [0|0] "V"  Receiver
 SG_ Cell94 m31 : 32|16@1+ (0.0001,0) [0|0] "V"  Receiver
 SG_ Cell95 m31 : 48|16@1+ (0.0001,0) [0|0] "V"  Receiver
 SG_ Cell96 m32 : 16|16@1+ (0.0001,0) [0|0] "V"  Receiver
 SG_ Cell97 m32 : 32|16@1+ (0.0001,0) [0|0] "V"  Receiver
 SG_ Cell98 m32 : 48|16@1+ (0.0001,0) [0|0] "V"  Receiver
 SG_ Cell99 m33 : 16|16@1+ (0.0001,0) [0|0] "V"  Receiver
 SG_ Cell100 m33 : 32|16@1+ (0.0001,0) [0|0] "V"  Receiver
 SG_ Cell101 m33 : 48|16@1+ (0.0001,0) [0|0] "V"  Receiver
 SG_ Cell102 m34 : 16|16@1+ (0.0001,0) [0|0] "V"  Receiver
 SG_ Cell103 m34 : 32|16@1+ (0.0001,0) [0|0] "V"  Receiver
 SG_ Cell104 m34 : 48|16@1+ (0.0001,0) [0|0] "V"  Receiver
 SG_ Cell105 m35 : 16|16@1+ (0.0001,0) [0|0] "V"  Receiver
 SG_ Cell106 m35 : 32|16@1+ (0.0001,0) [0|0] "V"  Receiver
 SG_ Cell107 m35 : 48|16@1+ (0.0001,0) [0|0] "V"  Receiver

EV_ MtoK: 0 [0|0] "" 0 1 DUMMY_NODE_VECTOR0 Vector__XXX;

EV_ MPH: 0 [0|0] "MPH" 0 2 DUMMY_NODE_VECTOR0 Vector__XXX;

EV_ Milage: 0 [0|0] "Mi" 0 3 DUMMY_NODE_VECTOR0 Vector__XXX;

CM_ BO_ 3221225472 "This is a message for not used signals, created by Vector CANdb++ DBC OLE DB Provider.";
CM_ SG_ 390 FrontTorqueActual186 "Torque at axle";
CM_ SG_ 390 FrontTorqueRequest186 "Torque at axle";
CM_ BO_ 918 "Note Rear Oil was 396 in older firmware";
CM_ BO_ 917 "Note Rear Oil was 396 in older firmware";
CM_ SG_ 472 RearTorqueRequest1D8 "driver requested torque";
CM_ SG_ 472 RearTorque1D8 "torque at motor";
CM_ SG_ 468 RAWTorqueFront1D4 "Axle torque 2 with 9/1 gearing";
CM_ SG_ 469 FrontTorqueRequest1D5 "torque at motor";
CM_ SG_ 469 FrontTorque1D5 "torque at motor";
CM_ SG_ 741 FrontPowerLimit2E5 "offset approximate";
CM_ SG_ 722 MinVoltage2D2 "test";
CM_ SG_ 612 ChargeLinePower264 "16 8 .08";
CM_ SG_ 612 ChargeLineCurrentLimit264 "32 8 .5";
CM_ SG_ 612 ChargeLineVoltage264 "0 12 .1";
CM_ SG_ 612 ChargeLineCurrent264 "24 8 .5";
CM_ SG_ 280 DriveState118 "Verify charge heat and fault";
CM_ SG_ 594 MaxHeatParked252 "test";
CM_ SG_ 599 UIspeedUnits257 "0-mph 1-kph";
CM_ SG_ 599 UIspeed_signed257 ".05 -25 x.08 -40 for kph";
CM_ SG_ 1029 VINB405 "last 7 of VIN (ASCII)";
CM_ SG_ 1029 VINC405 "part two of VIN (ASCII)";
CM_ SG_ 1029 VINA405 "four zeros then first 3 characters of VIN";
CM_ SG_ 886 TempInvPCB376 ".5 -20";
CM_ SG_ 886 TempInvCapbank376 ".5 -20";
CM_ SG_ 340 RAWTorqueRear154 "Axle torque 2 with 9/1 gearing";
CM_ SG_ 614 RearPowerLimit266 "offset approximate";
CM_ SG_ 614 RearHeatPowerOptimal266 "scale .125?";
CM_ SG_ 614 RearPower266 "electrical power";
CM_ SG_ 264 RearTorqueActual108 "Torque at axle";
CM_ SG_ 264 RearTorqueRequest108 "Torque at axle";
CM_ SG_ 306 RawBattCurrent132 "old offset 1000";
CM_ SG_ 306 SmoothBattCurrent132 "old offset 1000";
BA_DEF_ BO_  "GenMsgSendType" ENUM  "Cyclic","SendType1","SendType2","SendType3","SendType4","SendType5","SendType6","SendType7","SendType8","SendType9";
BA_DEF_ BO_  "GenMsgCycleTime" INT 0 0;
BA_DEF_  "BusType" STRING ;
BA_DEF_ BO_  "GenMsgAutoGenSnd" ENUM  "No","Yes";
BA_DEF_ BO_  "GenMsgAutoGenDsp" ENUM  "No","Yes";
BA_DEF_ SG_  "GenSigEnvVarType" ENUM  "int","float","undef";
BA_DEF_ BU_  "GenNodAutoGenSnd" ENUM  "No","Yes";
BA_DEF_ BU_  "GenNodAutoGenDsp" ENUM  "No","Yes";
BA_DEF_  "GenEnvVarEndingDsp" STRING ;
BA_DEF_  "GenEnvVarEndingSnd" STRING ;
BA_DEF_  "GenEnvVarPrefix" STRING ;
BA_DEF_  "Modified" STRING ;
BA_DEF_ SG_  "SystemSignalLongSymbol" STRING ;
BA_DEF_DEF_  "GenMsgSendType" "Cyclic";
BA_DEF_DEF_  "GenMsgCycleTime" 0;
BA_DEF_DEF_  "BusType" "";
BA_DEF_DEF_  "GenMsgAutoGenSnd" "Yes";
BA_DEF_DEF_  "GenMsgAutoGenDsp" "Yes";
BA_DEF_DEF_  "GenSigEnvVarType" "undef";
BA_DEF_DEF_  "GenNodAutoGenSnd" "Yes";
BA_DEF_DEF_  "GenNodAutoGenDsp" "Yes";
BA_DEF_DEF_  "GenEnvVarEndingDsp" "Dsp";
BA_DEF_DEF_  "GenEnvVarEndingSnd" "Snd";
BA_DEF_DEF_  "GenEnvVarPrefix" "Env";
BA_DEF_DEF_  "Modified" "JW2020Feb09";
BA_DEF_DEF_  "SystemSignalLongSymbol" "";
BA_ "BusType" "CAN";
BA_ "GenMsgCycleTime" BO_ 468 10;
BA_ "GenMsgCycleTime" BO_ 741 1000;
BA_ "GenMsgCycleTime" BO_ 962 50;
BA_ "GenMsgCycleTime" BO_ 822 1000;
BA_ "GenMsgCycleTime" BO_ 819 500;
BA_ "GenMsgCycleTime" BO_ 577 100;
BA_ "GenMsgCycleTime" BO_ 659 500;
BA_ "GenMsgCycleTime" BO_ 616 100;
BA_ "GenMsgCycleTime" BO_ 79 1000;
BA_ "GenMsgCycleTime" BO_ 978 1000;
BA_ "GenMsgCycleTime" BO_ 722 100;
BA_ "GenMsgCycleTime" BO_ 1345 100;
BA_ "GenMsgCycleTime" BO_ 580 100;
BA_ "GenMsgCycleTime" BO_ 532 100;
BA_ "GenMsgCycleTime" BO_ 533 1000;
BA_ "GenMsgCycleTime" BO_ 535 1000;
BA_ "GenMsgCycleTime" BO_ 801 1000;
BA_ "GenMsgCycleTime" BO_ 984 1000;
BA_ "GenMsgCycleTime" BO_ 609 100;
BA_ "GenMsgCycleTime" BO_ 297 10;
BA_ "GenMsgCycleTime" BO_ 612 100;
BA_ "GenMsgCycleTime" BO_ 548 100;
BA_ "GenMsgCycleTime" BO_ 280 10;
BA_ "GenMsgCycleTime" BO_ 530 100;
BA_ "GenMsgCycleTime" BO_ 850 1000;
BA_ "GenMsgCycleTime" BO_ 594 100;
BA_ "GenMsgCycleTime" BO_ 786 1000;
BA_ "GenMsgCycleTime" BO_ 658 100;
BA_ "GenMsgCycleTime" BO_ 599 20;
BA_ "GenMsgCycleTime" BO_ 1029 205;
BA_ "GenMsgCycleTime" BO_ 886 1000;
BA_ "GenMsgCycleTime" BO_ 340 10;
BA_ "GenMsgCycleTime" BO_ 950 1000;
BA_ "GenMsgCycleTime" BO_ 614 10;
BA_ "GenMsgCycleTime" BO_ 264 10;
BA_ "GenMsgCycleTime" BO_ 306 10;
BA_ "GenMsgCycleTime" BO_ 294 100;
BA_ "GenMsgCycleTime" BO_ 799 1000;
BA_ "GenMsgCycleTime" BO_ 1022 1000;
BA_ "GenMsgCycleTime" BO_ 2047 100;
BA_ "SystemSignalLongSymbol" SG_ 545 VCFrontvcrightHiCurrentLVState22 "VCFrontvcrightHiCurrentLVState221";
BA_ "SystemSignalLongSymbol" SG_ 691 VCRightptcHeaterReqAirpathBlocke "VCRightptcHeaterReqAirpathBlocked";
BA_ "SystemSignalLongSymbol" SG_ 918 FrontOilPumpOilTempEstConfident3 "FrontOilPumpOilTempEstConfident39";
BA_ "SystemSignalLongSymbol" SG_ 917 RearOilPumpOilTempEstConfident39 "RearOilPumpOilTempEstConfident395";
BA_ "SystemSignalLongSymbol" SG_ 2047 CFGpassengerOccupancySensorType7 "CFGpassengerOccupancySensorType7FF";
VAL_ 2005 DI_aebFaultReason 9 "DI_AEB_FAULT_ACCEL_OUT_OF_BOUNDS" 14 "DI_AEB_FAULT_ACCEL_REQ_INVALID" 5 "DI_AEB_FAULT_DAS_CONTROL_MIA" 15 "DI_AEB_FAULT_DAS_REQ_DI_UNAVAIL" 6 "DI_AEB_FAULT_DAS_SNA" 3 "DI_AEB_FAULT_EBR_FAULT" 1 "DI_AEB_FAULT_EPB_MIA" 10 "DI_AEB_FAULT_EPB_NOT_PARKED" 11 "DI_AEB_FAULT_ESP_FAULT" 12 "DI_AEB_FAULT_ESP_MIA" 13 "DI_AEB_FAULT_MIN_TIME_BTWN_EVENTS" 0 "DI_AEB_FAULT_NONE" 2 "DI_AEB_FAULT_PM_MIA" 8 "DI_AEB_FAULT_PM_REQUEST" 4 "DI_AEB_FAULT_SPEED_DELTA" 7 "DI_AEB_FAULT_VEL_EST_ABNORMAL" ;
VAL_ 2005 DI_aebUnavailableReason 1 "DI_AEB_UNAVAILABLE_CLOSURE" 5 "DI_AEB_UNAVAILABLE_DI_STATE" 6 "DI_AEB_UNAVAILABLE_EBR_UNAVAILABLE" 7 "DI_AEB_UNAVAILABLE_EPB" 2 "DI_AEB_UNAVAILABLE_GEAR" 8 "DI_AEB_UNAVAILABLE_HYSTERESIS" 4 "DI_AEB_UNAVAILABLE_NEGATIVE_SPEED" 0 "DI_AEB_UNAVAILABLE_NONE" 3 "DI_AEB_UNAVAILABLE_SKID" 9 "DI_AEB_UNAVAILABLE_TRACK_MODE" ;
VAL_ 2005 DI_brkStState 6 "BRKST_STATE_FINISHED" 1 "BRKST_STATE_IDLE" 5 "BRKST_STATE_INTERRUPTED" 4 "BRKST_STATE_RUNNING_PRESSED" 3 "BRKST_STATE_RUNNING_PRESSING" 2 "BRKST_STATE_RUNNING_UNPRESSED" 0 "BRKST_STATE_UNAVAILABLE" ;
VAL_ 2005 DI_fluxState 5 "DI_FLUXSTATE_ENABLED" 9 "DI_FLUXSTATE_FAULT" 4 "DI_FLUXSTATE_FLUX_DOWN" 3 "DI_FLUXSTATE_FLUX_UP" 6 "DI_FLUXSTATE_ICONTROL" 2 "DI_FLUXSTATE_STANDBY" 0 "DI_FLUXSTATE_START" 10 "DI_FLUXSTATE_STATIONARY_WASTE" 1 "DI_FLUXSTATE_TEST" 7 "DI_FLUXSTATE_VCONTROL" ;
VAL_ 2005 DI_gateDriveState 3 "PSTG_GD_STATE_CONFIGURED" 2 "PSTG_GD_STATE_CONFIGURING" 0 "PSTG_GD_STATE_INIT" 4 "PSTG_GD_STATE_NOT_CONFIGURED" 1 "PSTG_GD_STATE_SELFTEST" ;
VAL_ 2005 DI_gateDriveSupplyState 0 "PSTG_GD_SUPPLY_DOWN" 3 "PSTG_GD_SUPPLY_FALLING" 1 "PSTG_GD_SUPPLY_RISING" 2 "PSTG_GD_SUPPLY_UP" ;
VAL_ 2005 DI_immobilizerCondition 1 "DI_IMM_CONDITION_LEARNED" 0 "DI_IMM_CONDITION_VIRGIN_SNA" ;
VAL_ 2005 DI_magnetTempEst 0 "SNA" ;
VAL_ 2005 DI_motorType 8 "DI_MOTOR_F1A" 10 "DI_MOTOR_F1AC" 11 "DI_MOTOR_F2AB" 12 "DI_MOTOR_F2AC" 13 "DI_MOTOR_F2AD" 14 "DI_MOTOR_F2AE" 26 "DI_MOTOR_F2AE_AL" 15 "DI_MOTOR_F2APMSRM" 17 "DI_MOTOR_IM100A" 19 "DI_MOTOR_IM100B" 22 "DI_MOTOR_IM130C" 24 "DI_MOTOR_IM130D" 25 "DI_MOTOR_IM130D_AL" 20 "DI_MOTOR_IM216A" 3 "DI_MOTOR_M7M3" 4 "DI_MOTOR_M7M4" 5 "DI_MOTOR_M7M5" 7 "DI_MOTOR_M7M6" 6 "DI_MOTOR_M8A" 16 "DI_MOTOR_PM216A" 18 "DI_MOTOR_PM216B" 21 "DI_MOTOR_PM216C" 23 "DI_MOTOR_PM216D" 1 "DI_MOTOR_ROADSTER_BASE" 2 "DI_MOTOR_ROADSTER_SPORT" 0 "DI_MOTOR_SNA" 9 "DI_MOTOR_SSR1A" ;
VAL_ 2005 DI_oilPumpPhaseAdvance 255 "SNA" ;
VAL_ 2005 DI_oilPumpPhaseVoltage 255 "SNA" ;
VAL_ 2005 DI_oilPumpPressureEstimateMax 255 "SNA" ;
VAL_ 2005 DI_oilPumpPressureExpectedMin 255 "SNA" ;
VAL_ 2005 DI_opdUnavailableReason 1 "DI_OPD_UNAVAILABLE_DISABLED" 3 "DI_OPD_UNAVAILABLE_DI_SYS_STATE" 5 "DI_OPD_UNAVAILABLE_EPB_FAULT" 2 "DI_OPD_UNAVAILABLE_GEAR" 9 "DI_OPD_UNAVAILABLE_GRADE_ESTIMATE" 0 "DI_OPD_UNAVAILABLE_NONE" 11 "DI_OPD_UNAVAILABLE_PARKED" 4 "DI_OPD_UNAVAILABLE_SKID" 10 "DI_OPD_UNAVAILABLE_TORQUE_LIMIT" 6 "DI_OPD_UNAVAILABLE_TRACK_MODE" 8 "DI_OPD_UNAVAILABLE_TRACTION_CONTROL" 7 "DI_OPD_UNAVAILABLE_VELOCITY_ESTIMATE" ;
VAL_ 2005 DI_powerStageSafeState 2 "PSTG_SAFESTATE_3PS_HIGH" 3 "PSTG_SAFESTATE_3PS_LOW" 1 "PSTG_SAFESTATE_ALL_OFF" 0 "PSTG_SAFESTATE_NONE" ;
VAL_ 2005 DI_rotorOffsetLearningState 9 "ROL_NUM_STATES" 2 "ROL_STATE_ACCELERATE" 5 "ROL_STATE_CORRECT" 8 "ROL_STATE_DONE" 0 "ROL_STATE_INIT" 4 "ROL_STATE_MEASURE" 3 "ROL_STATE_SHIFT" 6 "ROL_STATE_VERIFY" 1 "ROL_STATE_WAIT" 7 "ROL_STATE_WRITE" ;
VAL_ 2005 DI_ssmState 5 "SSM_STATE_ABORT" 4 "SSM_STATE_ENABLE" 8 "SSM_STATE_FAULT" 2 "SSM_STATE_IDLE" 7 "SSM_STATE_RETRY" 3 "SSM_STATE_STANDBY" 0 "SSM_STATE_START" 1 "SSM_STATE_UNAVAILABLE" 6 "SSM_STATE_WAIT_FOR_RETRY" ;
VAL_ 2005 DI_tcMaxRequest 255 "SNA" ;
VAL_ 2005 DI_tcMinRequest 255 "SNA" ;
VAL_ 2005 DI_usmState 3 "USM_STATE_ABORT" 4 "USM_STATE_ENABLE" 5 "USM_STATE_FAULT" 2 "USM_STATE_RETRY" 1 "USM_STATE_STANDBY" 0 "USM_STATE_START" 6 "USM_STATE_UNAVAILABLE" 7 "USM_STATE_WAIT_FOR_RETRY" ;
VAL_ 2005 DI_velocityEstimatorState 4 "VE_STATE_BACKUP_MOTOR" 2 "VE_STATE_BACKUP_WHEELS_A" 3 "VE_STATE_BACKUP_WHEELS_B" 0 "VE_STATE_NOT_INITIALIZED" 1 "VE_STATE_WHEELS_NORMAL" ;
VAL_ 1879 DIS_fluxState 5 "DI_FLUXSTATE_ENABLED" 9 "DI_FLUXSTATE_FAULT" 4 "DI_FLUXSTATE_FLUX_DOWN" 3 "DI_FLUXSTATE_FLUX_UP" 6 "DI_FLUXSTATE_ICONTROL" 2 "DI_FLUXSTATE_STANDBY" 0 "DI_FLUXSTATE_START" 10 "DI_FLUXSTATE_STATIONARY_WASTE" 1 "DI_FLUXSTATE_TEST" 7 "DI_FLUXSTATE_VCONTROL" ;
VAL_ 1879 DIS_gateDriveState 3 "PSTG_GD_STATE_CONFIGURED" 2 "PSTG_GD_STATE_CONFIGURING" 0 "PSTG_GD_STATE_INIT" 4 "PSTG_GD_STATE_NOT_CONFIGURED" 1 "PSTG_GD_STATE_SELFTEST" ;
VAL_ 1879 DIS_gateDriveSupplyState 0 "PSTG_GD_SUPPLY_DOWN" 3 "PSTG_GD_SUPPLY_FALLING" 1 "PSTG_GD_SUPPLY_RISING" 2 "PSTG_GD_SUPPLY_UP" ;
VAL_ 1879 DIS_magnetTempEst 0 "SNA" ;
VAL_ 1879 DIS_motorType 8 "DI_MOTOR_F1A" 10 "DI_MOTOR_F1AC" 11 "DI_MOTOR_F2AB" 12 "DI_MOTOR_F2AC" 13 "DI_MOTOR_F2AD" 14 "DI_MOTOR_F2AE" 26 "DI_MOTOR_F2AE_AL" 15 "DI_MOTOR_F2APMSRM" 17 "DI_MOTOR_IM100A" 19 "DI_MOTOR_IM100B" 22 "DI_MOTOR_IM130C" 24 "DI_MOTOR_IM130D" 25 "DI_MOTOR_IM130D_AL" 20 "DI_MOTOR_IM216A" 3 "DI_MOTOR_M7M3" 4 "DI_MOTOR_M7M4" 5 "DI_MOTOR_M7M5" 7 "DI_MOTOR_M7M6" 6 "DI_MOTOR_M8A" 16 "DI_MOTOR_PM216A" 18 "DI_MOTOR_PM216B" 21 "DI_MOTOR_PM216C" 23 "DI_MOTOR_PM216D" 1 "DI_MOTOR_ROADSTER_BASE" 2 "DI_MOTOR_ROADSTER_SPORT" 0 "DI_MOTOR_SNA" 9 "DI_MOTOR_SSR1A" ;
VAL_ 1879 DIS_oilPumpPhaseAdvance 255 "SNA" ;
VAL_ 1879 DIS_oilPumpPhaseVoltage 255 "SNA" ;
VAL_ 1879 DIS_oilPumpPressureEstimateMax 255 "SNA" ;
VAL_ 1879 DIS_oilPumpPressureExpectedMin 255 "SNA" ;
VAL_ 1879 DIS_powerStageSafeState 2 "PSTG_SAFESTATE_3PS_HIGH" 3 "PSTG_SAFESTATE_3PS_LOW" 1 "PSTG_SAFESTATE_ALL_OFF" 0 "PSTG_SAFESTATE_NONE" ;
VAL_ 1879 DIS_tcMaxRequest 255 "SNA" ;
VAL_ 1879 DIS_tcMinRequest 255 "SNA" ;
VAL_ 1879 DIS_usmState 3 "USM_STATE_ABORT" 4 "USM_STATE_ENABLE" 5 "USM_STATE_FAULT" 2 "USM_STATE_RETRY" 1 "USM_STATE_STANDBY" 0 "USM_STATE_START" 6 "USM_STATE_UNAVAILABLE" 7 "USM_STATE_WAIT_FOR_RETRY" ;
VAL_ 1879 DIS_velocityEstimatorState 4 "VE_STATE_BACKUP_MOTOR" 2 "VE_STATE_BACKUP_WHEELS_A" 3 "VE_STATE_BACKUP_WHEELS_B" 0 "VE_STATE_NOT_INITIALIZED" 1 "VE_STATE_WHEELS_NORMAL" ;
VAL_ 694 DI_ptcStateUI 0 "FAULTED" 1 "BACKUP" 2 "ON" 3 "SNA" ;
VAL_ 694 DI_tractionControlModeUI 0 "NORMAL" 1 "SLIP_START" 2 "DEV_MODE_1" 3 "DEV_MODE_2" 4 "ROLLS_MODE" 5 "DYNO_MODE" ;
VAL_ 545 VCFrontvehiclePowerState221 0 "Off" 1 "Conditioning" 2 "Accessory" 3 "Drive" ;
VAL_ 753 VCFrontEFuseDebugStatusIndex 0 "VCRIGHT" 1 "VCLEFT" 2 "PCS" 3 "IBOOSTER" 4 "EPAS3P" 5 "EPAS3S" 6 "ESP_MOTOR" 7 "ESP_VALVE" 8 "AUTOPILOT_1" 9 "AUTOPILOT_2" 10 "SLEEP_BYPASS" 11 "UI" 12 "HEADLAMPS" 13 "VBAT_FUSED_HIGH_CURRENT" 14 "PUMPS" 15 "RAILS_A_B" 16 "MISC_RAILS" 17 "INVALID" ;
VAL_ 579 VCRighthvacACRunning 0 "OFF" 1 "ON" ;
VAL_ 579 VCRighthvacAirDistributionMode 0 "NONE" 1 "FLOOR" 2 "PANEL" 3 "PANEL_FLOOR" 4 "DEFROST" 5 "DEFROST_FLOOR" 6 "DEFROST_PANEL" 7 "DEFROST_PANEL_FLOOR" ;
VAL_ 579 VCRighthvacBlowerSegment 0 "OFF" 1 "1" 2 "2" 3 "3" 4 "4" 5 "5" 6 "6" 7 "7" 8 "8" 9 "9" 10 "10" 11 "11" ;
VAL_ 579 VCRighthvacPowerState 0 "OFF" 1 "ON" 2 "PRECONDITION" 3 "OVERHEAT_PROTECT_FANONLY" 4 "OVERHEAT_PROTECT" ;
VAL_ 579 VCRighthvacRecirc 0 "AUTO" 1 "RECIRC" 2 "FRESH" ;
VAL_ 579 VCRighthvacSecondRowState 0 "AUTO" 1 "OFF" 2 "LOW" 3 "MED" 4 "HIGH" ;
VAL_ 524 VCRighttempEvaporator 2047 "SNA" ;
VAL_ 524 VCRighttempEvaporatorTarget 255 "SNA" ;
VAL_ 691 VCRightlogging1HzIndex 0 "HVAC_TEMP_SENSORS_AND_ESTIMATES_1" 1 "HVAC_TEMP_SENSORS_AND_ESTIMATES_2" 2 "HVAC_HUMIDITY_HEATER" 3 "HVAC_STATUS_AIRFLOW" 4 "HVAC_COMFORT_SOLAR" 5 "HEATER_AND_DUCT_TARGETS" 6 "HVAC_ACTUATOR_VOLTAGES" 7 "HVAC_ACTUATOR_ENDSTOP" 8 "HVAC_ACTUATOR_ZEROSTOP" 9 "HVAC_MISCELLANEOUS_1" 10 "HVAC_MISCELLANEOUS_2" 11 "END" ;
VAL_ 691 VCRighttempDuctLeft 511 "SNA" ;
VAL_ 691 VCRighttempDuctRight 511 "SNA" ;
VAL_ 691 VCRighttempIncarCabinProbe 255 "SNA" ;
VAL_ 691 VCRighttempIncarCabinMid 250 "SNA" ;
VAL_ 691 VCRighttempIncarCabinDeep 255 "SNA" ;
VAL_ 691 VCRightcabinTempInteriorL2 240 "SNA" ;
VAL_ 691 VCRightcabinTempInteriorSunnyL2 240 "SNA" ;
VAL_ 691 VCRightcabinTempGlassRoof 255 "SNA" ;
VAL_ 691 VCRightcabinTempWindshield 255 "SNA" ;
VAL_ 691 VCRightcabinTempInterior 240 "SNA" ;
VAL_ 691 VCRightcabinTempInteriorSunny 240 "SNA" ;
VAL_ 691 VCRightcabinTempSideGlassLeft 255 "SNA" ;
VAL_ 691 VCRightcabinTempSideGlassRight 255 "SNA" ;
VAL_ 691 VCRightcabinTempBreathLevel 255 "SNA" ;
VAL_ 691 VCRighthvacAutoTransitionReason 0 "NONE" 1 "HUMIDITY_HIGH" 2 "HUMIDITY_MODERATE" 3 "HUMIDITY_LOW" 4 "TEMP_TARGET_BELOW_THRESHOLD" 5 "TEMP_TARGET_ABOVE_THRESHOLD" 6 "EXCESS_OCCUPANT_CONVECTION" 7 "OCCUPANT_CONVECTION_REQUIREMENT" 8 "TEMP_TARGET_LOW" 9 "DUCTS_COLD" 10 "BI_LEVEL_LANDING" 11 "DEFOG_OVERRIDE" 12 "SET_TEMP_LO" 13 "SET_TEMP_HI" 14 "CABIN_PURGE" 15 "EVAP_DRYING" 16 "HVAC_OFF" 17 "END" ;
VAL_ 691 VCRighthvacAirFlowModeRow1 0 "NONE" 1 "FLOOR" 2 "PANEL" 3 "PANEL_FLOOR" 4 "DEFROST" 5 "DEFROST_FLOOR" 6 "DEFROST_PANEL" 7 "DEFROST_PANEL_FLOOR" ;
VAL_ 691 VCRighthvacAirFlowModeRow2 0 "NONE" 1 "FLOOR" 2 "PANEL" 3 "PANEL_FLOOR" 4 "DEFROST" 5 "DEFROST_FLOOR" 6 "DEFROST_PANEL" 7 "DEFROST_PANEL_FLOOR" ;
VAL_ 691 VCRighthvacAirflowReason 0 "HVAC_OFF" 1 "MANUAL_FAN_SPEED" 2 "UI_SHORTCUT" 3 "CABIN_TEMPERATURE_CONTROL" 4 "MINIMUM_AUTO_AIRFLOW" 5 "STRATIFICATION_GLASS_ROOF" 6 "STRATIFICATION_INTERIOR_SURFACES" 7 "OCCUPANT_CONVECTION_REQUIREMENT" 8 "COLD_DUCT_LOCKOUT" 9 "CABIN_PURGE" 10 "CABIN_OVERHEAT_PROTECT" 11 "SCREEN_PROTECTION" 12 "EVAP_DRYING" 13 "NONE" ;
VAL_ 691 VCRightconvectionTargetLeft 255 "SNA" ;
VAL_ 691 VCRightconvectionTargetRight 255 "SNA" ;
VAL_ 691 VCRightconvectionDeliveredLeft 255 "SNA" ;
VAL_ 691 VCRightconvectionDeliveredRight 255 "SNA" ;
VAL_ 691 VCRightsolarLoadRightOccupant 255 "SNA" ;
VAL_ 691 VCRightsolarLoadLeftOccupant 255 "SNA" ;
VAL_ 691 VCRightsolarLoadOnVehicle 255 "SNA" ;
VAL_ 691 VCRighthvacDuctTargetLeft 255 "SNA" ;
VAL_ 691 VCRighthvacDuctTargetRight 255 "SNA" ;
VAL_ 691 VCRightsolarLoadOnVehFiltered 255 "SNA" ;
VAL_ 691 VCRightcabinTempInteriorL3 240 "SNA" ;
VAL_ 691 VCRightcabinTempInteriorSunnyL3 240 "SNA" ;
VAL_ 691 VCRightcabinTempTopPadAir 240 "SNA" ;
VAL_ 691 VCRighttempDuctModeledLeft 511 "SNA" ;
VAL_ 691 VCRighttempDuctModeledRight 511 "SNA" ;
VAL_ 691 VCRighttempHtrSurfaceModeledL 511 "SNA" ;
VAL_ 691 VCRighttempHtrSurfaceModeledR 511 "SNA" ;
VAL_ 705 VCFront10HzIndex 0 "COOLANT_PUMPS" 1 "THERMAL_FAN" 2 "FIVE_WAY_VALVE" 3 "REFRIGERANT_LV8907" 4 "COMPRESSOR" 5 "EXV_EVAP_SOLENOID_AIRFLOW" 6 "END" ;
VAL_ 705 VCfrontfiveWayValveMode 0 "SERIES" 1 "PARALLEL" ;
VAL_ 705 VCfrontcoolantTempBasedMode 0 "SERIES" 1 "PARALLEL" ;
VAL_ 705 VCfrontfiveWayValveState 0 "UNPOWERED" 1 "CALIBRATING" 2 "READY" 3 "FAULT" ;
VAL_ 705 VCfrontcompressorState 0 "STANDBY" 1 "READY" 2 "RUNNING" 3 "FAULT" ;
VAL_ 737 VCFrontStatusIndex 0 "BODY_CONTROLS" 1 "VEHICLE_AND_RAILS" 2 "HOMELINK" 3 "REFRIGERANT_SYSTEM" 4 "LV_BATTERY_DEBUG" 5 "INVALID" ;
VAL_ 737 VCfrontwiperSpeed 0 "SNA" 1 "OFF" 2 "1" 3 "2" 4 "3" 5 "4" 6 "5" 7 "LOW" 8 "HIGH" ;
VAL_ 737 VCfrontwiperPosition 0 "SNA" 1 "SERVICE" 2 "DEPRESSED_PARK" 3 "DELAYED_REST" 4 "WIPING" ;
VAL_ 737 VCfrontwiperState 0 "SNA" 1 "SERVICE" 2 "FAULT" 3 "DELAYED_REST" 4 "PARK" 5 "WASH" 6 "MOMENTARY_WIPE" 7 "INTERMITTENT_HIGH" 8 "INTERMITTENT_LOW" 9 "CONT_FAST" 10 "CONT_SLOW" 11 "INT_AUTO_LOW" 12 "INT_AUTO_HIGH" ;
VAL_ 737 VCfrontcrashDetectedType 0 "NONE" 1 "MINOR" 2 "SEVERE" ;
VAL_ 737 VCfrontcrashState 0 "IDLE" 1 "MINOR" 2 "SEVERE" ;
VAL_ 737 VCfrontairCompressorStatus 0 "OFF" 1 "ON" 2 "TURNING_OFF" 3 "TURNING_ON" 4 "FAULT" 5 "RETRY_AVAILABLE" 7 "SNA" ;
VAL_ 737 VCfronthomelinkCommStatus 0 "SNA" 1 "OFF" 2 "ON" 3 "FAULT" ;
VAL_ 897 VCFront1HzIndex 0 "COOLANT" 1 "CONDENSER_LOUVER_IC" 2 "ACTIVE_LOUVER_AND_BRUSHLESS_FETS" 3 "FIVE_WAY_VALVE" 4 "END" ;
VAL_ 897 VCFrontmodeTransitionID 0 "PARALLEL_F1_noFlowRequest" 1 "SERIES_F2_faultPumps" 2 "SERIES_1_drive_batteryWantsCool" 3 "SERIES_2_drive_batteryNeedsHeat" 4 "SERIES_3_drive_batteryWantsHeat" 5 "PARALLEL_2_drive_batteryWantsHeat" 6 "PARALLEL_3_drive_batteryWantsCool" 7 "PARALLEL_4_drive_batteryNeedsCool" 8 "SERIES_4_charge_batteryNeedsHeat" 9 "SERIES_5_charge_batteryWantsHeat" 10 "PARALLEL_5_charge_batteryWantsHeat" 11 "PARALLEL_6_charge_batteryWantsCool" 12 "SERIES_6_fastCharge_batteryNeedsHeat" 13 "SERIES_7_fastCharge_batteryWantsCool" 14 "PARALLEL_7_fastCharge_batteryWantsCool" 15 "PARALLEL_8_fastCharge_batteryWantsHeat" 16 "SERIES_8_preConditioning_batteryNeedsHeat" 17 "SERIES_9_drive_driveUnitThermalLimiting" 18 "PARALLEL_9_drive_batteryThermalLimiting" 19 "INIT" 20 "OVERRIDE" 21 "UNDEFINED" ;
VAL_ 897 VCFrontmodeDesired 0 "SERIES" 1 "PARALLEL" ;
VAL_ 897 VCFrontactiveLouverMotorState 0 "UNPOWERED" 1 "INIT_I2C" 2 "INIT_EEPROM" 3 "I2C_ERROR" 4 "READY" 5 "BRAKE" 6 "STALL" 7 "FAULT_MOTOR_DISCONNECTED" 8 "DRIVER_FAULT" ;
VAL_ 897 VCFrontactiveLouverState 0 "UNCALIBRATED" 1 "CALIB_CLOSE" 2 "CALIB_OPEN" 3 "READY" 4 "FAULTED" ;
VAL_ 897 VCFrontfiveWayValveRecalReason 0 "UNDEFINED" 1 "MAX_TRAVEL" 2 "GENERAL_FAULT" 3 "CALIBRATION_FAULT_NO_TRAVEL" 4 "SELF_TEST" 5 "MOTOR_FEEDBACK_INTERRUPTED" ;
VAL_ 553 GearLeverPosition229 4 "Full Up" 3 "Half Up" 2 "Full Down" 1 "Half Down" 0 "Center" ;
VAL_ 585 LeftStalkFRpos249 2 "Push" 1 "Pull" 0 "Center" ;
VAL_ 585 LeftStalkUDpos249 4 "Full Down" 3 "Half Down" 2 "Full Up" 1 "Half Up" 0 "Center" ;
VAL_ 918 FrontOilPumpState396 7 "OIL_PUMP_SNA" 6 "OIL_PUMP_FAULTED" 2 "OIL_PUMP_COLD_STARTUP" 1 "OIL_PUMP_ENABLE" 0 "OIL_PUMP_STANDBY" ;
VAL_ 917 RearOilPumpState395 7 "OIL_PUMP_SNA" 6 "OIL_PUMP_FAULTED" 2 "OIL_PUMP_COLD_STARTUP" 1 "OIL_PUMP_ENABLE" 0 "OIL_PUMP_STANDBY" ;
VAL_ 659 UICCWinchMode293 0 "IDLE" 1 "ENTER" 2 "EXIT" ;
VAL_ 659 UICCtractionControlMode293 5 "DynoMode" 4 "RollsMode" 3 "Dev2" 2 "Dev1" 1 "SlipStart" 0 "FullTraction" ;
VAL_ 659 UICCsteeringMode293 2 "Sport" 1 "Standard" 0 "Comfort" ;
VAL_ 659 UICCUnits293 0 "KM" 1 "MI" ;
VAL_ 659 UICCSuspensionLevel293 0 "NO_CHANGE_SNA" 1 "REQUEST_LOW_LEVEL" 2 "REQUEST_NORMAL_LEVEL" 3 "REQUEST_HIGH_LEVEL" 4 "REQUEST_VERY_HIGH_LEVEL" 5 "TOGGLE_JACK_MODE" 6 "SWITCH_DEFECT" 7 "REQUEST_VERY_LOW_LEVEL" ;
VAL_ 659 UICCautoParkRequest293 0 "NONE" 1 "PARK_LEFT_PARALLEL" 2 "PARK_LEFT_CROSS" 3 "PARK_RIGHT_PARALLEL" 4 "PARK_RIGHT_CROSS" 5 "PARALLEL_PULL_OUT_TO_LEFT" 6 "PARALLEL_PULL_OUT_TO_RIGHT" 7 "ABORT" 8 "COMPLETE" 9 "SEARCH" 10 "PAUSE" 11 "RESUME" 15 "SNA" ;
VAL_ 659 UICCfcwSensitivity293 0 "AEB_SENSITIVITY_EARLY" 1 "AEB_SENSITIVITY_AVERAGE" 2 "AEB_SENSITIVITY_LATE" 3 "SNA" ;
VAL_ 532 FCtype214 7 "error" 6 "other" 5 "MCEVSE" 4 "Combo" 3 "CCS" 2 "GB" 1 "CHADEMO" 0 "Supercharger" ;
VAL_ 535 FCclass217 2 "UrbanSC" 1 "Supercharger" 0 "err" ;
VAL_ 535 FCbrand217 1 "Tesla" 0 "err" ;
VAL_ 535 FCcoolingType217 2 "Liquid" 1 "Convection" 0 "err" ;
VAL_ 548 DCDCstate224 6 "Error" 5 "Shutdown" 4 "HVactive" 3 "Precharge" 2 "PrechargeStart" 1 "12vChg" 0 "Idle" ;
VAL_ 548 DCDCSubState224 0 "PWR_UP_INIT" 1 "STANDBY" 2 "12V_SUPPORT_ACTIVE" 3 "DIS_HVBUS" 4 "PCHG_FAST_DIS_HVBUS" 5 "PCHG_SLOW_DIS_HVBUS" 6 "PCHG_DWELL_CHARGE" 7 "PCHG_DWELL_WAIT" 8 "PCHG_DI_RECOVERY_WAIT" 9 "PCHG_ACTIVE" 10 "PCHG_FLT_FAST_DIS_HVBUS" 11 "SHUTDOWN" 12 "12V_SUPPORT_FAULTED" 13 "DIS_HVBUS_FAULTED" 14 "PCHG_FAULTED" 15 "CLEAR_FAULTS" 16 "FAULTED" 17 "NUM" ;
VAL_ 280 ImmobilizerState118 0 "Idle" 1 "Prepare" 2 "Begin Encrypt" 3 "Encrypt" 4 "Send Auth Response" 5 "Send No Go" ;
VAL_ 280 DriveState118 5 "Driving" 4 "Abort" 3 "Fault?" 2 "Standby" 1 "ChargeHeat" 0 "Idle" ;
VAL_ 280 TractionControl118 5 "Dyno Mode" 4 "Rolls Mode" 3 "Dev2" 2 "Dev1" 1 "Slip Start" 0 "Standard" ;
VAL_ 280 ParkingBrake118 2 "Disengage" 1 "Engage" 0 "Idle" ;
VAL_ 280 BrakeState118 1 "RegenBrake" ;
VAL_ 280 DIgear118 3 "Neutral" 7 "Idle" 1 "Park" 2 "Reverse" 4 "Drive" ;
VAL_ 280 BrakePedal118 1 "PedalBrake" ;
VAL_ 530 BMSstate212 3 "Charge" 1 "Drive" 0 "Idle" ;
VAL_ 530 BMSchargeStatus212 1 "Connected" 0 "Disconnected" ;
VAL_ 530 BMScontactors212 6 "err" 5 "err" 4 "Closed" 3 "Closing" 2 "Opening" 1 "Open" 0 "err" ;
VAL_ 599 UIspeedUnits257 1 "KPH" 0 "MPH" ;
VAL_ 552 EPBResmCaliperRequest228 3 "disengaging" 2 "engaging" 1 "idle" ;
VAL_ 552 EPBResmOperationTrigger228 22 "SuperPark" 6 "Released" 1 "ParkEngaged" ;
VAL_ 552 EPBRunitStatus228 10 "Disengaging" 8 "Engaging" 3 "ParkEngaged" 1 "DriveReleased" ;
VAL_ 648 EPBLesmCaliperRequest288 3 "disengaging" 2 "engaging" 1 "idle" ;
VAL_ 648 EPBLesmOperationTrigger288 22 "SuperPark" 6 "Released" 1 "ParkEngaged" ;
VAL_ 648 EPBLunitStatus288 10 "Disengaging" 8 "Engaging" 3 "ParkEngaged" 1 "DriveReleased" ;
VAL_ 2047 CFGrearDriveUnitType7FF 1 "Small Rear" 0 "Large Rear" ;
VAL_ 2047 CFGairSuspension7FF 2 "Adaptive" 1 "Standard" 0 "None" ;
VAL_ 2047 CFGdrivetrainType7FF 1 "AWD" 0 "RWD" ;
VAL_ 2047 CFGrightHandDrive7FF 1 "RHD" 0 "LHD" ;
VAL_ 2047 CFGpackEnergy7FF 3 "100kWh" 2 "62kWh" 1 "74kWh" 0 "50kWh" ;
VAL_ 2047 CFGbrakeHWType7FF 1 "BREMBO_P42_BREMBO_44MOC" 0 "BREMBO_P42_MANDO_43MOC" ;
VAL_ 2047 CFGinteriorLighting7FF 1 "Premium" 0 "Base" ;
VAL_ 2047 CFGheadlamps7FF 1 "Premium" 0 "Base" ;
VAL_ 2047 CFGaudioType7FF 2 "BaseWithPremium200" 1 "Premium" 0 "Base" ;
VAL_ 2047 CFGfrontSeatType7FF 1 "Premium" 0 "Base" ;
VAL_ 2047 CFGperformancePackage7FF 3 "Base Plus" 2 "Ludicrous" 1 "Performance" 0 "Base" ;
VAL_ 2047 CFGrearGlassType7FF 1 "TSA5_NOPET" 0 "NX" ;
VAL_ 2047 CFGroofType7FF 2 "Panoramic Sunroof" 1 "Fixed Glass" 0 "Metal" ;
VAL_ 2047 CFGautopilot7FF 4 "Basic" 3 "Full Self Driving" 2 "Enhanced" 1 "Highway" 0 "None" ;
VAL_ 2047 CFGsuperchargingAccess7FF 2 "Pay as you go" 1 "Free" 0 "None" ;
VAL_ 2047 CFGwheelType7FF 5 "Gemini 19 staggered" 4 "Gemini 19" 3 "Stiletto 20 staggered" 2 "Stiletto 20" 1 "Stiletto 19" 0 "Pinwheel 18" ;
VAL_ 2047 CFGexteriorColor7FF 6 "Pearl White" 5 "Deep Blue" 4 "4" 3 "Midnight Silver" 2 "Silver Metallic" 1 "Black" 0 "Red Multicoat" ;
VAL_ 2047 CFGrestraintsHardwareType7FF 23 "M3_EU_No_ECall" 22 "M3_EU_ECall" 21 "M3_NA" ;
VAL_ 2047 CFGchassisType7FF 2 "Model 3" 1 "Model X" 0 "Model S" ;
VAL_ 2047 CFGmapRegion7FF 8 "ME" 7 "KR" 6 "TW" 5 "JP" 4 "AU" 3 "CN" 2 "none" 1 "EU" 0 "US" ;
VAL_ 2047 CFGimmersiveAudio7FF 2 "Premium" 1 "Base" 0 "Disabled" ;
VAL_ 2047 CFGrearLightType7FF 1 "EU_CN" 0 "NA" ;
VAL_ 2047 CFGtrackModePackage7FF 1 "Performance" 0 "None" ;
VAL_ 2047 CFGroofGlassType7FF 1 "TSA5_NOPET" 0 "TSA3_PET" ;
VAL_ 2047 CFGfrontSeatReclinerHardware7FF 3 "LeftRight Reduced" 2 "Left Reduced" 1 "Right Reduced" 0 "Standard" ;
VAL_ 2047 CFGrefrigerantType7FF 2 "R1234YF" 1 "R134A" 0 "Default" ;
VAL_ 2047 CFGplcSupportType7FF 2 "Native charge port" 1 "Adapter" 0 "None" ;
VAL_ 2047 CFGsoftRange7FF 2 "93mi range" 1 "220mi range" 0 "Standard" ;
VAL_ 2047 CFGtireType7FF 5 "MICHELIN_SUMMER_20" 4 "CONTI_ALL_SEASON_19" 3 "HANKOOK_SUMMER_19" 2 "MICHELIN_SUMMER_18" 1 "MICHELIN_ALL_SEASON_18" 0 "Unknown" ;
VAL_ 2047 CFGdasHw7FF 4 "TESLA_AP3" 3 "PARKER_PASCAL_2_5" ;
VAL_ 2047 CFGtpmsType7FF 1 "TESLA_BLE" 0 "CONTI_2" ;
